VERSION ""

NS_ :

BS_:

BU_:BMS FCS VCU

BO_ 2550398993 BatP1_BMS_PowerSupplyInfo: 8 BMS
 SG_ P1_BMSPwrSuplVlt1 : 7|9@0+ (0.1,0) [0|50] "V" VCU
 SG_ P1_BMSPwrSuplVlt2 : 14|9@0+ (0.1,0) [0|50] "V" VCU
 SG_ P1_ChrgStationAuxPwrSuplVlt : 21|9@0+ (0.1,0) [0|50] "V" VCU
 SG_ P1_BMSKL15ON : 28|1@0+ (1,0) [0|1] "" VCU
 SG_ P1_DCStepState : 27|8@0+ (1,0) [0|255] "" VCU
 SG_ P1_ExtLvWakeup_28VOnly : 35|9@0+ (0.1,0) [0|50] "V" VCU

BO_ 2550464529 BatP1_BMS_PackUsageLimit: 8 BMS
 SG_ P1_PackVltUprLmt : 7|14@0+ (0.1,0) [0|1200] "V" VCU
 SG_ P1_PackVltLoLmt : 9|14@0+ (0.1,0) [0|1200] "V" VCU
 SG_ P1_PackMaxDschrgCrnt : 27|14@0+ (0.1,0) [0|1600] "A" VCU
 SG_ P1_PackMaxChrgCrnt : 45|14@0+ (0.1,0) [0|1600] "A" VCU

BO_ 2550530065 BatP1_BMS_PackPowerCapability: 8 BMS
 SG_ P1_PackDschrgPwrLmt : 7|10@0+ (1,0) [0|1000] "kW" VCU
 SG_ P1_PackDschrgPwrStat : 13|2@0+ (1,0) [0|3] "" VCU
 SG_ P1_PackChrgPwrLmt : 11|10@0+ (1,0) [0|1000] "kW" VCU
 SG_ P1_PackChrgPwrStat : 17|2@0+ (1,0) [0|3] "" VCU

BO_ 2550595601 BatP1_BMS_ChargingInfo: 8 BMS
 SG_ P1_ChrgrCplrStat : 7|1@0+ (1,0) [0|1] "" VCU
 SG_ P1_HVBattChrgSysStatus : 6|4@0+ (1,0) [0|15] "" VCU
 SG_ P1_DCChrgCrntCmd : 2|9@0+ (1,0) [0|500] "A" VCU
 SG_ P1_CC2Vlt : 9|8@0+ (0.1,0) [0|25] "V" VCU
 SG_ P1_DCRcptPosTemp : 17|9@0+ (0.5,-40) [-40|150] "C" VCU
 SG_ P1_DCRcptNegTemp : 24|9@0+ (0.5,-40) [-40|150] "C" VCU
 SG_ P1_Tm2FullChrg : 47|14@0+ (1,0) [0|65535] "min" VCU

BO_ 2550661137 BatP1_BMS_ThermalManagement: 8 BMS
 SG_ P1_Inlet1ClntTemp : 7|11@0+ (0.1,-40) [-40|150] "C" VCU
 SG_ P1_Inlet2ClntTemp : 12|11@0+ (0.1,-40) [-40|150] "C" VCU
 SG_ P1_Outlet1ClntTemp : 17|11@0+ (0.1,-40) [-40|150] "C" VCU
 SG_ P1_Outlet2ClntTemp : 38|11@0+ (0.1,-40) [-40|150] "C" VCU
 SG_ P1_TrgtClntTemp : 43|11@0+ (0.1,-40) [-40|150] "C" VCU
 SG_ P1_TrgtClntFlowRate : 48|9@0+ (0.2,0) [0|100] "C" VCU

BO_ 2550726673 BatP1_BMS_CellVoltMaxMin: 8 BMS
 SG_ P1_MaxCellVlt : 7|13@0+ (0.001,0) [0|5] "V" VCU
 SG_ P1_MaxCellVltNum : 10|9@0+ (1,0) [0|500] "" VCU
 SG_ P1_MinCellVlt : 17|13@0+ (0.001,0) [0|5] "V" VCU
 SG_ P1_MinCellVltNum : 36|9@0+ (1,0) [0|500] "" VCU
 SG_ P1_AvgCellVlt : 43|13@0+ (0.001,0) [0|5] "V" VCU

BO_ 2550792209 BatP1_BMS_CellTempMaxMin: 8 BMS
 SG_ P1_MaxCellTemp : 7|11@0+ (0.1,-40) [-40|150] "C" VCU
 SG_ P1_MaxCellTempNum : 12|9@0+ (1,0) [0|500] "" VCU
 SG_ P1_MinCellTemp : 19|11@0+ (0.1,-40) [-40|150] "C" VCU
 SG_ P1_MinCellTempNum : 24|9@0+ (1,0) [0|500] "" VCU
 SG_ P1_AvgCellTemp : 47|11@0+ (0.1,-40) [-40|150] "C" VCU

BO_ 2550857745 BatP1_BMS_PackFaultInfo1: 8 BMS
 SG_ P1_PackTotFltNum : 7|8@0+ (1,0) [0|200] "" VCU
 SG_ P1_CellOverVoltage : 15|2@0+ (1,0) [0|3] "" VCU
 SG_ P1_CellUnderVoltage : 13|2@0+ (1,0) [0|3] "" VCU
 SG_ P1_CellVoltageDiffHi : 11|1@0+ (1,0) [0|1] "" VCU
 SG_ P1_PackOverVoltage : 10|2@0+ (1,0) [0|3] "" VCU
 SG_ P1_PackUnderVoltage : 8|2@0+ (1,0) [0|3] "" VCU
 SG_ P1_CellOverTemp : 22|2@0+ (1,0) [0|3] "" VCU
 SG_ P1_CellTempLow : 20|1@0+ (1,0) [0|1] "" VCU
 SG_ P1_CellTempDiffHi : 19|1@0+ (1,0) [0|1] "" VCU
 SG_ P1_PackDschrgCrntHi : 18|2@0+ (1,0) [0|3] "" VCU
 SG_ P1_PackChrgCrntHi : 16|2@0+ (1,0) [0|3] "" VCU
 SG_ P1_PackCrnSnsr1OffsetHi : 30|1@0+ (1,0) [0|1] "" VCU
 SG_ P1_HVIsolFlt : 29|2@0+ (1,0) [0|3] "" VCU
 SG_ P1_HVILFlt : 27|1@0+ (1,0) [0|1] "" VCU
 SG_ P1_ThrmlRunaway : 26|1@0+ (1,0) [0|1] "" VCU
 SG_ P1_CellVoltInvalid : 25|1@0+ (1,0) [0|1] "" VCU
 SG_ P1_CellTempInvalid : 24|1@0+ (1,0) [0|1] "" VCU
 SG_ P1_DaisyChainComFlt : 39|1@0+ (1,0) [0|1] "" VCU
 SG_ P1_PackVoltRatFlt : 38|1@0+ (1,0) [0|1] "" VCU
 SG_ P1_CrntSnsr1Invalid : 37|1@0+ (1,0) [0|1] "" VCU
 SG_ P1_CrntSnsr1OOR : 36|1@0+ (1,0) [0|1] "" VCU
 SG_ P1_CrntSnsr2Invalid : 35|1@0+ (1,0) [0|1] "" VCU
 SG_ P1_CrntSnsr2OOR : 34|1@0+ (1,0) [0|1] "" VCU
 SG_ P1_PackCrnSnsr2OffsetHi : 33|1@0+ (1,0) [0|1] "" VCU
 SG_ P1_OutofEnergy : 32|1@0+ (1,0) [0|1] "" VCU
 SG_ P1_IsolDetCircErr : 47|1@0+ (1,0) [0|1] "" VCU
 SG_ P1_HVILCircShortToGND : 46|1@0+ (1,0) [0|1] "" VCU
 SG_ P1_HVILCircShortToPwr : 45|1@0+ (1,0) [0|1] "" VCU

BO_ 2550923281 BatP1_BMS_PackFaultInfo2: 8 BMS
 SG_ P1_MainPosCntctrStkClsd : 7|1@0+ (1,0) [0|1] "" VCU
 SG_ P1_MainPosCntctrStkOpn : 6|1@0+ (1,0) [0|1] "" VCU
 SG_ P1_MainNegCntctr1StkClsd : 5|1@0+ (1,0) [0|1] "" VCU
 SG_ P1_MainNegCntctr1StkOpn : 4|1@0+ (1,0) [0|1] "" VCU
 SG_ P1_MainNegCntctr2StkClsd : 3|1@0+ (1,0) [0|1] "" VCU
 SG_ P1_MainNegCntctr2StkOpn : 2|1@0+ (1,0) [0|1] "" VCU
 SG_ P1_PrechargTmOut : 1|1@0+ (1,0) [0|1] "" VCU
 SG_ P1_PrechrgCrntHi : 0|1@0+ (1,0) [0|1] "" VCU
 SG_ P1_ChrgCplrPosTempHi : 15|1@0+ (1,0) [0|1] "" VCU
 SG_ P1_ChrgCplrNegTempHi : 14|1@0+ (1,0) [0|1] "" VCU
 SG_ P1_BMSPwrSuplVlt1Hi : 13|1@0+ (1,0) [0|1] "" VCU
 SG_ P1_BMSPwrSuplVlt1Lo : 12|1@0+ (1,0) [0|1] "" VCU
 SG_ P1_BMSPwrSuplVlt2Hi : 11|1@0+ (1,0) [0|1] "" VCU
 SG_ P1_BMSPwrSuplVlt2Lo : 10|1@0+ (1,0) [0|1] "" VCU
 SG_ P1_CntctrCirPwrSuplVltLo : 9|1@0+ (1,0) [0|1] "" VCU
 SG_ P1_CntctrCirPwrSuplVltHi : 8|1@0+ (1,0) [0|1] "" VCU
 SG_ P1_CAN1BusOff : 23|1@0+ (1,0) [0|1] "" VCU
 SG_ P1_CAN1BusTmOut : 22|1@0+ (1,0) [0|1] "" VCU
 SG_ P1_CAN2BusOff : 21|1@0+ (1,0) [0|1] "" VCU
 SG_ P1_CAN2BusTmOut : 20|1@0+ (1,0) [0|1] "" VCU
 SG_ P1_CellBalCircTempHi : 19|1@0+ (1,0) [0|1] "" VCU
 SG_ P1_ClntInTempHi : 18|1@0+ (1,0) [0|1] "" VCU
 SG_ P1_ClntOutTempHi : 17|1@0+ (1,0) [0|1] "" VCU
 SG_ P1_CellExtrmUdrVolt : 16|1@0+ (1,0) [0|1] "" VCU
 SG_ P1_CellExtrmOvrVolt : 31|1@0+ (1,0) [0|1] "" VCU
 SG_ P1_Branch1DischrgCrntHi  : 30|1@0+ (1,0) [0|1] "" VCU
 SG_ P1_Branch2DischrgCrntHi  : 29|1@0+ (1,0) [0|1] "" VCU
 SG_ P1_Branch1ChrgCrntHi  : 28|1@0+ (1,0) [0|1] "" VCU
 SG_ P1_Branch2ChrgCrntHi  : 27|1@0+ (1,0) [0|1] "" VCU
 SG_ P1_InitFailed : 26|1@0+ (1,0) [0|1] "" VCU
 SG_ P1_PackErrCode : 25|10@0+ (1,0) [0|1023] "" VCU

BO_ 2550988817 BatP1_BMS_PackConfigInfo: 8 BMS
 SG_ P1_PackTotCellNum : 7|9@0+ (1,0) [0|500] "" VCU
 SG_ P1_PackTotCellTempSnsrNum : 14|9@0+ (1,0) [0|500] "" VCU

BO_ 2552299537 BatP1_BMS_BMSVersion: 8 BMS
 SG_ P1_BMSASWMajVerNum : 7|8@0+ (1,0) [0|9] "" VCU
 SG_ P1_BMSASWMinVerNum : 15|8@0+ (1,0) [0|99] "" VCU
 SG_ P1_BMSASWPatchVerNum : 23|8@0+ (1,0) [0|255] "" VCU
 SG_ P1_BMSBSWMajVerNum : 31|8@0+ (1,0) [0|9] "" VCU
 SG_ P1_BMSBSWMinVerNum : 39|8@0+ (1,0) [0|99] "" VCU
 SG_ P1_BMSBSWPatchVerNum : 47|8@0+ (1,0) [0|255] "" VCU

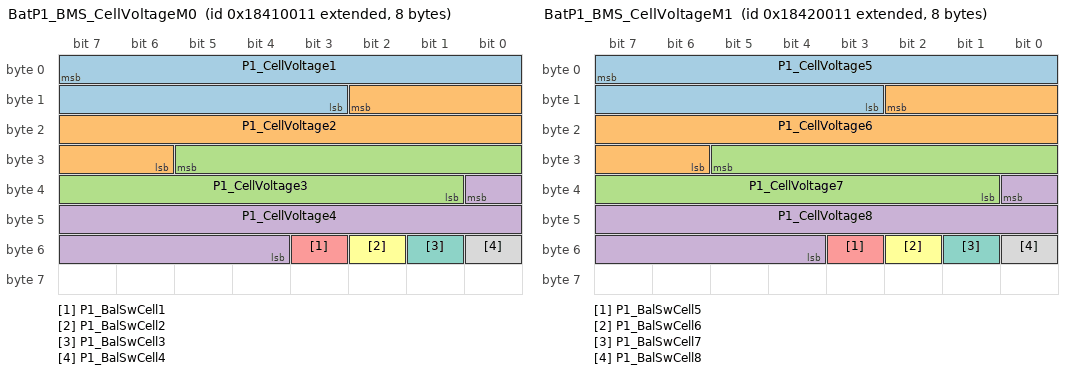
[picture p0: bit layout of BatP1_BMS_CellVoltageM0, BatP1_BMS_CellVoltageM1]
BO_ 2554396689 BatP1_BMS_CellVoltageM0: 8 BMS
 SG_ P1_CellVoltage1 : 7|13@0+ (0.001,0) [0|5] "V" VCU
 SG_ P1_CellVoltage2 : 10|13@0+ (0.001,0) [0|5] "V" VCU
 SG_ P1_CellVoltage3 : 29|13@0+ (0.001,0) [0|5] "V" VCU
 SG_ P1_CellVoltage4 : 32|13@0+ (0.001,0) [0|5] "V" VCU
 SG_ P1_BalSwCell1 : 51|1@0+ (1,0) [0|1] "" VCU
 SG_ P1_BalSwCell2 : 50|1@0+ (1,0) [0|1] "" VCU
 SG_ P1_BalSwCell3 : 49|1@0+ (1,0) [0|1] "" VCU
 SG_ P1_BalSwCell4 : 48|1@0+ (1,0) [0|1] "" VCU

BO_ 2554462225 BatP1_BMS_CellVoltageM1: 8 BMS
 SG_ P1_CellVoltage5 : 7|13@0+ (0.001,0) [0|5] "V" VCU
 SG_ P1_CellVoltage6 : 10|13@0+ (0.001,0) [0|5] "V" VCU
 SG_ P1_CellVoltage7 : 29|13@0+ (0.001,0) [0|5] "V" VCU
 SG_ P1_CellVoltage8 : 32|13@0+ (0.001,0) [0|5] "V" VCU
 SG_ P1_BalSwCell5 : 51|1@0+ (1,0) [0|1] "" VCU
 SG_ P1_BalSwCell6 : 50|1@0+ (1,0) [0|1] "" VCU
 SG_ P1_BalSwCell7 : 49|1@0+ (1,0) [0|1] "" VCU
 SG_ P1_BalSwCell8 : 48|1@0+ (1,0) [0|1] "" VCU

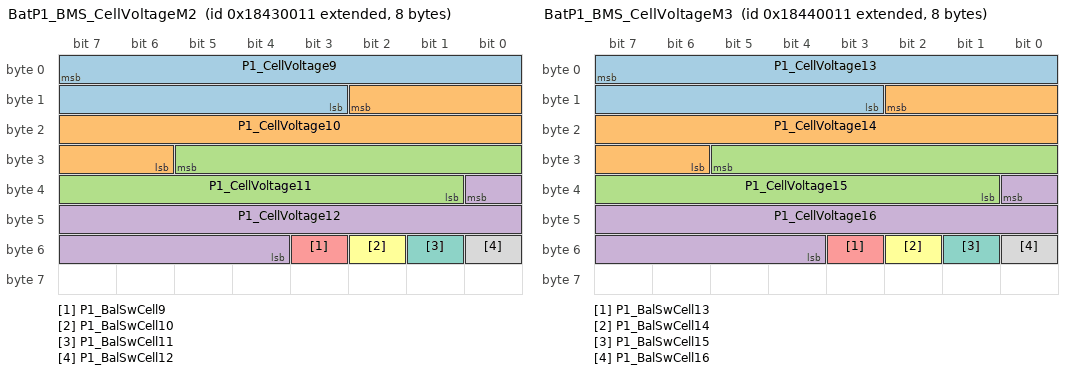
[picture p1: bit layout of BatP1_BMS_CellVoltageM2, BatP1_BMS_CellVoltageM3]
BO_ 2554527761 BatP1_BMS_CellVoltageM2: 8 BMS
 SG_ P1_CellVoltage9 : 7|13@0+ (0.001,0) [0|5] "V" VCU
 SG_ P1_CellVoltage10 : 10|13@0+ (0.001,0) [0|5] "V" VCU
 SG_ P1_CellVoltage11 : 29|13@0+ (0.001,0) [0|5] "V" VCU
 SG_ P1_CellVoltage12 : 32|13@0+ (0.001,0) [0|5] "V" VCU
 SG_ P1_BalSwCell9 : 51|1@0+ (1,0) [0|1] "" VCU
 SG_ P1_BalSwCell10 : 50|1@0+ (1,0) [0|1] "" VCU
 SG_ P1_BalSwCell11 : 49|1@0+ (1,0) [0|1] "" VCU
 SG_ P1_BalSwCell12 : 48|1@0+ (1,0) [0|1] "" VCU

BO_ 2554593297 BatP1_BMS_CellVoltageM3: 8 BMS
 SG_ P1_CellVoltage13 : 7|13@0+ (0.001,0) [0|5] "V" VCU
 SG_ P1_CellVoltage14 : 10|13@0+ (0.001,0) [0|5] "V" VCU
 SG_ P1_CellVoltage15 : 29|13@0+ (0.001,0) [0|5] "V" VCU
 SG_ P1_CellVoltage16 : 32|13@0+ (0.001,0) [0|5] "V" VCU
 SG_ P1_BalSwCell13 : 51|1@0+ (1,0) [0|1] "" VCU
 SG_ P1_BalSwCell14 : 50|1@0+ (1,0) [0|1] "" VCU
 SG_ P1_BalSwCell15 : 49|1@0+ (1,0) [0|1] "" VCU
 SG_ P1_BalSwCell16 : 48|1@0+ (1,0) [0|1] "" VCU

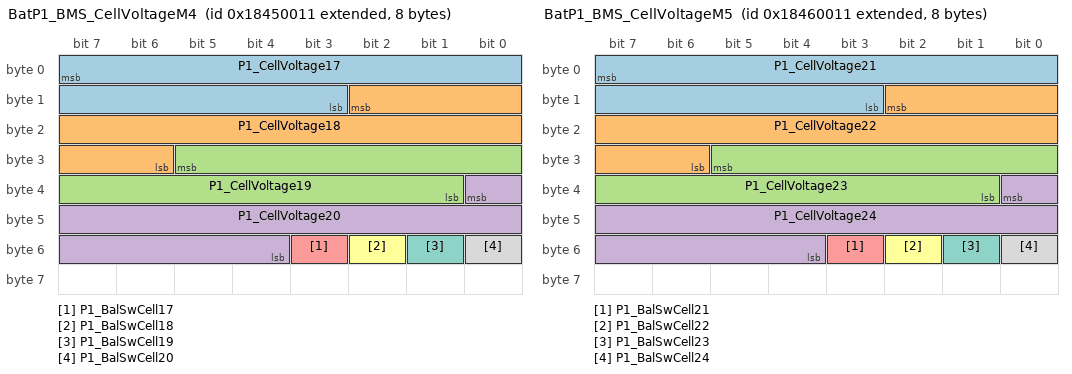
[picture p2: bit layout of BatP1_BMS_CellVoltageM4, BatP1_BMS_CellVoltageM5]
BO_ 2554658833 BatP1_BMS_CellVoltageM4: 8 BMS
 SG_ P1_CellVoltage17 : 7|13@0+ (0.001,0) [0|5] "V" VCU
 SG_ P1_CellVoltage18 : 10|13@0+ (0.001,0) [0|5] "V" VCU
 SG_ P1_CellVoltage19 : 29|13@0+ (0.001,0) [0|5] "V" VCU
 SG_ P1_CellVoltage20 : 32|13@0+ (0.001,0) [0|5] "V" VCU
 SG_ P1_BalSwCell17 : 51|1@0+ (1,0) [0|1] "" VCU
 SG_ P1_BalSwCell18 : 50|1@0+ (1,0) [0|1] "" VCU
 SG_ P1_BalSwCell19 : 49|1@0+ (1,0) [0|1] "" VCU
 SG_ P1_BalSwCell20 : 48|1@0+ (1,0) [0|1] "" VCU

BO_ 2554724369 BatP1_BMS_CellVoltageM5: 8 BMS
 SG_ P1_CellVoltage21 : 7|13@0+ (0.001,0) [0|5] "V" VCU
 SG_ P1_CellVoltage22 : 10|13@0+ (0.001,0) [0|5] "V" VCU
 SG_ P1_CellVoltage23 : 29|13@0+ (0.001,0) [0|5] "V" VCU
 SG_ P1_CellVoltage24 : 32|13@0+ (0.001,0) [0|5] "V" VCU
 SG_ P1_BalSwCell21 : 51|1@0+ (1,0) [0|1] "" VCU
 SG_ P1_BalSwCell22 : 50|1@0+ (1,0) [0|1] "" VCU
 SG_ P1_BalSwCell23 : 49|1@0+ (1,0) [0|1] "" VCU
 SG_ P1_BalSwCell24 : 48|1@0+ (1,0) [0|1] "" VCU

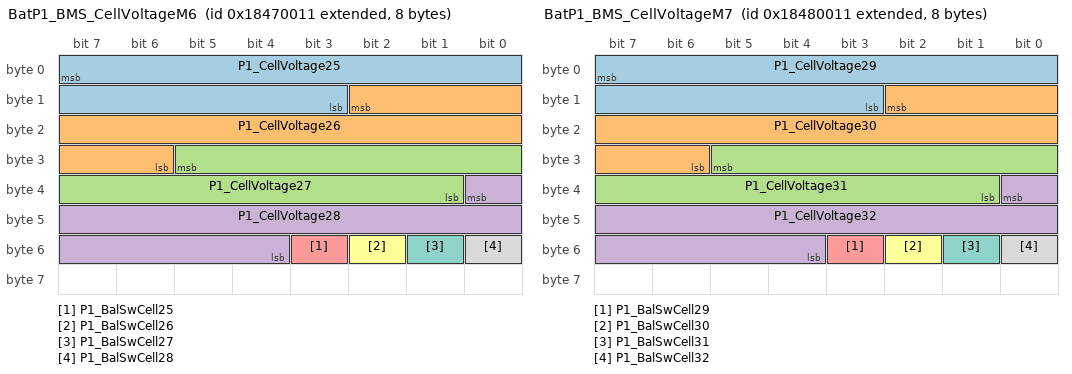
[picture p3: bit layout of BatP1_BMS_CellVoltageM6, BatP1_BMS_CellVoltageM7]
BO_ 2554789905 BatP1_BMS_CellVoltageM6: 8 BMS
 SG_ P1_CellVoltage25 : 7|13@0+ (0.001,0) [0|5] "V" VCU
 SG_ P1_CellVoltage26 : 10|13@0+ (0.001,0) [0|5] "V" VCU
 SG_ P1_CellVoltage27 : 29|13@0+ (0.001,0) [0|5] "V" VCU
 SG_ P1_CellVoltage28 : 32|13@0+ (0.001,0) [0|5] "V" VCU
 SG_ P1_BalSwCell25 : 51|1@0+ (1,0) [0|1] "" VCU
 SG_ P1_BalSwCell26 : 50|1@0+ (1,0) [0|1] "" VCU
 SG_ P1_BalSwCell27 : 49|1@0+ (1,0) [0|1] "" VCU
 SG_ P1_BalSwCell28 : 48|1@0+ (1,0) [0|1] "" VCU

BO_ 2554855441 BatP1_BMS_CellVoltageM7: 8 BMS
 SG_ P1_CellVoltage29 : 7|13@0+ (0.001,0) [0|5] "V" VCU
 SG_ P1_CellVoltage30 : 10|13@0+ (0.001,0) [0|5] "V" VCU
 SG_ P1_CellVoltage31 : 29|13@0+ (0.001,0) [0|5] "V" VCU
 SG_ P1_CellVoltage32 : 32|13@0+ (0.001,0) [0|5] "V" VCU
 SG_ P1_BalSwCell29 : 51|1@0+ (1,0) [0|1] "" VCU
 SG_ P1_BalSwCell30 : 50|1@0+ (1,0) [0|1] "" VCU
 SG_ P1_BalSwCell31 : 49|1@0+ (1,0) [0|1] "" VCU
 SG_ P1_BalSwCell32 : 48|1@0+ (1,0) [0|1] "" VCU

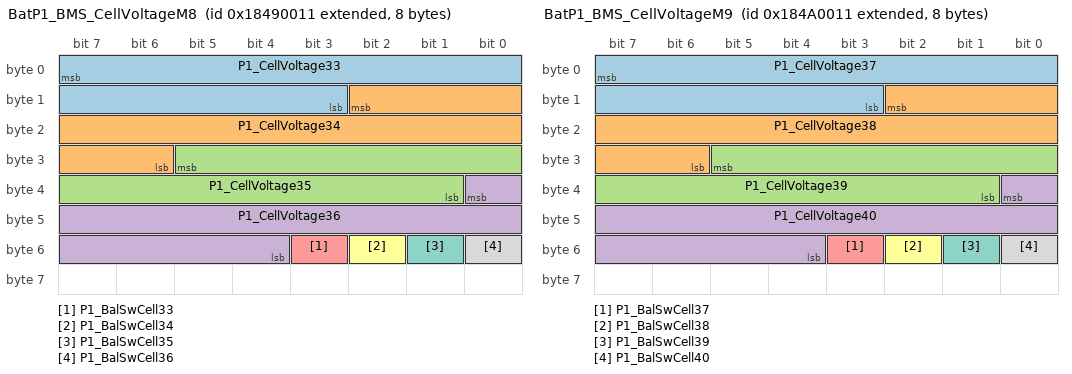
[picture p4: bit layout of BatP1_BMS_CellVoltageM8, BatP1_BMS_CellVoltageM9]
BO_ 2554920977 BatP1_BMS_CellVoltageM8: 8 BMS
 SG_ P1_CellVoltage33 : 7|13@0+ (0.001,0) [0|5] "V" VCU
 SG_ P1_CellVoltage34 : 10|13@0+ (0.001,0) [0|5] "V" VCU
 SG_ P1_CellVoltage35 : 29|13@0+ (0.001,0) [0|5] "V" VCU
 SG_ P1_CellVoltage36 : 32|13@0+ (0.001,0) [0|5] "V" VCU
 SG_ P1_BalSwCell33 : 51|1@0+ (1,0) [0|1] "" VCU
 SG_ P1_BalSwCell34 : 50|1@0+ (1,0) [0|1] "" VCU
 SG_ P1_BalSwCell35 : 49|1@0+ (1,0) [0|1] "" VCU
 SG_ P1_BalSwCell36 : 48|1@0+ (1,0) [0|1] "" VCU

BO_ 2554986513 BatP1_BMS_CellVoltageM9: 8 BMS
 SG_ P1_CellVoltage37 : 7|13@0+ (0.001,0) [0|5] "V" VCU
 SG_ P1_CellVoltage38 : 10|13@0+ (0.001,0) [0|5] "V" VCU
 SG_ P1_CellVoltage39 : 29|13@0+ (0.001,0) [0|5] "V" VCU
 SG_ P1_CellVoltage40 : 32|13@0+ (0.001,0) [0|5] "V" VCU
 SG_ P1_BalSwCell37 : 51|1@0+ (1,0) [0|1] "" VCU
 SG_ P1_BalSwCell38 : 50|1@0+ (1,0) [0|1] "" VCU
 SG_ P1_BalSwCell39 : 49|1@0+ (1,0) [0|1] "" VCU
 SG_ P1_BalSwCell40 : 48|1@0+ (1,0) [0|1] "" VCU

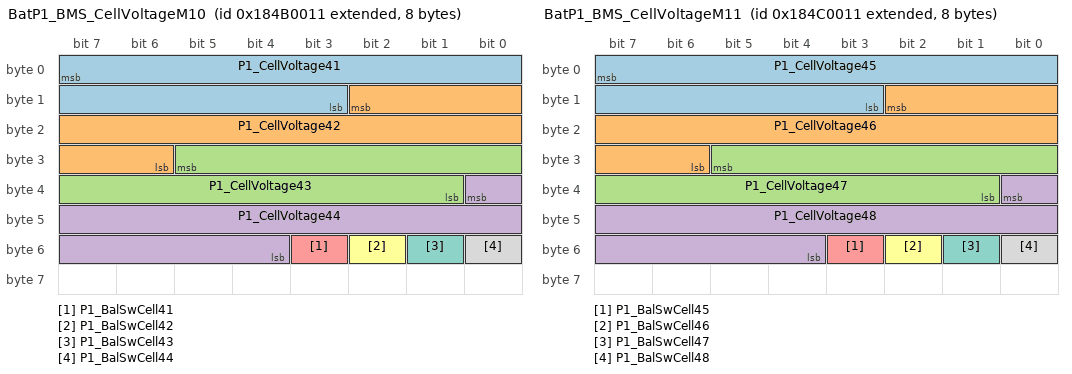
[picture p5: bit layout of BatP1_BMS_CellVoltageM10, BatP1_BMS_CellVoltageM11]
BO_ 2555052049 BatP1_BMS_CellVoltageM10: 8 BMS
 SG_ P1_CellVoltage41 : 7|13@0+ (0.001,0) [0|5] "V" VCU
 SG_ P1_CellVoltage42 : 10|13@0+ (0.001,0) [0|5] "V" VCU
 SG_ P1_CellVoltage43 : 29|13@0+ (0.001,0) [0|5] "V" VCU
 SG_ P1_CellVoltage44 : 32|13@0+ (0.001,0) [0|5] "V" VCU
 SG_ P1_BalSwCell41 : 51|1@0+ (1,0) [0|1] "" VCU
 SG_ P1_BalSwCell42 : 50|1@0+ (1,0) [0|1] "" VCU
 SG_ P1_BalSwCell43 : 49|1@0+ (1,0) [0|1] "" VCU
 SG_ P1_BalSwCell44 : 48|1@0+ (1,0) [0|1] "" VCU

BO_ 2555117585 BatP1_BMS_CellVoltageM11: 8 BMS
 SG_ P1_CellVoltage45 : 7|13@0+ (0.001,0) [0|5] "V" VCU
 SG_ P1_CellVoltage46 : 10|13@0+ (0.001,0) [0|5] "V" VCU
 SG_ P1_CellVoltage47 : 29|13@0+ (0.001,0) [0|5] "V" VCU
 SG_ P1_CellVoltage48 : 32|13@0+ (0.001,0) [0|5] "V" VCU
 SG_ P1_BalSwCell45 : 51|1@0+ (1,0) [0|1] "" VCU
 SG_ P1_BalSwCell46 : 50|1@0+ (1,0) [0|1] "" VCU
 SG_ P1_BalSwCell47 : 49|1@0+ (1,0) [0|1] "" VCU
 SG_ P1_BalSwCell48 : 48|1@0+ (1,0) [0|1] "" VCU

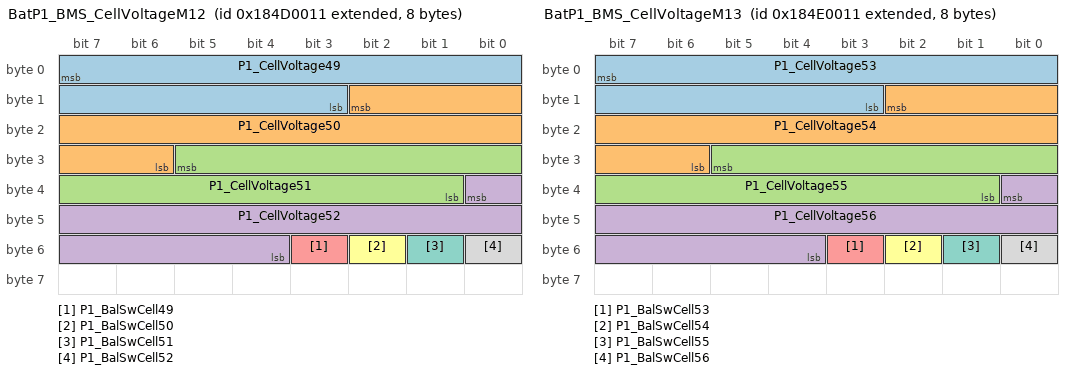
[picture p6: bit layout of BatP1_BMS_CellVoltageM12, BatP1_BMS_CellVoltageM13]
BO_ 2555183121 BatP1_BMS_CellVoltageM12: 8 BMS
 SG_ P1_CellVoltage49 : 7|13@0+ (0.001,0) [0|5] "V" VCU
 SG_ P1_CellVoltage50 : 10|13@0+ (0.001,0) [0|5] "V" VCU
 SG_ P1_CellVoltage51 : 29|13@0+ (0.001,0) [0|5] "V" VCU
 SG_ P1_CellVoltage52 : 32|13@0+ (0.001,0) [0|5] "V" VCU
 SG_ P1_BalSwCell49 : 51|1@0+ (1,0) [0|1] "" VCU
 SG_ P1_BalSwCell50 : 50|1@0+ (1,0) [0|1] "" VCU
 SG_ P1_BalSwCell51 : 49|1@0+ (1,0) [0|1] "" VCU
 SG_ P1_BalSwCell52 : 48|1@0+ (1,0) [0|1] "" VCU

BO_ 2555248657 BatP1_BMS_CellVoltageM13: 8 BMS
 SG_ P1_CellVoltage53 : 7|13@0+ (0.001,0) [0|5] "V" VCU
 SG_ P1_CellVoltage54 : 10|13@0+ (0.001,0) [0|5] "V" VCU
 SG_ P1_CellVoltage55 : 29|13@0+ (0.001,0) [0|5] "V" VCU
 SG_ P1_CellVoltage56 : 32|13@0+ (0.001,0) [0|5] "V" VCU
 SG_ P1_BalSwCell53 : 51|1@0+ (1,0) [0|1] "" VCU
 SG_ P1_BalSwCell54 : 50|1@0+ (1,0) [0|1] "" VCU
 SG_ P1_BalSwCell55 : 49|1@0+ (1,0) [0|1] "" VCU
 SG_ P1_BalSwCell56 : 48|1@0+ (1,0) [0|1] "" VCU

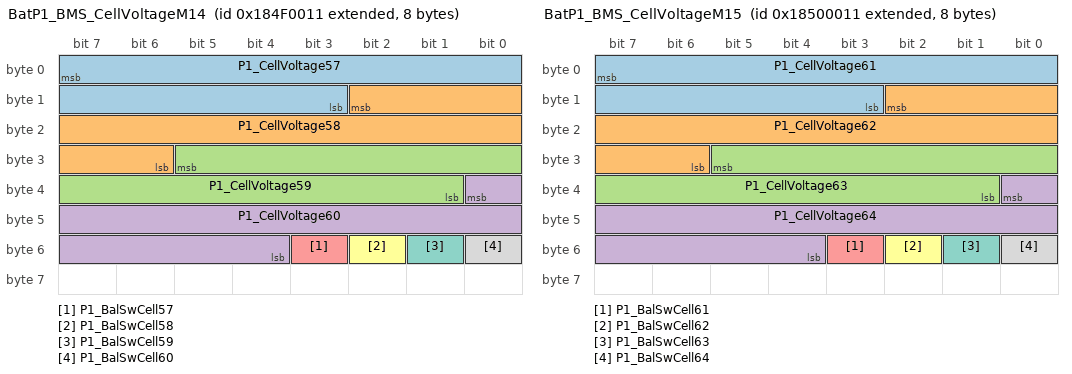
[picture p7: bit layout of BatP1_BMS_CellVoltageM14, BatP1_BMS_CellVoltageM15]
BO_ 2555314193 BatP1_BMS_CellVoltageM14: 8 BMS
 SG_ P1_CellVoltage57 : 7|13@0+ (0.001,0) [0|5] "V" VCU
 SG_ P1_CellVoltage58 : 10|13@0+ (0.001,0) [0|5] "V" VCU
 SG_ P1_CellVoltage59 : 29|13@0+ (0.001,0) [0|5] "V" VCU
 SG_ P1_CellVoltage60 : 32|13@0+ (0.001,0) [0|5] "V" VCU
 SG_ P1_BalSwCell57 : 51|1@0+ (1,0) [0|1] "" VCU
 SG_ P1_BalSwCell58 : 50|1@0+ (1,0) [0|1] "" VCU
 SG_ P1_BalSwCell59 : 49|1@0+ (1,0) [0|1] "" VCU
 SG_ P1_BalSwCell60 : 48|1@0+ (1,0) [0|1] "" VCU

BO_ 2555379729 BatP1_BMS_CellVoltageM15: 8 BMS
 SG_ P1_CellVoltage61 : 7|13@0+ (0.001,0) [0|5] "V" VCU
 SG_ P1_CellVoltage62 : 10|13@0+ (0.001,0) [0|5] "V" VCU
 SG_ P1_CellVoltage63 : 29|13@0+ (0.001,0) [0|5] "V" VCU
 SG_ P1_CellVoltage64 : 32|13@0+ (0.001,0) [0|5] "V" VCU
 SG_ P1_BalSwCell61 : 51|1@0+ (1,0) [0|1] "" VCU
 SG_ P1_BalSwCell62 : 50|1@0+ (1,0) [0|1] "" VCU
 SG_ P1_BalSwCell63 : 49|1@0+ (1,0) [0|1] "" VCU
 SG_ P1_BalSwCell64 : 48|1@0+ (1,0) [0|1] "" VCU

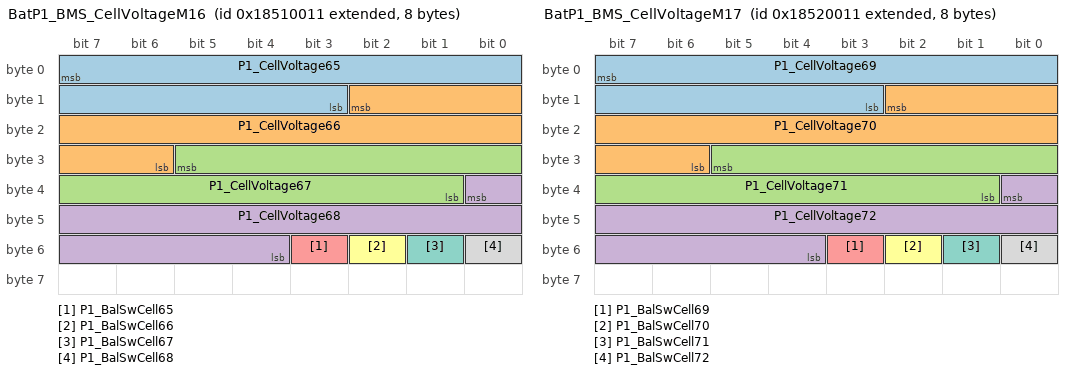
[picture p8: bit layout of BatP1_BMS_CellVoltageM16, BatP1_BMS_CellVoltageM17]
BO_ 2555445265 BatP1_BMS_CellVoltageM16: 8 BMS
 SG_ P1_CellVoltage65 : 7|13@0+ (0.001,0) [0|5] "V" VCU
 SG_ P1_CellVoltage66 : 10|13@0+ (0.001,0) [0|5] "V" VCU
 SG_ P1_CellVoltage67 : 29|13@0+ (0.001,0) [0|5] "V" VCU
 SG_ P1_CellVoltage68 : 32|13@0+ (0.001,0) [0|5] "V" VCU
 SG_ P1_BalSwCell65 : 51|1@0+ (1,0) [0|1] "" VCU
 SG_ P1_BalSwCell66 : 50|1@0+ (1,0) [0|1] "" VCU
 SG_ P1_BalSwCell67 : 49|1@0+ (1,0) [0|1] "" VCU
 SG_ P1_BalSwCell68 : 48|1@0+ (1,0) [0|1] "" VCU

BO_ 2555510801 BatP1_BMS_CellVoltageM17: 8 BMS
 SG_ P1_CellVoltage69 : 7|13@0+ (0.001,0) [0|5] "V" VCU
 SG_ P1_CellVoltage70 : 10|13@0+ (0.001,0) [0|5] "V" VCU
 SG_ P1_CellVoltage71 : 29|13@0+ (0.001,0) [0|5] "V" VCU
 SG_ P1_CellVoltage72 : 32|13@0+ (0.001,0) [0|5] "V" VCU
 SG_ P1_BalSwCell69 : 51|1@0+ (1,0) [0|1] "" VCU
 SG_ P1_BalSwCell70 : 50|1@0+ (1,0) [0|1] "" VCU
 SG_ P1_BalSwCell71 : 49|1@0+ (1,0) [0|1] "" VCU
 SG_ P1_BalSwCell72 : 48|1@0+ (1,0) [0|1] "" VCU

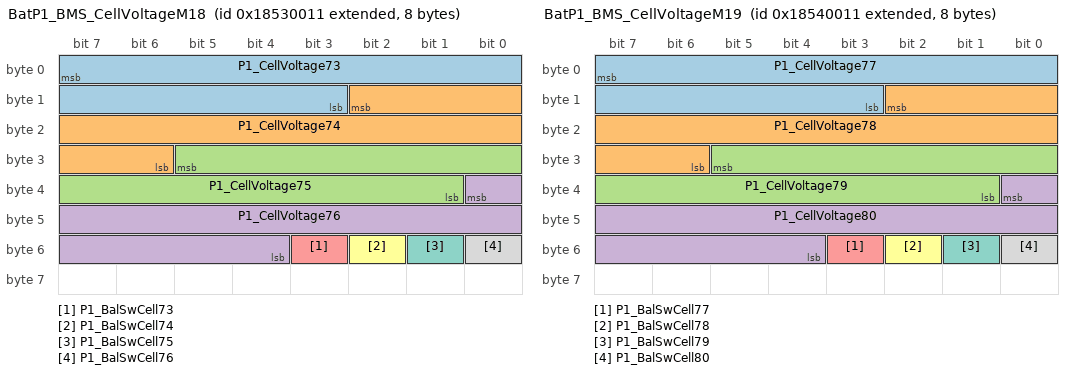
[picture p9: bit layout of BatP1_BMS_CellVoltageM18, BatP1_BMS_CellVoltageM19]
BO_ 2555576337 BatP1_BMS_CellVoltageM18: 8 BMS
 SG_ P1_CellVoltage73 : 7|13@0+ (0.001,0) [0|5] "V" VCU
 SG_ P1_CellVoltage74 : 10|13@0+ (0.001,0) [0|5] "V" VCU
 SG_ P1_CellVoltage75 : 29|13@0+ (0.001,0) [0|5] "V" VCU
 SG_ P1_CellVoltage76 : 32|13@0+ (0.001,0) [0|5] "V" VCU
 SG_ P1_BalSwCell73 : 51|1@0+ (1,0) [0|1] "" VCU
 SG_ P1_BalSwCell74 : 50|1@0+ (1,0) [0|1] "" VCU
 SG_ P1_BalSwCell75 : 49|1@0+ (1,0) [0|1] "" VCU
 SG_ P1_BalSwCell76 : 48|1@0+ (1,0) [0|1] "" VCU

BO_ 2555641873 BatP1_BMS_CellVoltageM19: 8 BMS
 SG_ P1_CellVoltage77 : 7|13@0+ (0.001,0) [0|5] "V" VCU
 SG_ P1_CellVoltage78 : 10|13@0+ (0.001,0) [0|5] "V" VCU
 SG_ P1_CellVoltage79 : 29|13@0+ (0.001,0) [0|5] "V" VCU
 SG_ P1_CellVoltage80 : 32|13@0+ (0.001,0) [0|5] "V" VCU
 SG_ P1_BalSwCell77 : 51|1@0+ (1,0) [0|1] "" VCU
 SG_ P1_BalSwCell78 : 50|1@0+ (1,0) [0|1] "" VCU
 SG_ P1_BalSwCell79 : 49|1@0+ (1,0) [0|1] "" VCU
 SG_ P1_BalSwCell80 : 48|1@0+ (1,0) [0|1] "" VCU

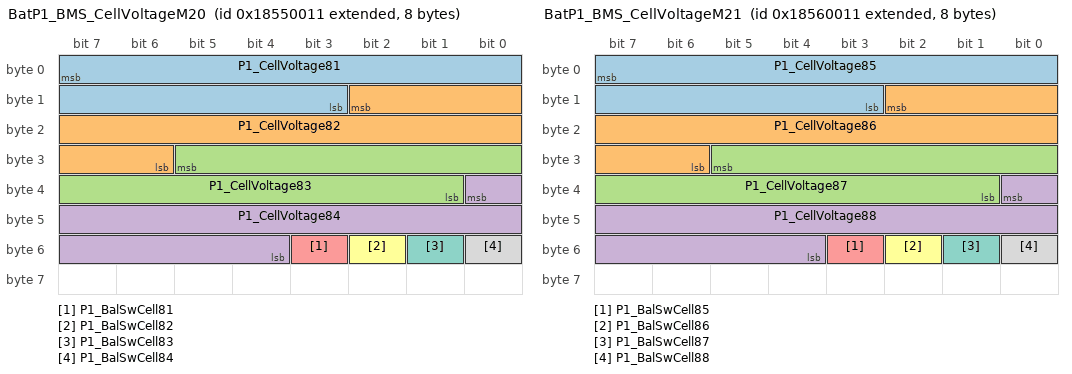
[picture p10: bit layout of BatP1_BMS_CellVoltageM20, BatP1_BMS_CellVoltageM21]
BO_ 2555707409 BatP1_BMS_CellVoltageM20: 8 BMS
 SG_ P1_CellVoltage81 : 7|13@0+ (0.001,0) [0|5] "V" VCU
 SG_ P1_CellVoltage82 : 10|13@0+ (0.001,0) [0|5] "V" VCU
 SG_ P1_CellVoltage83 : 29|13@0+ (0.001,0) [0|5] "V" VCU
 SG_ P1_CellVoltage84 : 32|13@0+ (0.001,0) [0|5] "V" VCU
 SG_ P1_BalSwCell81 : 51|1@0+ (1,0) [0|1] "" VCU
 SG_ P1_BalSwCell82 : 50|1@0+ (1,0) [0|1] "" VCU
 SG_ P1_BalSwCell83 : 49|1@0+ (1,0) [0|1] "" VCU
 SG_ P1_BalSwCell84 : 48|1@0+ (1,0) [0|1] "" VCU

BO_ 2555772945 BatP1_BMS_CellVoltageM21: 8 BMS
 SG_ P1_CellVoltage85 : 7|13@0+ (0.001,0) [0|5] "V" VCU
 SG_ P1_CellVoltage86 : 10|13@0+ (0.001,0) [0|5] "V" VCU
 SG_ P1_CellVoltage87 : 29|13@0+ (0.001,0) [0|5] "V" VCU
 SG_ P1_CellVoltage88 : 32|13@0+ (0.001,0) [0|5] "V" VCU
 SG_ P1_BalSwCell85 : 51|1@0+ (1,0) [0|1] "" VCU
 SG_ P1_BalSwCell86 : 50|1@0+ (1,0) [0|1] "" VCU
 SG_ P1_BalSwCell87 : 49|1@0+ (1,0) [0|1] "" VCU
 SG_ P1_BalSwCell88 : 48|1@0+ (1,0) [0|1] "" VCU

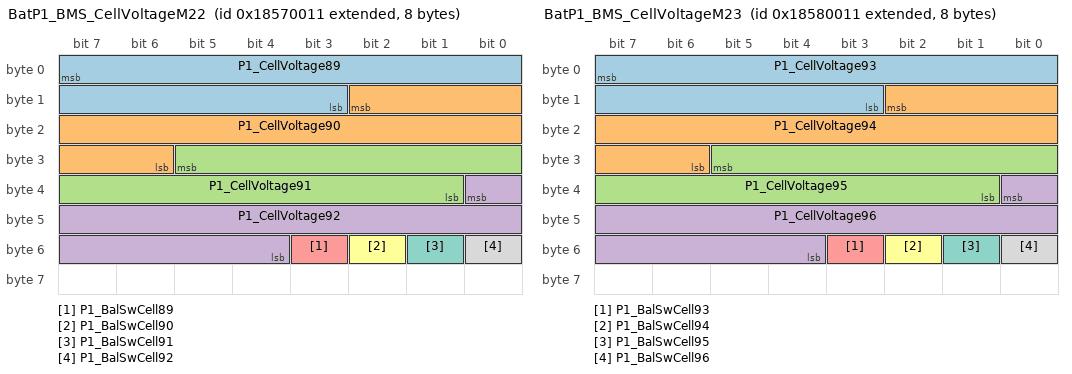
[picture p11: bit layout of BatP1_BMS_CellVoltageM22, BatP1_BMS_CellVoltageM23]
BO_ 2555838481 BatP1_BMS_CellVoltageM22: 8 BMS
 SG_ P1_CellVoltage89 : 7|13@0+ (0.001,0) [0|5] "V" VCU
 SG_ P1_CellVoltage90 : 10|13@0+ (0.001,0) [0|5] "V" VCU
 SG_ P1_CellVoltage91 : 29|13@0+ (0.001,0) [0|5] "V" VCU
 SG_ P1_CellVoltage92 : 32|13@0+ (0.001,0) [0|5] "V" VCU
 SG_ P1_BalSwCell89 : 51|1@0+ (1,0) [0|1] "" VCU
 SG_ P1_BalSwCell90 : 50|1@0+ (1,0) [0|1] "" VCU
 SG_ P1_BalSwCell91 : 49|1@0+ (1,0) [0|1] "" VCU
 SG_ P1_BalSwCell92 : 48|1@0+ (1,0) [0|1] "" VCU

BO_ 2555904017 BatP1_BMS_CellVoltageM23: 8 BMS
 SG_ P1_CellVoltage93 : 7|13@0+ (0.001,0) [0|5] "V" VCU
 SG_ P1_CellVoltage94 : 10|13@0+ (0.001,0) [0|5] "V" VCU
 SG_ P1_CellVoltage95 : 29|13@0+ (0.001,0) [0|5] "V" VCU
 SG_ P1_CellVoltage96 : 32|13@0+ (0.001,0) [0|5] "V" VCU
 SG_ P1_BalSwCell93 : 51|1@0+ (1,0) [0|1] "" VCU
 SG_ P1_BalSwCell94 : 50|1@0+ (1,0) [0|1] "" VCU
 SG_ P1_BalSwCell95 : 49|1@0+ (1,0) [0|1] "" VCU
 SG_ P1_BalSwCell96 : 48|1@0+ (1,0) [0|1] "" VCU

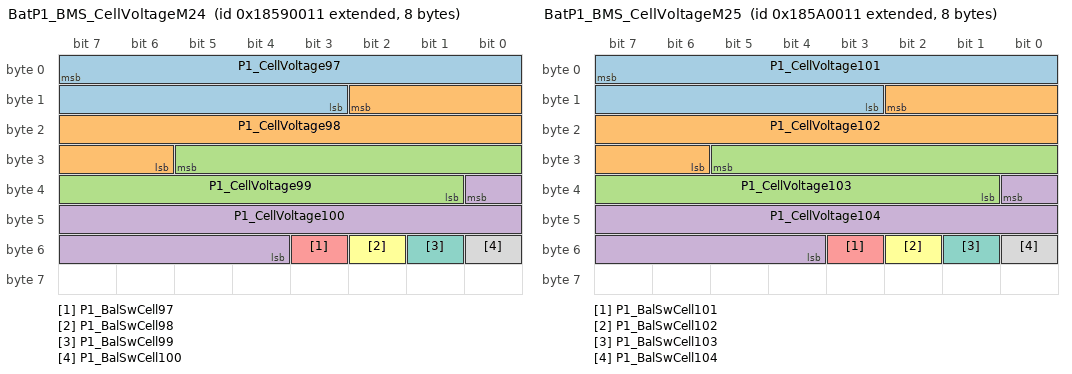
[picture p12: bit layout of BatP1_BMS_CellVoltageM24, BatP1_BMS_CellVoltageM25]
BO_ 2555969553 BatP1_BMS_CellVoltageM24: 8 BMS
 SG_ P1_CellVoltage97 : 7|13@0+ (0.001,0) [0|5] "V" VCU
 SG_ P1_CellVoltage98 : 10|13@0+ (0.001,0) [0|5] "V" VCU
 SG_ P1_CellVoltage99 : 29|13@0+ (0.001,0) [0|5] "V" VCU
 SG_ P1_CellVoltage100 : 32|13@0+ (0.001,0) [0|5] "V" VCU
 SG_ P1_BalSwCell97 : 51|1@0+ (1,0) [0|1] "" VCU
 SG_ P1_BalSwCell98 : 50|1@0+ (1,0) [0|1] "" VCU
 SG_ P1_BalSwCell99 : 49|1@0+ (1,0) [0|1] "" VCU
 SG_ P1_BalSwCell100 : 48|1@0+ (1,0) [0|1] "" VCU

BO_ 2556035089 BatP1_BMS_CellVoltageM25: 8 BMS
 SG_ P1_CellVoltage101 : 7|13@0+ (0.001,0) [0|5] "V" VCU
 SG_ P1_CellVoltage102 : 10|13@0+ (0.001,0) [0|5] "V" VCU
 SG_ P1_CellVoltage103 : 29|13@0+ (0.001,0) [0|5] "V" VCU
 SG_ P1_CellVoltage104 : 32|13@0+ (0.001,0) [0|5] "V" VCU
 SG_ P1_BalSwCell101 : 51|1@0+ (1,0) [0|1] "" VCU
 SG_ P1_BalSwCell102 : 50|1@0+ (1,0) [0|1] "" VCU
 SG_ P1_BalSwCell103 : 49|1@0+ (1,0) [0|1] "" VCU
 SG_ P1_BalSwCell104 : 48|1@0+ (1,0) [0|1] "" VCU

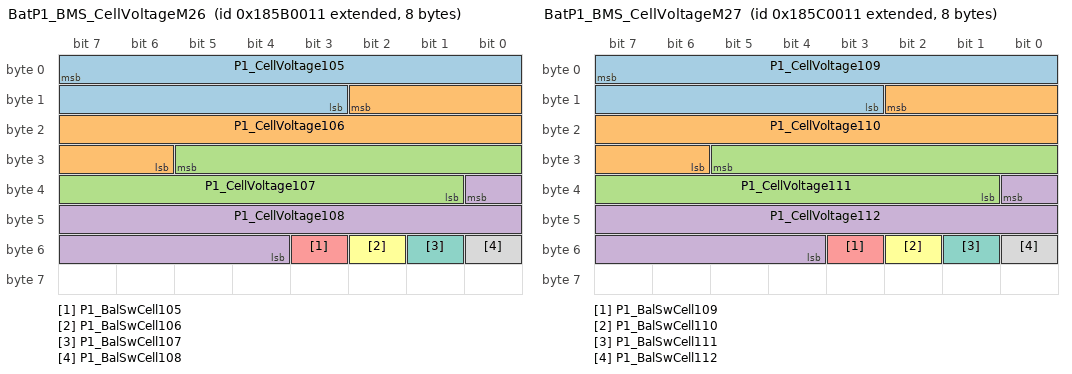
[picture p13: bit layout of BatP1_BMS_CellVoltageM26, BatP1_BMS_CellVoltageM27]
BO_ 2556100625 BatP1_BMS_CellVoltageM26: 8 BMS
 SG_ P1_CellVoltage105 : 7|13@0+ (0.001,0) [0|5] "V" VCU
 SG_ P1_CellVoltage106 : 10|13@0+ (0.001,0) [0|5] "V" VCU
 SG_ P1_CellVoltage107 : 29|13@0+ (0.001,0) [0|5] "V" VCU
 SG_ P1_CellVoltage108 : 32|13@0+ (0.001,0) [0|5] "V" VCU
 SG_ P1_BalSwCell105 : 51|1@0+ (1,0) [0|1] "" VCU
 SG_ P1_BalSwCell106 : 50|1@0+ (1,0) [0|1] "" VCU
 SG_ P1_BalSwCell107 : 49|1@0+ (1,0) [0|1] "" VCU
 SG_ P1_BalSwCell108 : 48|1@0+ (1,0) [0|1] "" VCU

BO_ 2556166161 BatP1_BMS_CellVoltageM27: 8 BMS
 SG_ P1_CellVoltage109 : 7|13@0+ (0.001,0) [0|5] "V" VCU
 SG_ P1_CellVoltage110 : 10|13@0+ (0.001,0) [0|5] "V" VCU
 SG_ P1_CellVoltage111 : 29|13@0+ (0.001,0) [0|5] "V" VCU
 SG_ P1_CellVoltage112 : 32|13@0+ (0.001,0) [0|5] "V" VCU
 SG_ P1_BalSwCell109 : 51|1@0+ (1,0) [0|1] "" VCU
 SG_ P1_BalSwCell110 : 50|1@0+ (1,0) [0|1] "" VCU
 SG_ P1_BalSwCell111 : 49|1@0+ (1,0) [0|1] "" VCU
 SG_ P1_BalSwCell112 : 48|1@0+ (1,0) [0|1] "" VCU

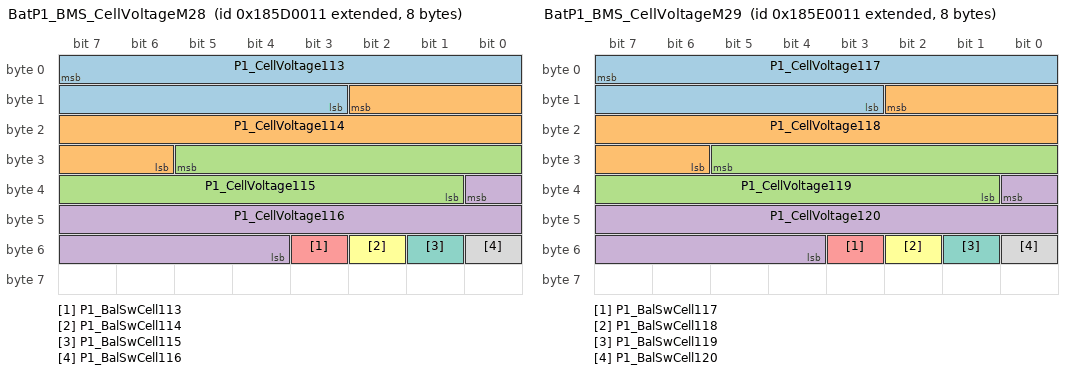
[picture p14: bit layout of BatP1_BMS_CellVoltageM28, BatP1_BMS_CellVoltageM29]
BO_ 2556231697 BatP1_BMS_CellVoltageM28: 8 BMS
 SG_ P1_CellVoltage113 : 7|13@0+ (0.001,0) [0|5] "V" VCU
 SG_ P1_CellVoltage114 : 10|13@0+ (0.001,0) [0|5] "V" VCU
 SG_ P1_CellVoltage115 : 29|13@0+ (0.001,0) [0|5] "V" VCU
 SG_ P1_CellVoltage116 : 32|13@0+ (0.001,0) [0|5] "V" VCU
 SG_ P1_BalSwCell113 : 51|1@0+ (1,0) [0|1] "" VCU
 SG_ P1_BalSwCell114 : 50|1@0+ (1,0) [0|1] "" VCU
 SG_ P1_BalSwCell115 : 49|1@0+ (1,0) [0|1] "" VCU
 SG_ P1_BalSwCell116 : 48|1@0+ (1,0) [0|1] "" VCU

BO_ 2556297233 BatP1_BMS_CellVoltageM29: 8 BMS
 SG_ P1_CellVoltage117 : 7|13@0+ (0.001,0) [0|5] "V" VCU
 SG_ P1_CellVoltage118 : 10|13@0+ (0.001,0) [0|5] "V" VCU
 SG_ P1_CellVoltage119 : 29|13@0+ (0.001,0) [0|5] "V" VCU
 SG_ P1_CellVoltage120 : 32|13@0+ (0.001,0) [0|5] "V" VCU
 SG_ P1_BalSwCell117 : 51|1@0+ (1,0) [0|1] "" VCU
 SG_ P1_BalSwCell118 : 50|1@0+ (1,0) [0|1] "" VCU
 SG_ P1_BalSwCell119 : 49|1@0+ (1,0) [0|1] "" VCU
 SG_ P1_BalSwCell120 : 48|1@0+ (1,0) [0|1] "" VCU

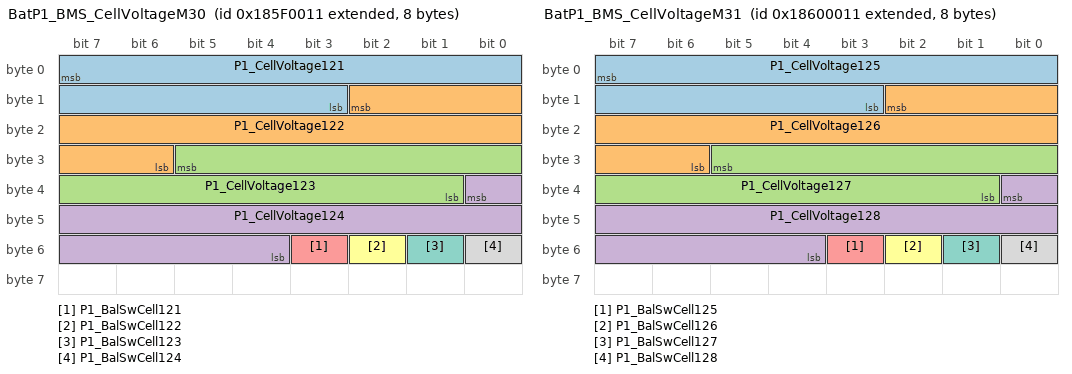
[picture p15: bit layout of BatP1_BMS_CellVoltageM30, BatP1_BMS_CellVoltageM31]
BO_ 2556362769 BatP1_BMS_CellVoltageM30: 8 BMS
 SG_ P1_CellVoltage121 : 7|13@0+ (0.001,0) [0|5] "V" VCU
 SG_ P1_CellVoltage122 : 10|13@0+ (0.001,0) [0|5] "V" VCU
 SG_ P1_CellVoltage123 : 29|13@0+ (0.001,0) [0|5] "V" VCU
 SG_ P1_CellVoltage124 : 32|13@0+ (0.001,0) [0|5] "V" VCU
 SG_ P1_BalSwCell121 : 51|1@0+ (1,0) [0|1] "" VCU
 SG_ P1_BalSwCell122 : 50|1@0+ (1,0) [0|1] "" VCU
 SG_ P1_BalSwCell123 : 49|1@0+ (1,0) [0|1] "" VCU
 SG_ P1_BalSwCell124 : 48|1@0+ (1,0) [0|1] "" VCU

BO_ 2556428305 BatP1_BMS_CellVoltageM31: 8 BMS
 SG_ P1_CellVoltage125 : 7|13@0+ (0.001,0) [0|5] "V" VCU
 SG_ P1_CellVoltage126 : 10|13@0+ (0.001,0) [0|5] "V" VCU
 SG_ P1_CellVoltage127 : 29|13@0+ (0.001,0) [0|5] "V" VCU
 SG_ P1_CellVoltage128 : 32|13@0+ (0.001,0) [0|5] "V" VCU
 SG_ P1_BalSwCell125 : 51|1@0+ (1,0) [0|1] "" VCU
 SG_ P1_BalSwCell126 : 50|1@0+ (1,0) [0|1] "" VCU
 SG_ P1_BalSwCell127 : 49|1@0+ (1,0) [0|1] "" VCU
 SG_ P1_BalSwCell128 : 48|1@0+ (1,0) [0|1] "" VCU

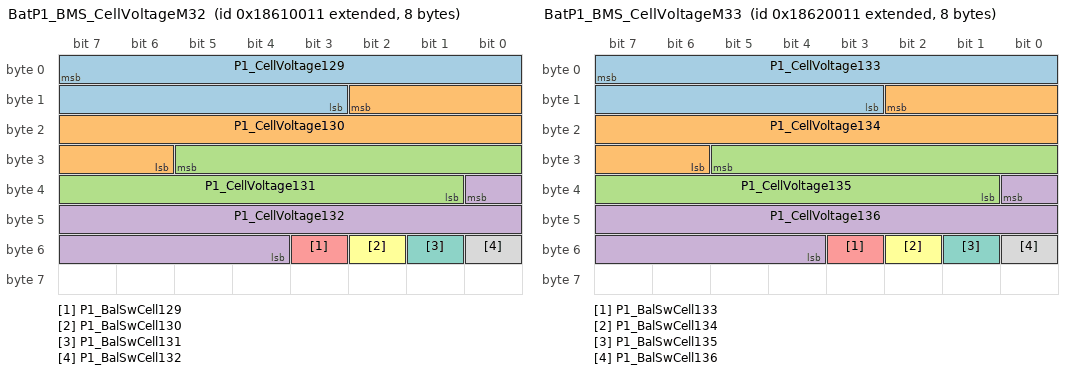
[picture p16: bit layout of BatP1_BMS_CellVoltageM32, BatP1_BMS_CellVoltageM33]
BO_ 2556493841 BatP1_BMS_CellVoltageM32: 8 BMS
 SG_ P1_CellVoltage129 : 7|13@0+ (0.001,0) [0|5] "V" VCU
 SG_ P1_CellVoltage130 : 10|13@0+ (0.001,0) [0|5] "V" VCU
 SG_ P1_CellVoltage131 : 29|13@0+ (0.001,0) [0|5] "V" VCU
 SG_ P1_CellVoltage132 : 32|13@0+ (0.001,0) [0|5] "V" VCU
 SG_ P1_BalSwCell129 : 51|1@0+ (1,0) [0|1] "" VCU
 SG_ P1_BalSwCell130 : 50|1@0+ (1,0) [0|1] "" VCU
 SG_ P1_BalSwCell131 : 49|1@0+ (1,0) [0|1] "" VCU
 SG_ P1_BalSwCell132 : 48|1@0+ (1,0) [0|1] "" VCU

BO_ 2556559377 BatP1_BMS_CellVoltageM33: 8 BMS
 SG_ P1_CellVoltage133 : 7|13@0+ (0.001,0) [0|5] "V" VCU
 SG_ P1_CellVoltage134 : 10|13@0+ (0.001,0) [0|5] "V" VCU
 SG_ P1_CellVoltage135 : 29|13@0+ (0.001,0) [0|5] "V" VCU
 SG_ P1_CellVoltage136 : 32|13@0+ (0.001,0) [0|5] "V" VCU
 SG_ P1_BalSwCell133 : 51|1@0+ (1,0) [0|1] "" VCU
 SG_ P1_BalSwCell134 : 50|1@0+ (1,0) [0|1] "" VCU
 SG_ P1_BalSwCell135 : 49|1@0+ (1,0) [0|1] "" VCU
 SG_ P1_BalSwCell136 : 48|1@0+ (1,0) [0|1] "" VCU

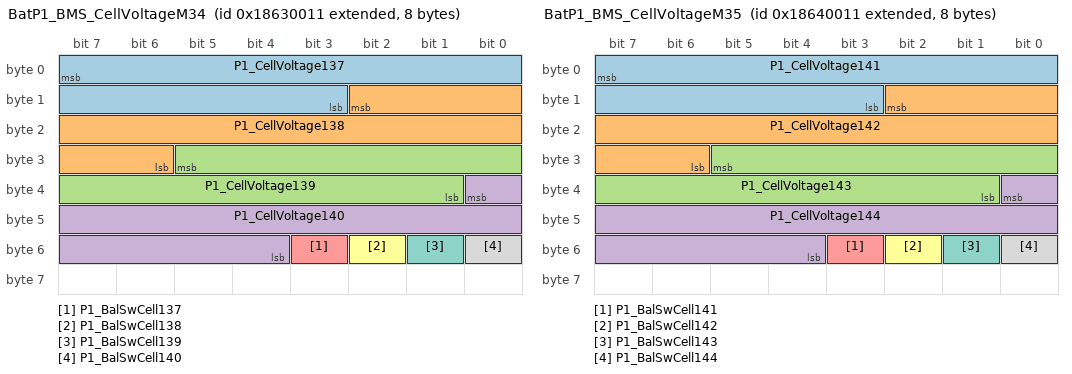
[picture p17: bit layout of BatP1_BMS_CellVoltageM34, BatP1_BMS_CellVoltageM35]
BO_ 2556624913 BatP1_BMS_CellVoltageM34: 8 BMS
 SG_ P1_CellVoltage137 : 7|13@0+ (0.001,0) [0|5] "V" VCU
 SG_ P1_CellVoltage138 : 10|13@0+ (0.001,0) [0|5] "V" VCU
 SG_ P1_CellVoltage139 : 29|13@0+ (0.001,0) [0|5] "V" VCU
 SG_ P1_CellVoltage140 : 32|13@0+ (0.001,0) [0|5] "V" VCU
 SG_ P1_BalSwCell137 : 51|1@0+ (1,0) [0|1] "" VCU
 SG_ P1_BalSwCell138 : 50|1@0+ (1,0) [0|1] "" VCU
 SG_ P1_BalSwCell139 : 49|1@0+ (1,0) [0|1] "" VCU
 SG_ P1_BalSwCell140 : 48|1@0+ (1,0) [0|1] "" VCU

BO_ 2556690449 BatP1_BMS_CellVoltageM35: 8 BMS
 SG_ P1_CellVoltage141 : 7|13@0+ (0.001,0) [0|5] "V" VCU
 SG_ P1_CellVoltage142 : 10|13@0+ (0.001,0) [0|5] "V" VCU
 SG_ P1_CellVoltage143 : 29|13@0+ (0.001,0) [0|5] "V" VCU
 SG_ P1_CellVoltage144 : 32|13@0+ (0.001,0) [0|5] "V" VCU
 SG_ P1_BalSwCell141 : 51|1@0+ (1,0) [0|1] "" VCU
 SG_ P1_BalSwCell142 : 50|1@0+ (1,0) [0|1] "" VCU
 SG_ P1_BalSwCell143 : 49|1@0+ (1,0) [0|1] "" VCU
 SG_ P1_BalSwCell144 : 48|1@0+ (1,0) [0|1] "" VCU

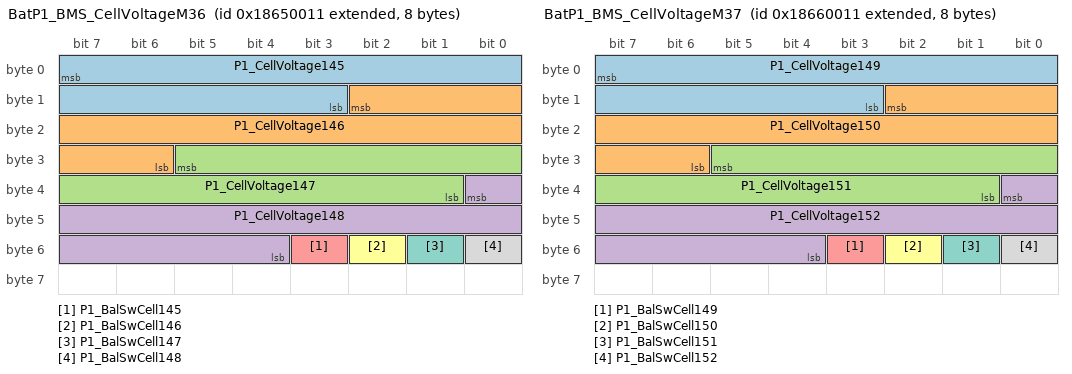
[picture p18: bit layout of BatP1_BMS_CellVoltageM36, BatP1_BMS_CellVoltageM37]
BO_ 2556755985 BatP1_BMS_CellVoltageM36: 8 BMS
 SG_ P1_CellVoltage145 : 7|13@0+ (0.001,0) [0|5] "V" VCU
 SG_ P1_CellVoltage146 : 10|13@0+ (0.001,0) [0|5] "V" VCU
 SG_ P1_CellVoltage147 : 29|13@0+ (0.001,0) [0|5] "V" VCU
 SG_ P1_CellVoltage148 : 32|13@0+ (0.001,0) [0|5] "V" VCU
 SG_ P1_BalSwCell145 : 51|1@0+ (1,0) [0|1] "" VCU
 SG_ P1_BalSwCell146 : 50|1@0+ (1,0) [0|1] "" VCU
 SG_ P1_BalSwCell147 : 49|1@0+ (1,0) [0|1] "" VCU
 SG_ P1_BalSwCell148 : 48|1@0+ (1,0) [0|1] "" VCU

BO_ 2556821521 BatP1_BMS_CellVoltageM37: 8 BMS
 SG_ P1_CellVoltage149 : 7|13@0+ (0.001,0) [0|5] "V" VCU
 SG_ P1_CellVoltage150 : 10|13@0+ (0.001,0) [0|5] "V" VCU
 SG_ P1_CellVoltage151 : 29|13@0+ (0.001,0) [0|5] "V" VCU
 SG_ P1_CellVoltage152 : 32|13@0+ (0.001,0) [0|5] "V" VCU
 SG_ P1_BalSwCell149 : 51|1@0+ (1,0) [0|1] "" VCU
 SG_ P1_BalSwCell150 : 50|1@0+ (1,0) [0|1] "" VCU
 SG_ P1_BalSwCell151 : 49|1@0+ (1,0) [0|1] "" VCU
 SG_ P1_BalSwCell152 : 48|1@0+ (1,0) [0|1] "" VCU

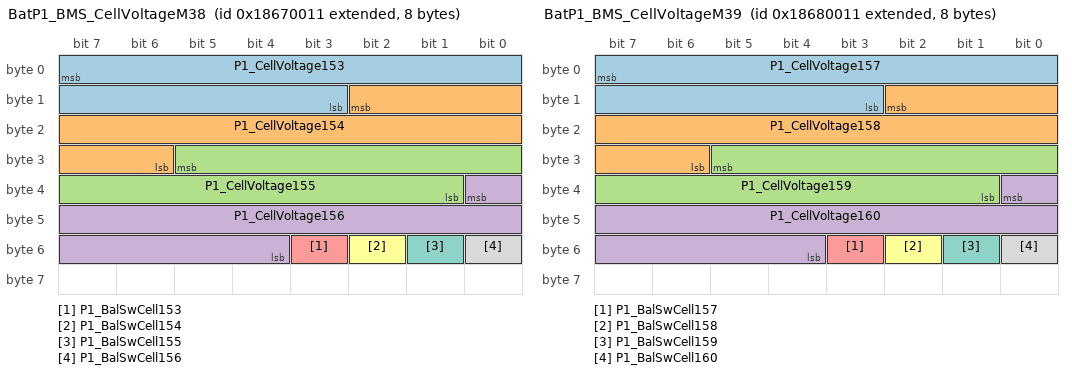
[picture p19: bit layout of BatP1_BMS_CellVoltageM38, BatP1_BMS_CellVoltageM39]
BO_ 2556887057 BatP1_BMS_CellVoltageM38: 8 BMS
 SG_ P1_CellVoltage153 : 7|13@0+ (0.001,0) [0|5] "V" VCU
 SG_ P1_CellVoltage154 : 10|13@0+ (0.001,0) [0|5] "V" VCU
 SG_ P1_CellVoltage155 : 29|13@0+ (0.001,0) [0|5] "V" VCU
 SG_ P1_CellVoltage156 : 32|13@0+ (0.001,0) [0|5] "V" VCU
 SG_ P1_BalSwCell153 : 51|1@0+ (1,0) [0|1] "" VCU
 SG_ P1_BalSwCell154 : 50|1@0+ (1,0) [0|1] "" VCU
 SG_ P1_BalSwCell155 : 49|1@0+ (1,0) [0|1] "" VCU
 SG_ P1_BalSwCell156 : 48|1@0+ (1,0) [0|1] "" VCU

BO_ 2556952593 BatP1_BMS_CellVoltageM39: 8 BMS
 SG_ P1_CellVoltage157 : 7|13@0+ (0.001,0) [0|5] "V" VCU
 SG_ P1_CellVoltage158 : 10|13@0+ (0.001,0) [0|5] "V" VCU
 SG_ P1_CellVoltage159 : 29|13@0+ (0.001,0) [0|5] "V" VCU
 SG_ P1_CellVoltage160 : 32|13@0+ (0.001,0) [0|5] "V" VCU
 SG_ P1_BalSwCell157 : 51|1@0+ (1,0) [0|1] "" VCU
 SG_ P1_BalSwCell158 : 50|1@0+ (1,0) [0|1] "" VCU
 SG_ P1_BalSwCell159 : 49|1@0+ (1,0) [0|1] "" VCU
 SG_ P1_BalSwCell160 : 48|1@0+ (1,0) [0|1] "" VCU

BO_ 2557018129 BatP1_BMS_CellVoltageM40: 8 BMS
 SG_ P1_CellVoltage161 : 7|13@0+ (0.001,0) [0|5] "V" VCU
 SG_ P1_CellVoltage162 : 10|13@0+ (0.001,0) [0|5] "V" VCU
 SG_ P1_CellVoltage163 : 29|13@0+ (0.001,0) [0|5] "V" VCU
 SG_ P1_CellVoltage164 : 32|13@0+ (0.001,0) [0|5] "V" VCU
 SG_ P1_BalSwCell161 : 51|1@0+ (1,0) [0|1] "" VCU
 SG_ P1_BalSwCell162 : 50|1@0+ (1,0) [0|1] "" VCU
 SG_ P1_BalSwCell163 : 49|1@0+ (1,0) [0|1] "" VCU
 SG_ P1_BalSwCell164 : 48|1@0+ (1,0) [0|1] "" VCU

BO_ 2557083665 BatP1_BMS_CellVoltageM41: 8 BMS
 SG_ P1_CellVoltage165 : 7|13@0+ (0.001,0) [0|5] "V" VCU
 SG_ P1_CellVoltage166 : 10|13@0+ (0.001,0) [0|5] "V" VCU
 SG_ P1_CellVoltage167 : 29|13@0+ (0.001,0) [0|5] "V" VCU
 SG_ P1_CellVoltage168 : 32|13@0+ (0.001,0) [0|5] "V" VCU
 SG_ P1_BalSwCell165 : 51|1@0+ (1,0) [0|1] "" VCU
 SG_ P1_BalSwCell166 : 50|1@0+ (1,0) [0|1] "" VCU
 SG_ P1_BalSwCell167 : 49|1@0+ (1,0) [0|1] "" VCU
 SG_ P1_BalSwCell168 : 48|1@0+ (1,0) [0|1] "" VCU

BO_ 2557149201 BatP1_BMS_CellVoltageM42: 8 BMS
 SG_ P1_CellVoltage169 : 7|13@0+ (0.001,0) [0|5] "V" VCU
 SG_ P1_CellVoltage170 : 10|13@0+ (0.001,0) [0|5] "V" VCU
 SG_ P1_CellVoltage171 : 29|13@0+ (0.001,0) [0|5] "V" VCU
 SG_ P1_CellVoltage172 : 32|13@0+ (0.001,0) [0|5] "V" VCU
 SG_ P1_BalSwCell169 : 51|1@0+ (1,0) [0|1] "" VCU
 SG_ P1_BalSwCell170 : 50|1@0+ (1,0) [0|1] "" VCU
 SG_ P1_BalSwCell171 : 49|1@0+ (1,0) [0|1] "" VCU
 SG_ P1_BalSwCell172 : 48|1@0+ (1,0) [0|1] "" VCU

BO_ 2557214737 BatP1_BMS_CellVoltageM43: 8 BMS
 SG_ P1_CellVoltage173 : 7|13@0+ (0.001,0) [0|5] "V" VCU
 SG_ P1_CellVoltage174 : 10|13@0+ (0.001,0) [0|5] "V" VCU
 SG_ P1_CellVoltage175 : 29|13@0+ (0.001,0) [0|5] "V" VCU
 SG_ P1_CellVoltage176 : 32|13@0+ (0.001,0) [0|5] "V" VCU
 SG_ P1_BalSwCell173 : 51|1@0+ (1,0) [0|1] "" VCU
 SG_ P1_BalSwCell174 : 50|1@0+ (1,0) [0|1] "" VCU
 SG_ P1_BalSwCell175 : 49|1@0+ (1,0) [0|1] "" VCU
 SG_ P1_BalSwCell176 : 48|1@0+ (1,0) [0|1] "" VCU

BO_ 2557280273 BatP1_BMS_CellVoltageM44: 8 BMS
 SG_ P1_CellVoltage177 : 7|13@0+ (0.001,0) [0|5] "V" VCU
 SG_ P1_CellVoltage178 : 10|13@0+ (0.001,0) [0|5] "V" VCU
 SG_ P1_CellVoltage179 : 29|13@0+ (0.001,0) [0|5] "V" VCU
 SG_ P1_CellVoltage180 : 32|13@0+ (0.001,0) [0|5] "V" VCU
 SG_ P1_BalSwCell177 : 51|1@0+ (1,0) [0|1] "" VCU
 SG_ P1_BalSwCell178 : 50|1@0+ (1,0) [0|1] "" VCU
 SG_ P1_BalSwCell179 : 49|1@0+ (1,0) [0|1] "" VCU
 SG_ P1_BalSwCell180 : 48|1@0+ (1,0) [0|1] "" VCU

BO_ 2557345809 BatP1_BMS_CellVoltageM45: 8 BMS
 SG_ P1_CellVoltage181 : 7|13@0+ (0.001,0) [0|5] "V" VCU
 SG_ P1_CellVoltage182 : 10|13@0+ (0.001,0) [0|5] "V" VCU
 SG_ P1_CellVoltage183 : 29|13@0+ (0.001,0) [0|5] "V" VCU
 SG_ P1_CellVoltage184 : 32|13@0+ (0.001,0) [0|5] "V" VCU
 SG_ P1_BalSwCell181 : 51|1@0+ (1,0) [0|1] "" VCU
 SG_ P1_BalSwCell182 : 50|1@0+ (1,0) [0|1] "" VCU
 SG_ P1_BalSwCell183 : 49|1@0+ (1,0) [0|1] "" VCU
 SG_ P1_BalSwCell184 : 48|1@0+ (1,0) [0|1] "" VCU

BO_ 2557411345 BatP1_BMS_CellVoltageM46: 8 BMS
 SG_ P1_CellVoltage185 : 7|13@0+ (0.001,0) [0|5] "V" VCU
 SG_ P1_CellVoltage186 : 10|13@0+ (0.001,0) [0|5] "V" VCU
 SG_ P1_CellVoltage187 : 29|13@0+ (0.001,0) [0|5] "V" VCU
 SG_ P1_CellVoltage188 : 32|13@0+ (0.001,0) [0|5] "V" VCU
 SG_ P1_BalSwCell185 : 51|1@0+ (1,0) [0|1] "" VCU
 SG_ P1_BalSwCell186 : 50|1@0+ (1,0) [0|1] "" VCU
 SG_ P1_BalSwCell187 : 49|1@0+ (1,0) [0|1] "" VCU
 SG_ P1_BalSwCell188 : 48|1@0+ (1,0) [0|1] "" VCU

BO_ 2557476881 BatP1_BMS_CellVoltageM47: 8 BMS
 SG_ P1_CellVoltage189 : 7|13@0+ (0.001,0) [0|5] "V" VCU
 SG_ P1_CellVoltage190 : 10|13@0+ (0.001,0) [0|5] "V" VCU
 SG_ P1_CellVoltage191 : 29|13@0+ (0.001,0) [0|5] "V" VCU
 SG_ P1_CellVoltage192 : 32|13@0+ (0.001,0) [0|5] "V" VCU
 SG_ P1_BalSwCell189 : 51|1@0+ (1,0) [0|1] "" VCU
 SG_ P1_BalSwCell190 : 50|1@0+ (1,0) [0|1] "" VCU
 SG_ P1_BalSwCell191 : 49|1@0+ (1,0) [0|1] "" VCU
 SG_ P1_BalSwCell192 : 48|1@0+ (1,0) [0|1] "" VCU

BO_ 2558525457 BatP1_BMS_CellTempM0: 8 BMS
 SG_ P1_CellTemp1 : 7|11@0+ (0.1,-40) [-40|150] "C" VCU
 SG_ P1_CellTemp2 : 12|11@0+ (0.1,-40) [-40|150] "C" VCU
 SG_ P1_CellTemp3 : 17|11@0+ (0.1,-40) [-40|150] "C" VCU
 SG_ P1_CellTemp4 : 38|11@0+ (0.1,-40) [-40|150] "C" VCU
 SG_ P1_CellTemp5 : 43|11@0+ (0.1,-40) [-40|150] "C" VCU

BO_ 2558590993 BatP1_BMS_CellTempM1: 8 BMS
 SG_ P1_CellTemp6 : 7|11@0+ (0.1,-40) [-40|150] "C" VCU
 SG_ P1_CellTemp7 : 12|11@0+ (0.1,-40) [-40|150] "C" VCU
 SG_ P1_CellTemp8 : 17|11@0+ (0.1,-40) [-40|150] "C" VCU
 SG_ P1_CellTemp9 : 38|11@0+ (0.1,-40) [-40|150] "C" VCU
 SG_ P1_CellTemp10 : 43|11@0+ (0.1,-40) [-40|150] "C" VCU

BO_ 2558656529 BatP1_BMS_CellTempM2: 8 BMS
 SG_ P1_CellTemp11 : 7|11@0+ (0.1,-40) [-40|150] "C" VCU
 SG_ P1_CellTemp12 : 12|11@0+ (0.1,-40) [-40|150] "C" VCU
 SG_ P1_CellTemp13 : 17|11@0+ (0.1,-40) [-40|150] "C" VCU
 SG_ P1_CellTemp14 : 38|11@0+ (0.1,-40) [-40|150] "C" VCU
 SG_ P1_CellTemp15 : 43|11@0+ (0.1,-40) [-40|150] "C" VCU

BO_ 2558722065 BatP1_BMS_CellTempM3: 8 BMS
 SG_ P1_CellTemp16 : 7|11@0+ (0.1,-40) [-40|150] "C" VCU
 SG_ P1_CellTemp17 : 12|11@0+ (0.1,-40) [-40|150] "C" VCU
 SG_ P1_CellTemp18 : 17|11@0+ (0.1,-40) [-40|150] "C" VCU
 SG_ P1_CellTemp19 : 38|11@0+ (0.1,-40) [-40|150] "C" VCU
 SG_ P1_CellTemp20 : 43|11@0+ (0.1,-40) [-40|150] "C" VCU

BO_ 2558787601 BatP1_BMS_CellTempM4: 8 BMS
 SG_ P1_CellTemp21 : 7|11@0+ (0.1,-40) [-40|150] "C" VCU
 SG_ P1_CellTemp22 : 12|11@0+ (0.1,-40) [-40|150] "C" VCU
 SG_ P1_CellTemp23 : 17|11@0+ (0.1,-40) [-40|150] "C" VCU
 SG_ P1_CellTemp24 : 38|11@0+ (0.1,-40) [-40|150] "C" VCU
 SG_ P1_CellTemp25 : 43|11@0+ (0.1,-40) [-40|150] "C" VCU

BO_ 2558853137 BatP1_BMS_CellTempM5: 8 BMS
 SG_ P1_CellTemp26 : 7|11@0+ (0.1,-40) [-40|150] "C" VCU
 SG_ P1_CellTemp27 : 12|11@0+ (0.1,-40) [-40|150] "C" VCU
 SG_ P1_CellTemp28 : 17|11@0+ (0.1,-40) [-40|150] "C" VCU
 SG_ P1_CellTemp29 : 38|11@0+ (0.1,-40) [-40|150] "C" VCU
 SG_ P1_CellTemp30 : 43|11@0+ (0.1,-40) [-40|150] "C" VCU

BO_ 2558918673 BatP1_BMS_CellTempM6: 8 BMS
 SG_ P1_CellTemp31 : 7|11@0+ (0.1,-40) [-40|150] "C" VCU
 SG_ P1_CellTemp32 : 12|11@0+ (0.1,-40) [-40|150] "C" VCU
 SG_ P1_CellTemp33 : 17|11@0+ (0.1,-40) [-40|150] "C" VCU
 SG_ P1_CellTemp34 : 38|11@0+ (0.1,-40) [-40|150] "C" VCU
 SG_ P1_CellTemp35 : 43|11@0+ (0.1,-40) [-40|150] "C" VCU

BO_ 2558984209 BatP1_BMS_CellTempM7: 8 BMS
 SG_ P1_CellTemp36 : 7|11@0+ (0.1,-40) [-40|150] "C" VCU
 SG_ P1_CellTemp37 : 12|11@0+ (0.1,-40) [-40|150] "C" VCU
 SG_ P1_CellTemp38 : 17|11@0+ (0.1,-40) [-40|150] "C" VCU
 SG_ P1_CellTemp39 : 38|11@0+ (0.1,-40) [-40|150] "C" VCU
 SG_ P1_CellTemp40 : 43|11@0+ (0.1,-40) [-40|150] "C" VCU

BO_ 2559049745 BatP1_BMS_CellTempM8: 8 BMS
 SG_ P1_CellTemp41 : 7|11@0+ (0.1,-40) [-40|150] "C" VCU
 SG_ P1_CellTemp42 : 12|11@0+ (0.1,-40) [-40|150] "C" VCU
 SG_ P1_CellTemp43 : 17|11@0+ (0.1,-40) [-40|150] "C" VCU
 SG_ P1_CellTemp44 : 38|11@0+ (0.1,-40) [-40|150] "C" VCU
 SG_ P1_CellTemp45 : 43|11@0+ (0.1,-40) [-40|150] "C" VCU

BO_ 2559115281 BatP1_BMS_CellTempM9: 8 BMS
 SG_ P1_CellTemp46 : 7|11@0+ (0.1,-40) [-40|150] "C" VCU
 SG_ P1_CellTemp47 : 12|11@0+ (0.1,-40) [-40|150] "C" VCU
 SG_ P1_CellTemp48 : 17|11@0+ (0.1,-40) [-40|150] "C" VCU
 SG_ P1_CellTemp49 : 38|11@0+ (0.1,-40) [-40|150] "C" VCU
 SG_ P1_CellTemp50 : 43|11@0+ (0.1,-40) [-40|150] "C" VCU

BO_ 2559180817 BatP1_BMS_CellTempM10: 8 BMS
 SG_ P1_CellTemp51 : 7|11@0+ (0.1,-40) [-40|150] "C" VCU
 SG_ P1_CellTemp52 : 12|11@0+ (0.1,-40) [-40|150] "C" VCU
 SG_ P1_CellTemp53 : 17|11@0+ (0.1,-40) [-40|150] "C" VCU
 SG_ P1_CellTemp54 : 38|11@0+ (0.1,-40) [-40|150] "C" VCU
 SG_ P1_CellTemp55 : 43|11@0+ (0.1,-40) [-40|150] "C" VCU

BO_ 2559246353 BatP1_BMS_CellTempM11: 8 BMS
 SG_ P1_CellTemp56 : 7|11@0+ (0.1,-40) [-40|150] "C" VCU
 SG_ P1_CellTemp57 : 12|11@0+ (0.1,-40) [-40|150] "C" VCU
 SG_ P1_CellTemp58 : 17|11@0+ (0.1,-40) [-40|150] "C" VCU
 SG_ P1_CellTemp59 : 38|11@0+ (0.1,-40) [-40|150] "C" VCU
 SG_ P1_CellTemp60 : 43|11@0+ (0.1,-40) [-40|150] "C" VCU

BO_ 2559311889 BatP1_BMS_CellTempM12: 8 BMS
 SG_ P1_CellTemp61 : 7|11@0+ (0.1,-40) [-40|150] "C" VCU
 SG_ P1_CellTemp62 : 12|11@0+ (0.1,-40) [-40|150] "C" VCU
 SG_ P1_CellTemp63 : 17|11@0+ (0.1,-40) [-40|150] "C" VCU
 SG_ P1_CellTemp64 : 38|11@0+ (0.1,-40) [-40|150] "C" VCU
 SG_ P1_CellTemp65 : 43|11@0+ (0.1,-40) [-40|150] "C" VCU

BO_ 2559377425 BatP1_BMS_CellTempM13: 8 BMS
 SG_ P1_CellTemp66 : 7|11@0+ (0.1,-40) [-40|150] "C" VCU
 SG_ P1_CellTemp67 : 12|11@0+ (0.1,-40) [-40|150] "C" VCU
 SG_ P1_CellTemp68 : 17|11@0+ (0.1,-40) [-40|150] "C" VCU
 SG_ P1_CellTemp69 : 38|11@0+ (0.1,-40) [-40|150] "C" VCU
 SG_ P1_CellTemp70 : 43|11@0+ (0.1,-40) [-40|150] "C" VCU

BO_ 2559442961 BatP1_BMS_CellTempM14: 8 BMS
 SG_ P1_CellTemp71 : 7|11@0+ (0.1,-40) [-40|150] "C" VCU
 SG_ P1_CellTemp72 : 12|11@0+ (0.1,-40) [-40|150] "C" VCU
 SG_ P1_CellTemp73 : 17|11@0+ (0.1,-40) [-40|150] "C" VCU
 SG_ P1_CellTemp74 : 38|11@0+ (0.1,-40) [-40|150] "C" VCU
 SG_ P1_CellTemp75 : 43|11@0+ (0.1,-40) [-40|150] "C" VCU

BO_ 2559508497 BatP1_BMS_CellTempM15: 8 BMS
 SG_ P1_CellTemp76 : 7|11@0+ (0.1,-40) [-40|150] "C" VCU
 SG_ P1_CellTemp77 : 12|11@0+ (0.1,-40) [-40|150] "C" VCU
 SG_ P1_CellTemp78 : 17|11@0+ (0.1,-40) [-40|150] "C" VCU
 SG_ P1_CellTemp79 : 38|11@0+ (0.1,-40) [-40|150] "C" VCU
 SG_ P1_CellTemp80 : 43|11@0+ (0.1,-40) [-40|150] "C" VCU

BO_ 2559574033 BatP1_BMS_CellTempM16: 8 BMS
 SG_ P1_CellTemp81 : 7|11@0+ (0.1,-40) [-40|150] "C" VCU
 SG_ P1_CellTemp82 : 12|11@0+ (0.1,-40) [-40|150] "C" VCU
 SG_ P1_CellTemp83 : 17|11@0+ (0.1,-40) [-40|150] "C" VCU
 SG_ P1_CellTemp84 : 38|11@0+ (0.1,-40) [-40|150] "C" VCU
 SG_ P1_CellTemp85 : 43|11@0+ (0.1,-40) [-40|150] "C" VCU

BO_ 2559639569 BatP1_BMS_CellTempM17: 8 BMS
 SG_ P1_CellTemp86 : 7|11@0+ (0.1,-40) [-40|150] "C" VCU
 SG_ P1_CellTemp87 : 12|11@0+ (0.1,-40) [-40|150] "C" VCU
 SG_ P1_CellTemp88 : 17|11@0+ (0.1,-40) [-40|150] "C" VCU
 SG_ P1_CellTemp89 : 38|11@0+ (0.1,-40) [-40|150] "C" VCU
 SG_ P1_CellTemp90 : 43|11@0+ (0.1,-40) [-40|150] "C" VCU

BO_ 2559705105 BatP1_BMS_CellTempM18: 8 BMS
 SG_ P1_CellTemp91 : 7|11@0+ (0.1,-40) [-40|150] "C" VCU
 SG_ P1_CellTemp92 : 12|11@0+ (0.1,-40) [-40|150] "C" VCU
 SG_ P1_CellTemp93 : 17|11@0+ (0.1,-40) [-40|150] "C" VCU
 SG_ P1_CellTemp94 : 38|11@0+ (0.1,-40) [-40|150] "C" VCU
 SG_ P1_CellTemp95 : 43|11@0+ (0.1,-40) [-40|150] "C" VCU

BO_ 2559770641 BatP1_BMS_CellTempM19: 8 BMS
 SG_ P1_CellTemp96 : 7|11@0+ (0.1,-40) [-40|150] "C" VCU
 SG_ P1_CellTemp97 : 12|11@0+ (0.1,-40) [-40|150] "C" VCU
 SG_ P1_CellTemp98 : 17|11@0+ (0.1,-40) [-40|150] "C" VCU
 SG_ P1_CellTemp99 : 38|11@0+ (0.1,-40) [-40|150] "C" VCU
 SG_ P1_CellTemp100 : 43|11@0+ (0.1,-40) [-40|150] "C" VCU

BO_ 2559836177 BatP1_BMS_CellTempM20: 8 BMS
 SG_ P1_CellTemp101 : 7|11@0+ (0.1,-40) [-40|150] "C" VCU
 SG_ P1_CellTemp102 : 12|11@0+ (0.1,-40) [-40|150] "C" VCU
 SG_ P1_CellTemp103 : 17|11@0+ (0.1,-40) [-40|150] "C" VCU
 SG_ P1_CellTemp104 : 38|11@0+ (0.1,-40) [-40|150] "C" VCU
 SG_ P1_CellTemp105 : 43|11@0+ (0.1,-40) [-40|150] "C" VCU

BO_ 2559901713 BatP1_BMS_CellTempM21: 8 BMS
 SG_ P1_CellTemp106 : 7|11@0+ (0.1,-40) [-40|150] "C" VCU
 SG_ P1_CellTemp107 : 12|11@0+ (0.1,-40) [-40|150] "C" VCU
 SG_ P1_CellTemp108 : 17|11@0+ (0.1,-40) [-40|150] "C" VCU
 SG_ P1_CellTemp109 : 38|11@0+ (0.1,-40) [-40|150] "C" VCU
 SG_ P1_CellTemp110 : 43|11@0+ (0.1,-40) [-40|150] "C" VCU

BO_ 2559967249 BatP1_BMS_CellTempM22: 8 BMS
 SG_ P1_CellTemp111 : 7|11@0+ (0.1,-40) [-40|150] "C" VCU
 SG_ P1_CellTemp112 : 12|11@0+ (0.1,-40) [-40|150] "C" VCU
 SG_ P1_CellTemp113 : 17|11@0+ (0.1,-40) [-40|150] "C" VCU
 SG_ P1_CellTemp114 : 38|11@0+ (0.1,-40) [-40|150] "C" VCU
 SG_ P1_CellTemp115 : 43|11@0+ (0.1,-40) [-40|150] "C" VCU

BO_ 2560032785 BatP1_BMS_CellTempM23: 8 BMS
 SG_ P1_CellTemp116 : 7|11@0+ (0.1,-40) [-40|150] "C" VCU
 SG_ P1_CellTemp117 : 12|11@0+ (0.1,-40) [-40|150] "C" VCU
 SG_ P1_CellTemp118 : 17|11@0+ (0.1,-40) [-40|150] "C" VCU
 SG_ P1_CellTemp119 : 38|11@0+ (0.1,-40) [-40|150] "C" VCU
 SG_ P1_CellTemp120 : 43|11@0+ (0.1,-40) [-40|150] "C" VCU

BO_ 2560098321 BatP1_BMS_CellTempM24: 8 BMS
 SG_ P1_CellTemp121 : 7|11@0+ (0.1,-40) [-40|150] "C" VCU
 SG_ P1_CellTemp122 : 12|11@0+ (0.1,-40) [-40|150] "C" VCU
 SG_ P1_CellTemp123 : 17|11@0+ (0.1,-40) [-40|150] "C" VCU
 SG_ P1_CellTemp124 : 38|11@0+ (0.1,-40) [-40|150] "C" VCU
 SG_ P1_CellTemp125 : 43|11@0+ (0.1,-40) [-40|150] "C" VCU

BO_ 2560163857 BatP1_BMS_CellTempM25: 8 BMS
 SG_ P1_CellTemp126 : 7|11@0+ (0.1,-40) [-40|150] "C" VCU
 SG_ P1_CellTemp127 : 12|11@0+ (0.1,-40) [-40|150] "C" VCU
 SG_ P1_CellTemp128 : 17|11@0+ (0.1,-40) [-40|150] "C" VCU
 SG_ P1_CellTemp129 : 38|11@0+ (0.1,-40) [-40|150] "C" VCU
 SG_ P1_CellTemp130 : 43|11@0+ (0.1,-40) [-40|150] "C" VCU

BO_ 2560229393 BatP1_BMS_CellTempM26: 8 BMS
 SG_ P1_CellTemp131 : 7|11@0+ (0.1,-40) [-40|150] "C" VCU
 SG_ P1_CellTemp132 : 12|11@0+ (0.1,-40) [-40|150] "C" VCU
 SG_ P1_CellTemp133 : 17|11@0+ (0.1,-40) [-40|150] "C" VCU
 SG_ P1_CellTemp134 : 38|11@0+ (0.1,-40) [-40|150] "C" VCU
 SG_ P1_CellTemp135 : 43|11@0+ (0.1,-40) [-40|150] "C" VCU

BO_ 2560294929 BatP1_BMS_CellTempM27: 8 BMS
 SG_ P1_CellTemp136 : 7|11@0+ (0.1,-40) [-40|150] "C" VCU
 SG_ P1_CellTemp137 : 12|11@0+ (0.1,-40) [-40|150] "C" VCU
 SG_ P1_CellTemp138 : 17|11@0+ (0.1,-40) [-40|150] "C" VCU
 SG_ P1_CellTemp139 : 38|11@0+ (0.1,-40) [-40|150] "C" VCU
 SG_ P1_CellTemp140 : 43|11@0+ (0.1,-40) [-40|150] "C" VCU

BO_ 2560360465 BatP1_BMS_CellTempM28: 8 BMS
 SG_ P1_CellTemp141 : 7|11@0+ (0.1,-40) [-40|150] "C" VCU
 SG_ P1_CellTemp142 : 12|11@0+ (0.1,-40) [-40|150] "C" VCU
 SG_ P1_CellTemp143 : 17|11@0+ (0.1,-40) [-40|150] "C" VCU
 SG_ P1_CellTemp144 : 38|11@0+ (0.1,-40) [-40|150] "C" VCU
 SG_ P1_CellTemp145 : 43|11@0+ (0.1,-40) [-40|150] "C" VCU

BO_ 2560426001 BatP1_BMS_CellTempM29: 8 BMS
 SG_ P1_CellTemp146 : 7|11@0+ (0.1,-40) [-40|150] "C" VCU
 SG_ P1_CellTemp147 : 12|11@0+ (0.1,-40) [-40|150] "C" VCU
 SG_ P1_CellTemp148 : 17|11@0+ (0.1,-40) [-40|150] "C" VCU
 SG_ P1_CellTemp149 : 38|11@0+ (0.1,-40) [-40|150] "C" VCU
 SG_ P1_CellTemp150 : 43|11@0+ (0.1,-40) [-40|150] "C" VCU

BO_ 2560491537 BatP1_BMS_CellTempM30: 8 BMS
 SG_ P1_CellTemp151 : 7|11@0+ (0.1,-40) [-40|150] "C" VCU
 SG_ P1_CellTemp152 : 12|11@0+ (0.1,-40) [-40|150] "C" VCU
 SG_ P1_CellTemp153 : 17|11@0+ (0.1,-40) [-40|150] "C" VCU
 SG_ P1_CellTemp154 : 38|11@0+ (0.1,-40) [-40|150] "C" VCU
 SG_ P1_CellTemp155 : 43|11@0+ (0.1,-40) [-40|150] "C" VCU

BO_ 2560557073 BatP1_BMS_CellTempM31: 8 BMS
 SG_ P1_CellTemp156 : 7|11@0+ (0.1,-40) [-40|150] "C" VCU
 SG_ P1_CellTemp157 : 12|11@0+ (0.1,-40) [-40|150] "C" VCU
 SG_ P1_CellTemp158 : 17|11@0+ (0.1,-40) [-40|150] "C" VCU
 SG_ P1_CellTemp159 : 38|11@0+ (0.1,-40) [-40|150] "C" VCU
 SG_ P1_CellTemp160 : 43|11@0+ (0.1,-40) [-40|150] "C" VCU

BO_ 2560622609 BatP1_BMS_CellTempM32: 8 BMS
 SG_ P1_CellTemp161 : 7|11@0+ (0.1,-40) [-40|150] "C" VCU
 SG_ P1_CellTemp162 : 12|11@0+ (0.1,-40) [-40|150] "C" VCU
 SG_ P1_CellTemp163 : 17|11@0+ (0.1,-40) [-40|150] "C" VCU
 SG_ P1_CellTemp164 : 38|11@0+ (0.1,-40) [-40|150] "C" VCU
 SG_ P1_CellTemp165 : 43|11@0+ (0.1,-40) [-40|150] "C" VCU

BO_ 2560688145 BatP1_BMS_CellTempM33: 8 BMS
 SG_ P1_CellTemp166 : 7|11@0+ (0.1,-40) [-40|150] "C" VCU
 SG_ P1_CellTemp167 : 12|11@0+ (0.1,-40) [-40|150] "C" VCU
 SG_ P1_CellTemp168 : 17|11@0+ (0.1,-40) [-40|150] "C" VCU
 SG_ P1_CellTemp169 : 38|11@0+ (0.1,-40) [-40|150] "C" VCU
 SG_ P1_CellTemp170 : 43|11@0+ (0.1,-40) [-40|150] "C" VCU

BO_ 2560753681 BatP1_BMS_CellTempM34: 8 BMS
 SG_ P1_CellTemp171 : 7|11@0+ (0.1,-40) [-40|150] "C" VCU
 SG_ P1_CellTemp172 : 12|11@0+ (0.1,-40) [-40|150] "C" VCU
 SG_ P1_CellTemp173 : 17|11@0+ (0.1,-40) [-40|150] "C" VCU
 SG_ P1_CellTemp174 : 38|11@0+ (0.1,-40) [-40|150] "C" VCU
 SG_ P1_CellTemp175 : 43|11@0+ (0.1,-40) [-40|150] "C" VCU

BO_ 2560819217 BatP1_BMS_CellTempM35: 8 BMS
 SG_ P1_CellTemp176 : 7|11@0+ (0.1,-40) [-40|150] "C" VCU
 SG_ P1_CellTemp177 : 12|11@0+ (0.1,-40) [-40|150] "C" VCU
 SG_ P1_CellTemp178 : 17|11@0+ (0.1,-40) [-40|150] "C" VCU
 SG_ P1_CellTemp179 : 38|11@0+ (0.1,-40) [-40|150] "C" VCU
 SG_ P1_CellTemp180 : 43|11@0+ (0.1,-40) [-40|150] "C" VCU

BO_ 2560884753 BatP1_BMS_CellTempM36: 8 BMS
 SG_ P1_CellTemp181 : 7|11@0+ (0.1,-40) [-40|150] "C" VCU
 SG_ P1_CellTemp182 : 12|11@0+ (0.1,-40) [-40|150] "C" VCU
 SG_ P1_CellTemp183 : 17|11@0+ (0.1,-40) [-40|150] "C" VCU
 SG_ P1_CellTemp184 : 38|11@0+ (0.1,-40) [-40|150] "C" VCU
 SG_ P1_CellTemp185 : 43|11@0+ (0.1,-40) [-40|150] "C" VCU

BO_ 2560950289 BatP1_BMS_CellTempM37: 8 BMS
 SG_ P1_CellTemp186 : 7|11@0+ (0.1,-40) [-40|150] "C" VCU
 SG_ P1_CellTemp187 : 12|11@0+ (0.1,-40) [-40|150] "C" VCU
 SG_ P1_CellTemp188 : 17|11@0+ (0.1,-40) [-40|150] "C" VCU
 SG_ P1_CellTemp189 : 38|11@0+ (0.1,-40) [-40|150] "C" VCU
 SG_ P1_CellTemp190 : 43|11@0+ (0.1,-40) [-40|150] "C" VCU

BO_ 2561015825 BatP1_BMS_CellTempM38: 8 BMS
 SG_ P1_CellTemp191 : 7|11@0+ (0.1,-40) [-40|150] "C" VCU
 SG_ P1_CellTemp192 : 12|11@0+ (0.1,-40) [-40|150] "C" VCU
 SG_ P1_DatLen16DbgInfo1 : 7|16@0+ (1,0) [0|65535] "" VCU
 SG_ P1_DatLen16DbgInfo2 : 23|16@0+ (1,0) [0|65535] "" VCU
 SG_ P1_DatLen16DbgInfo3 : 39|16@0+ (1,0) [0|65535] "" VCU
 SG_ P1_DatLen16DbgInfo4 : 55|16@0+ (1,0) [0|65535] "" VCU

BO_ 2550399010 BatP2_BMS_PowerSupplyInfo: 8 BMS
 SG_ P2_BMSPwrSuplVlt1 : 7|9@0+ (0.1,0) [0|50] "V" VCU
 SG_ P2_BMSPwrSuplVlt2 : 14|9@0+ (0.1,0) [0|50] "V" VCU
 SG_ P2_ChrgStationAuxPwrSuplVlt : 21|9@0+ (0.1,0) [0|50] "V" VCU
 SG_ P2_BMSKL15ON : 28|1@0+ (1,0) [0|1] "" VCU
 SG_ P2_DCStepState : 27|8@0+ (1,0) [0|255] "" VCU
 SG_ P2_ExtLvWakeup_28VOnly : 35|9@0+ (0.1,0) [0|50] "V" VCU

BO_ 2550464546 BatP2_BMS_PackUsageLimit: 8 BMS
 SG_ P2_PackVltUprLmt : 7|14@0+ (0.1,0) [0|1200] "V" VCU
 SG_ P2_PackVltLoLmt : 9|14@0+ (0.1,0) [0|1200] "V" VCU
 SG_ P2_PackMaxDschrgCrnt : 27|14@0+ (0.1,0) [0|1600] "A" VCU
 SG_ P2_PackMaxChrgCrnt : 45|14@0+ (0.1,0) [0|1600] "A" VCU

BO_ 2550530082 BatP2_BMS_PackPowerCapability: 8 BMS
 SG_ P2_PackDschrgPwrLmt : 7|10@0+ (1,0) [0|1000] "kW" VCU
 SG_ P2_PackDschrgPwrStat : 13|2@0+ (1,0) [0|3] "" VCU
 SG_ P2_PackChrgPwrLmt : 11|10@0+ (1,0) [0|1000] "kW" VCU
 SG_ P2_PackChrgPwrStat : 17|2@0+ (1,0) [0|3] "" VCU

BO_ 2550595618 BatP2_BMS_ChargingInfo: 8 BMS
 SG_ P2_ChrgrCplrStat : 7|1@0+ (1,0) [0|1] "" VCU
 SG_ P2_HVBattChrgSysStatus : 6|4@0+ (1,0) [0|15] "" VCU
 SG_ P2_DCChrgCrntCmd : 2|9@0+ (1,0) [0|500] "A" VCU
 SG_ P2_CC2Vlt : 9|8@0+ (0.1,0) [0|25] "V" VCU
 SG_ P2_DCRcptPosTemp : 17|9@0+ (0.5,-40) [-40|150] "C" VCU
 SG_ P2_DCRcptNegTemp : 24|9@0+ (0.5,-40) [-40|150] "C" VCU
 SG_ P2_Tm2FullChrg : 47|14@0+ (1,0) [0|65535] "min" VCU

BO_ 2550661154 BatP2_BMS_ThermalManagement: 8 BMS
 SG_ P2_Inlet1ClntTemp : 7|11@0+ (0.1,-40) [-40|150] "C" VCU
 SG_ P2_Inlet2ClntTemp : 12|11@0+ (0.1,-40) [-40|150] "C" VCU
 SG_ P2_Outlet1ClntTemp : 17|11@0+ (0.1,-40) [-40|150] "C" VCU
 SG_ P2_Outlet2ClntTemp : 38|11@0+ (0.1,-40) [-40|150] "C" VCU
 SG_ P2_TrgtClntTemp : 43|11@0+ (0.1,-40) [-40|150] "C" VCU
 SG_ P2_TrgtClntFlowRate : 48|9@0+ (0.2,0) [0|100] "C" VCU

BO_ 2550726690 BatP2_BMS_CellVoltMaxMin: 8 BMS
 SG_ P2_MaxCellVlt : 7|13@0+ (0.001,0) [0|5] "V" VCU
 SG_ P2_MaxCellVltNum : 10|9@0+ (1,0) [0|500] "" VCU
 SG_ P2_MinCellVlt : 17|13@0+ (0.001,0) [0|5] "V" VCU
 SG_ P2_MinCellVltNum : 36|9@0+ (1,0) [0|500] "" VCU
 SG_ P2_AvgCellVlt : 43|13@0+ (0.001,0) [0|5] "V" VCU

BO_ 2550792226 BatP2_BMS_CellTempMaxMin: 8 BMS
 SG_ P2_MaxCellTemp : 7|11@0+ (0.1,-40) [-40|150] "C" VCU
 SG_ P2_MaxCellTempNum : 12|9@0+ (1,0) [0|500] "" VCU
 SG_ P2_MinCellTemp : 19|11@0+ (0.1,-40) [-40|150] "C" VCU
 SG_ P2_MinCellTempNum : 24|9@0+ (1,0) [0|500] "" VCU
 SG_ P2_AvgCellTemp : 47|11@0+ (0.1,-40) [-40|150] "C" VCU

BO_ 2550857762 BatP2_BMS_PackFaultInfo1: 8 BMS
 SG_ P2_PackTotFltNum : 7|8@0+ (1,0) [0|200] "" VCU
 SG_ P2_CellOverVoltage : 15|2@0+ (1,0) [0|3] "" VCU
 SG_ P2_CellUnderVoltage : 13|2@0+ (1,0) [0|3] "" VCU
 SG_ P2_CellVoltageDiffHi : 11|1@0+ (1,0) [0|1] "" VCU
 SG_ P2_PackOverVoltage : 10|2@0+ (1,0) [0|3] "" VCU
 SG_ P2_PackUnderVoltage : 8|2@0+ (1,0) [0|3] "" VCU
 SG_ P2_CellOverTemp : 22|2@0+ (1,0) [0|3] "" VCU
 SG_ P2_CellTempLow : 20|1@0+ (1,0) [0|1] "" VCU
 SG_ P2_CellTempDiffHi : 19|1@0+ (1,0) [0|1] "" VCU
 SG_ P2_PackDschrgCrntHi : 18|2@0+ (1,0) [0|3] "" VCU
 SG_ P2_PackChrgCrntHi : 16|2@0+ (1,0) [0|3] "" VCU
 SG_ P2_PackCrnSnsr1OffsetHi : 30|1@0+ (1,0) [0|1] "" VCU
 SG_ P2_HVIsolFlt : 29|2@0+ (1,0) [0|3] "" VCU
 SG_ P2_HVILFlt : 27|1@0+ (1,0) [0|1] "" VCU
 SG_ P2_ThrmlRunaway : 26|1@0+ (1,0) [0|1] "" VCU
 SG_ P2_CellVoltInvalid : 25|1@0+ (1,0) [0|1] "" VCU
 SG_ P2_CellTempInvalid : 24|1@0+ (1,0) [0|1] "" VCU
 SG_ P2_DaisyChainComFlt : 39|1@0+ (1,0) [0|1] "" VCU
 SG_ P2_PackVoltRatFlt : 38|1@0+ (1,0) [0|1] "" VCU
 SG_ P2_CrntSnsr1Invalid : 37|1@0+ (1,0) [0|1] "" VCU
 SG_ P2_CrntSnsr1OOR : 36|1@0+ (1,0) [0|1] "" VCU
 SG_ P2_CrntSnsr2Invalid : 35|1@0+ (1,0) [0|1] "" VCU
 SG_ P2_CrntSnsr2OOR : 34|1@0+ (1,0) [0|1] "" VCU
 SG_ P2_PackCrnSnsr2OffsetHi : 33|1@0+ (1,0) [0|1] "" VCU
 SG_ P2_OutofEnergy : 32|1@0+ (1,0) [0|1] "" VCU
 SG_ P2_IsolDetCircErr : 47|1@0+ (1,0) [0|1] "" VCU
 SG_ P2_HVILCircShortToGND : 46|1@0+ (1,0) [0|1] "" VCU
 SG_ P2_HVILCircShortToPwr : 45|1@0+ (1,0) [0|1] "" VCU

BO_ 2550923298 BatP2_BMS_PackFaultInfo2: 8 BMS
 SG_ P2_MainPosCntctrStkClsd : 7|1@0+ (1,0) [0|1] "" VCU
 SG_ P2_MainPosCntctrStkOpn : 6|1@0+ (1,0) [0|1] "" VCU
 SG_ P2_MainNegCntctr1StkClsd : 5|1@0+ (1,0) [0|1] "" VCU
 SG_ P2_MainNegCntctr1StkOpn : 4|1@0+ (1,0) [0|1] "" VCU
 SG_ P2_MainNegCntctr2StkClsd : 3|1@0+ (1,0) [0|1] "" VCU
 SG_ P2_MainNegCntctr2StkOpn : 2|1@0+ (1,0) [0|1] "" VCU
 SG_ P2_PrechargTmOut : 1|1@0+ (1,0) [0|1] "" VCU
 SG_ P2_PrechrgCrntHi : 0|1@0+ (1,0) [0|1] "" VCU
 SG_ P2_ChrgCplrPosTempHi : 15|1@0+ (1,0) [0|1] "" VCU
 SG_ P2_ChrgCplrNegTempHi : 14|1@0+ (1,0) [0|1] "" VCU
 SG_ P2_BMSPwrSuplVlt1Hi : 13|1@0+ (1,0) [0|1] "" VCU
 SG_ P2_BMSPwrSuplVlt1Lo : 12|1@0+ (1,0) [0|1] "" VCU
 SG_ P2_BMSPwrSuplVlt2Hi : 11|1@0+ (1,0) [0|1] "" VCU
 SG_ P2_BMSPwrSuplVlt2Lo : 10|1@0+ (1,0) [0|1] "" VCU
 SG_ P2_CntctrCirPwrSuplVltLo : 9|1@0+ (1,0) [0|1] "" VCU
 SG_ P2_CntctrCirPwrSuplVltHi : 8|1@0+ (1,0) [0|1] "" VCU
 SG_ P2_CAN1BusOff : 23|1@0+ (1,0) [0|1] "" VCU
 SG_ P2_CAN1BusTmOut : 22|1@0+ (1,0) [0|1] "" VCU
 SG_ P2_CAN2BusOff : 21|1@0+ (1,0) [0|1] "" VCU
 SG_ P2_CAN2BusTmOut : 20|1@0+ (1,0) [0|1] "" VCU
 SG_ P2_CellBalCircTempHi : 19|1@0+ (1,0) [0|1] "" VCU
 SG_ P2_ClntInTempHi : 18|1@0+ (1,0) [0|1] "" VCU
 SG_ P2_ClntOutTempHi : 17|1@0+ (1,0) [0|1] "" VCU
 SG_ P2_CellExtrmUdrVolt : 16|1@0+ (1,0) [0|1] "" VCU
 SG_ P2_CellExtrmOvrVolt : 31|1@0+ (1,0) [0|1] "" VCU
 SG_ P2_Branch1DischrgCrntHi  : 30|1@0+ (1,0) [0|1] "" VCU
 SG_ P2_Branch2DischrgCrntHi  : 29|1@0+ (1,0) [0|1] "" VCU
 SG_ P2_Branch1ChrgCrntHi  : 28|1@0+ (1,0) [0|1] "" VCU
 SG_ P2_Branch2ChrgCrntHi  : 27|1@0+ (1,0) [0|1] "" VCU
 SG_ P2_InitFailed : 26|1@0+ (1,0) [0|1] "" VCU
 SG_ P2_PackErrCode : 25|10@0+ (1,0) [0|1023] "" VCU

BO_ 2550988834 BatP2_BMS_PackConfigInfo: 8 BMS
 SG_ P2_PackTotCellNum : 7|9@0+ (1,0) [0|500] "" VCU
 SG_ P2_PackTotCellTempSnsrNum : 14|9@0+ (1,0) [0|500] "" VCU

BO_ 2552299554 BatP2_BMS_BMSVersion: 8 BMS
 SG_ P2_BMSASWMajVerNum : 7|8@0+ (1,0) [0|9] "" VCU
 SG_ P2_BMSASWMinVerNum : 15|8@0+ (1,0) [0|99] "" VCU
 SG_ P2_BMSASWPatchVerNum : 23|8@0+ (1,0) [0|255] "" VCU
 SG_ P2_BMSBSWMajVerNum : 31|8@0+ (1,0) [0|9] "" VCU
 SG_ P2_BMSBSWMinVerNum : 39|8@0+ (1,0) [0|99] "" VCU
 SG_ P2_BMSBSWPatchVerNum : 47|8@0+ (1,0) [0|255] "" VCU

BO_ 2554396706 BatP2_BMS_CellVoltageM0: 8 BMS
 SG_ P2_CellVoltage1 : 7|13@0+ (0.001,0) [0|5] "V" VCU
 SG_ P2_CellVoltage2 : 10|13@0+ (0.001,0) [0|5] "V" VCU
 SG_ P2_CellVoltage3 : 29|13@0+ (0.001,0) [0|5] "V" VCU
 SG_ P2_CellVoltage4 : 32|13@0+ (0.001,0) [0|5] "V" VCU
 SG_ P2_BalSwCell1 : 51|1@0+ (1,0) [0|1] "" VCU
 SG_ P2_BalSwCell2 : 50|1@0+ (1,0) [0|1] "" VCU
 SG_ P2_BalSwCell3 : 49|1@0+ (1,0) [0|1] "" VCU
 SG_ P2_BalSwCell4 : 48|1@0+ (1,0) [0|1] "" VCU

BO_ 2554462242 BatP2_BMS_CellVoltageM1: 8 BMS
 SG_ P2_CellVoltage5 : 7|13@0+ (0.001,0) [0|5] "V" VCU
 SG_ P2_CellVoltage6 : 10|13@0+ (0.001,0) [0|5] "V" VCU
 SG_ P2_CellVoltage7 : 29|13@0+ (0.001,0) [0|5] "V" VCU
 SG_ P2_CellVoltage8 : 32|13@0+ (0.001,0) [0|5] "V" VCU
 SG_ P2_BalSwCell5 : 51|1@0+ (1,0) [0|1] "" VCU
 SG_ P2_BalSwCell6 : 50|1@0+ (1,0) [0|1] "" VCU
 SG_ P2_BalSwCell7 : 49|1@0+ (1,0) [0|1] "" VCU
 SG_ P2_BalSwCell8 : 48|1@0+ (1,0) [0|1] "" VCU

BO_ 2554527778 BatP2_BMS_CellVoltageM2: 8 BMS
 SG_ P2_CellVoltage9 : 7|13@0+ (0.001,0) [0|5] "V" VCU
 SG_ P2_CellVoltage10 : 10|13@0+ (0.001,0) [0|5] "V" VCU
 SG_ P2_CellVoltage11 : 29|13@0+ (0.001,0) [0|5] "V" VCU
 SG_ P2_CellVoltage12 : 32|13@0+ (0.001,0) [0|5] "V" VCU
 SG_ P2_BalSwCell9 : 51|1@0+ (1,0) [0|1] "" VCU
 SG_ P2_BalSwCell10 : 50|1@0+ (1,0) [0|1] "" VCU
 SG_ P2_BalSwCell11 : 49|1@0+ (1,0) [0|1] "" VCU
 SG_ P2_BalSwCell12 : 48|1@0+ (1,0) [0|1] "" VCU

BO_ 2554593314 BatP2_BMS_CellVoltageM3: 8 BMS
 SG_ P2_CellVoltage13 : 7|13@0+ (0.001,0) [0|5] "V" VCU
 SG_ P2_CellVoltage14 : 10|13@0+ (0.001,0) [0|5] "V" VCU
 SG_ P2_CellVoltage15 : 29|13@0+ (0.001,0) [0|5] "V" VCU
 SG_ P2_CellVoltage16 : 32|13@0+ (0.001,0) [0|5] "V" VCU
 SG_ P2_BalSwCell13 : 51|1@0+ (1,0) [0|1] "" VCU
 SG_ P2_BalSwCell14 : 50|1@0+ (1,0) [0|1] "" VCU
 SG_ P2_BalSwCell15 : 49|1@0+ (1,0) [0|1] "" VCU
 SG_ P2_BalSwCell16 : 48|1@0+ (1,0) [0|1] "" VCU

BO_ 2554658850 BatP2_BMS_CellVoltageM4: 8 BMS
 SG_ P2_CellVoltage17 : 7|13@0+ (0.001,0) [0|5] "V" VCU
 SG_ P2_CellVoltage18 : 10|13@0+ (0.001,0) [0|5] "V" VCU
 SG_ P2_CellVoltage19 : 29|13@0+ (0.001,0) [0|5] "V" VCU
 SG_ P2_CellVoltage20 : 32|13@0+ (0.001,0) [0|5] "V" VCU
 SG_ P2_BalSwCell17 : 51|1@0+ (1,0) [0|1] "" VCU
 SG_ P2_BalSwCell18 : 50|1@0+ (1,0) [0|1] "" VCU
 SG_ P2_BalSwCell19 : 49|1@0+ (1,0) [0|1] "" VCU
 SG_ P2_BalSwCell20 : 48|1@0+ (1,0) [0|1] "" VCU

BO_ 2554724386 BatP2_BMS_CellVoltageM5: 8 BMS
 SG_ P2_CellVoltage21 : 7|13@0+ (0.001,0) [0|5] "V" VCU
 SG_ P2_CellVoltage22 : 10|13@0+ (0.001,0) [0|5] "V" VCU
 SG_ P2_CellVoltage23 : 29|13@0+ (0.001,0) [0|5] "V" VCU
 SG_ P2_CellVoltage24 : 32|13@0+ (0.001,0) [0|5] "V" VCU
 SG_ P2_BalSwCell21 : 51|1@0+ (1,0) [0|1] "" VCU
 SG_ P2_BalSwCell22 : 50|1@0+ (1,0) [0|1] "" VCU
 SG_ P2_BalSwCell23 : 49|1@0+ (1,0) [0|1] "" VCU
 SG_ P2_BalSwCell24 : 48|1@0+ (1,0) [0|1] "" VCU

BO_ 2554789922 BatP2_BMS_CellVoltageM6: 8 BMS
 SG_ P2_CellVoltage25 : 7|13@0+ (0.001,0) [0|5] "V" VCU
 SG_ P2_CellVoltage26 : 10|13@0+ (0.001,0) [0|5] "V" VCU
 SG_ P2_CellVoltage27 : 29|13@0+ (0.001,0) [0|5] "V" VCU
 SG_ P2_CellVoltage28 : 32|13@0+ (0.001,0) [0|5] "V" VCU
 SG_ P2_BalSwCell25 : 51|1@0+ (1,0) [0|1] "" VCU
 SG_ P2_BalSwCell26 : 50|1@0+ (1,0) [0|1] "" VCU
 SG_ P2_BalSwCell27 : 49|1@0+ (1,0) [0|1] "" VCU
 SG_ P2_BalSwCell28 : 48|1@0+ (1,0) [0|1] "" VCU

BO_ 2554855458 BatP2_BMS_CellVoltageM7: 8 BMS
 SG_ P2_CellVoltage29 : 7|13@0+ (0.001,0) [0|5] "V" VCU
 SG_ P2_CellVoltage30 : 10|13@0+ (0.001,0) [0|5] "V" VCU
 SG_ P2_CellVoltage31 : 29|13@0+ (0.001,0) [0|5] "V" VCU
 SG_ P2_CellVoltage32 : 32|13@0+ (0.001,0) [0|5] "V" VCU
 SG_ P2_BalSwCell29 : 51|1@0+ (1,0) [0|1] "" VCU
 SG_ P2_BalSwCell30 : 50|1@0+ (1,0) [0|1] "" VCU
 SG_ P2_BalSwCell31 : 49|1@0+ (1,0) [0|1] "" VCU
 SG_ P2_BalSwCell32 : 48|1@0+ (1,0) [0|1] "" VCU

BO_ 2554920994 BatP2_BMS_CellVoltageM8: 8 BMS
 SG_ P2_CellVoltage33 : 7|13@0+ (0.001,0) [0|5] "V" VCU
 SG_ P2_CellVoltage34 : 10|13@0+ (0.001,0) [0|5] "V" VCU
 SG_ P2_CellVoltage35 : 29|13@0+ (0.001,0) [0|5] "V" VCU
 SG_ P2_CellVoltage36 : 32|13@0+ (0.001,0) [0|5] "V" VCU
 SG_ P2_BalSwCell33 : 51|1@0+ (1,0) [0|1] "" VCU
 SG_ P2_BalSwCell34 : 50|1@0+ (1,0) [0|1] "" VCU
 SG_ P2_BalSwCell35 : 49|1@0+ (1,0) [0|1] "" VCU
 SG_ P2_BalSwCell36 : 48|1@0+ (1,0) [0|1] "" VCU

BO_ 2554986530 BatP2_BMS_CellVoltageM9: 8 BMS
 SG_ P2_CellVoltage37 : 7|13@0+ (0.001,0) [0|5] "V" VCU
 SG_ P2_CellVoltage38 : 10|13@0+ (0.001,0) [0|5] "V" VCU
 SG_ P2_CellVoltage39 : 29|13@0+ (0.001,0) [0|5] "V" VCU
 SG_ P2_CellVoltage40 : 32|13@0+ (0.001,0) [0|5] "V" VCU
 SG_ P2_BalSwCell37 : 51|1@0+ (1,0) [0|1] "" VCU
 SG_ P2_BalSwCell38 : 50|1@0+ (1,0) [0|1] "" VCU
 SG_ P2_BalSwCell39 : 49|1@0+ (1,0) [0|1] "" VCU
 SG_ P2_BalSwCell40 : 48|1@0+ (1,0) [0|1] "" VCU

BO_ 2555052066 BatP2_BMS_CellVoltageM10: 8 BMS
 SG_ P2_CellVoltage41 : 7|13@0+ (0.001,0) [0|5] "V" VCU
 SG_ P2_CellVoltage42 : 10|13@0+ (0.001,0) [0|5] "V" VCU
 SG_ P2_CellVoltage43 : 29|13@0+ (0.001,0) [0|5] "V" VCU
 SG_ P2_CellVoltage44 : 32|13@0+ (0.001,0) [0|5] "V" VCU
 SG_ P2_BalSwCell41 : 51|1@0+ (1,0) [0|1] "" VCU
 SG_ P2_BalSwCell42 : 50|1@0+ (1,0) [0|1] "" VCU
 SG_ P2_BalSwCell43 : 49|1@0+ (1,0) [0|1] "" VCU
 SG_ P2_BalSwCell44 : 48|1@0+ (1,0) [0|1] "" VCU

BO_ 2555117602 BatP2_BMS_CellVoltageM11: 8 BMS
 SG_ P2_CellVoltage45 : 7|13@0+ (0.001,0) [0|5] "V" VCU
 SG_ P2_CellVoltage46 : 10|13@0+ (0.001,0) [0|5] "V" VCU
 SG_ P2_CellVoltage47 : 29|13@0+ (0.001,0) [0|5] "V" VCU
 SG_ P2_CellVoltage48 : 32|13@0+ (0.001,0) [0|5] "V" VCU
 SG_ P2_BalSwCell45 : 51|1@0+ (1,0) [0|1] "" VCU
 SG_ P2_BalSwCell46 : 50|1@0+ (1,0) [0|1] "" VCU
 SG_ P2_BalSwCell47 : 49|1@0+ (1,0) [0|1] "" VCU
 SG_ P2_BalSwCell48 : 48|1@0+ (1,0) [0|1] "" VCU

BO_ 2555183138 BatP2_BMS_CellVoltageM12: 8 BMS
 SG_ P2_CellVoltage49 : 7|13@0+ (0.001,0) [0|5] "V" VCU
 SG_ P2_CellVoltage50 : 10|13@0+ (0.001,0) [0|5] "V" VCU
 SG_ P2_CellVoltage51 : 29|13@0+ (0.001,0) [0|5] "V" VCU
 SG_ P2_CellVoltage52 : 32|13@0+ (0.001,0) [0|5] "V" VCU
 SG_ P2_BalSwCell49 : 51|1@0+ (1,0) [0|1] "" VCU
 SG_ P2_BalSwCell50 : 50|1@0+ (1,0) [0|1] "" VCU
 SG_ P2_BalSwCell51 : 49|1@0+ (1,0) [0|1] "" VCU
 SG_ P2_BalSwCell52 : 48|1@0+ (1,0) [0|1] "" VCU

BO_ 2555248674 BatP2_BMS_CellVoltageM13: 8 BMS
 SG_ P2_CellVoltage53 : 7|13@0+ (0.001,0) [0|5] "V" VCU
 SG_ P2_CellVoltage54 : 10|13@0+ (0.001,0) [0|5] "V" VCU
 SG_ P2_CellVoltage55 : 29|13@0+ (0.001,0) [0|5] "V" VCU
 SG_ P2_CellVoltage56 : 32|13@0+ (0.001,0) [0|5] "V" VCU
 SG_ P2_BalSwCell53 : 51|1@0+ (1,0) [0|1] "" VCU
 SG_ P2_BalSwCell54 : 50|1@0+ (1,0) [0|1] "" VCU
 SG_ P2_BalSwCell55 : 49|1@0+ (1,0) [0|1] "" VCU
 SG_ P2_BalSwCell56 : 48|1@0+ (1,0) [0|1] "" VCU

BO_ 2555314210 BatP2_BMS_CellVoltageM14: 8 BMS
 SG_ P2_CellVoltage57 : 7|13@0+ (0.001,0) [0|5] "V" VCU
 SG_ P2_CellVoltage58 : 10|13@0+ (0.001,0) [0|5] "V" VCU
 SG_ P2_CellVoltage59 : 29|13@0+ (0.001,0) [0|5] "V" VCU
 SG_ P2_CellVoltage60 : 32|13@0+ (0.001,0) [0|5] "V" VCU
 SG_ P2_BalSwCell57 : 51|1@0+ (1,0) [0|1] "" VCU
 SG_ P2_BalSwCell58 : 50|1@0+ (1,0) [0|1] "" VCU
 SG_ P2_BalSwCell59 : 49|1@0+ (1,0) [0|1] "" VCU
 SG_ P2_BalSwCell60 : 48|1@0+ (1,0) [0|1] "" VCU

BO_ 2555379746 BatP2_BMS_CellVoltageM15: 8 BMS
 SG_ P2_CellVoltage61 : 7|13@0+ (0.001,0) [0|5] "V" VCU
 SG_ P2_CellVoltage62 : 10|13@0+ (0.001,0) [0|5] "V" VCU
 SG_ P2_CellVoltage63 : 29|13@0+ (0.001,0) [0|5] "V" VCU
 SG_ P2_CellVoltage64 : 32|13@0+ (0.001,0) [0|5] "V" VCU
 SG_ P2_BalSwCell61 : 51|1@0+ (1,0) [0|1] "" VCU
 SG_ P2_BalSwCell62 : 50|1@0+ (1,0) [0|1] "" VCU
 SG_ P2_BalSwCell63 : 49|1@0+ (1,0) [0|1] "" VCU
 SG_ P2_BalSwCell64 : 48|1@0+ (1,0) [0|1] "" VCU

BO_ 2555445282 BatP2_BMS_CellVoltageM16: 8 BMS
 SG_ P2_CellVoltage65 : 7|13@0+ (0.001,0) [0|5] "V" VCU
 SG_ P2_CellVoltage66 : 10|13@0+ (0.001,0) [0|5] "V" VCU
 SG_ P2_CellVoltage67 : 29|13@0+ (0.001,0) [0|5] "V" VCU
 SG_ P2_CellVoltage68 : 32|13@0+ (0.001,0) [0|5] "V" VCU
 SG_ P2_BalSwCell65 : 51|1@0+ (1,0) [0|1] "" VCU
 SG_ P2_BalSwCell66 : 50|1@0+ (1,0) [0|1] "" VCU
 SG_ P2_BalSwCell67 : 49|1@0+ (1,0) [0|1] "" VCU
 SG_ P2_BalSwCell68 : 48|1@0+ (1,0) [0|1] "" VCU

BO_ 2555510818 BatP2_BMS_CellVoltageM17: 8 BMS
 SG_ P2_CellVoltage69 : 7|13@0+ (0.001,0) [0|5] "V" VCU
 SG_ P2_CellVoltage70 : 10|13@0+ (0.001,0) [0|5] "V" VCU
 SG_ P2_CellVoltage71 : 29|13@0+ (0.001,0) [0|5] "V" VCU
 SG_ P2_CellVoltage72 : 32|13@0+ (0.001,0) [0|5] "V" VCU
 SG_ P2_BalSwCell69 : 51|1@0+ (1,0) [0|1] "" VCU
 SG_ P2_BalSwCell70 : 50|1@0+ (1,0) [0|1] "" VCU
 SG_ P2_BalSwCell71 : 49|1@0+ (1,0) [0|1] "" VCU
 SG_ P2_BalSwCell72 : 48|1@0+ (1,0) [0|1] "" VCU

BO_ 2555576354 BatP2_BMS_CellVoltageM18: 8 BMS
 SG_ P2_CellVoltage73 : 7|13@0+ (0.001,0) [0|5] "V" VCU
 SG_ P2_CellVoltage74 : 10|13@0+ (0.001,0) [0|5] "V" VCU
 SG_ P2_CellVoltage75 : 29|13@0+ (0.001,0) [0|5] "V" VCU
 SG_ P2_CellVoltage76 : 32|13@0+ (0.001,0) [0|5] "V" VCU
 SG_ P2_BalSwCell73 : 51|1@0+ (1,0) [0|1] "" VCU
 SG_ P2_BalSwCell74 : 50|1@0+ (1,0) [0|1] "" VCU
 SG_ P2_BalSwCell75 : 49|1@0+ (1,0) [0|1] "" VCU
 SG_ P2_BalSwCell76 : 48|1@0+ (1,0) [0|1] "" VCU

BO_ 2555641890 BatP2_BMS_CellVoltageM19: 8 BMS
 SG_ P2_CellVoltage77 : 7|13@0+ (0.001,0) [0|5] "V" VCU
 SG_ P2_CellVoltage78 : 10|13@0+ (0.001,0) [0|5] "V" VCU
 SG_ P2_CellVoltage79 : 29|13@0+ (0.001,0) [0|5] "V" VCU
 SG_ P2_CellVoltage80 : 32|13@0+ (0.001,0) [0|5] "V" VCU
 SG_ P2_BalSwCell77 : 51|1@0+ (1,0) [0|1] "" VCU
 SG_ P2_BalSwCell78 : 50|1@0+ (1,0) [0|1] "" VCU
 SG_ P2_BalSwCell79 : 49|1@0+ (1,0) [0|1] "" VCU
 SG_ P2_BalSwCell80 : 48|1@0+ (1,0) [0|1] "" VCU

BO_ 2555707426 BatP2_BMS_CellVoltageM20: 8 BMS
 SG_ P2_CellVoltage81 : 7|13@0+ (0.001,0) [0|5] "V" VCU
 SG_ P2_CellVoltage82 : 10|13@0+ (0.001,0) [0|5] "V" VCU
 SG_ P2_CellVoltage83 : 29|13@0+ (0.001,0) [0|5] "V" VCU
 SG_ P2_CellVoltage84 : 32|13@0+ (0.001,0) [0|5] "V" VCU
 SG_ P2_BalSwCell81 : 51|1@0+ (1,0) [0|1] "" VCU
 SG_ P2_BalSwCell82 : 50|1@0+ (1,0) [0|1] "" VCU
 SG_ P2_BalSwCell83 : 49|1@0+ (1,0) [0|1] "" VCU
 SG_ P2_BalSwCell84 : 48|1@0+ (1,0) [0|1] "" VCU

BO_ 2555772962 BatP2_BMS_CellVoltageM21: 8 BMS
 SG_ P2_CellVoltage85 : 7|13@0+ (0.001,0) [0|5] "V" VCU
 SG_ P2_CellVoltage86 : 10|13@0+ (0.001,0) [0|5] "V" VCU
 SG_ P2_CellVoltage87 : 29|13@0+ (0.001,0) [0|5] "V" VCU
 SG_ P2_CellVoltage88 : 32|13@0+ (0.001,0) [0|5] "V" VCU
 SG_ P2_BalSwCell85 : 51|1@0+ (1,0) [0|1] "" VCU
 SG_ P2_BalSwCell86 : 50|1@0+ (1,0) [0|1] "" VCU
 SG_ P2_BalSwCell87 : 49|1@0+ (1,0) [0|1] "" VCU
 SG_ P2_BalSwCell88 : 48|1@0+ (1,0) [0|1] "" VCU

BO_ 2555838498 BatP2_BMS_CellVoltageM22: 8 BMS
 SG_ P2_CellVoltage89 : 7|13@0+ (0.001,0) [0|5] "V" VCU
 SG_ P2_CellVoltage90 : 10|13@0+ (0.001,0) [0|5] "V" VCU
 SG_ P2_CellVoltage91 : 29|13@0+ (0.001,0) [0|5] "V" VCU
 SG_ P2_CellVoltage92 : 32|13@0+ (0.001,0) [0|5] "V" VCU
 SG_ P2_BalSwCell89 : 51|1@0+ (1,0) [0|1] "" VCU
 SG_ P2_BalSwCell90 : 50|1@0+ (1,0) [0|1] "" VCU
 SG_ P2_BalSwCell91 : 49|1@0+ (1,0) [0|1] "" VCU
 SG_ P2_BalSwCell92 : 48|1@0+ (1,0) [0|1] "" VCU

BO_ 2555904034 BatP2_BMS_CellVoltageM23: 8 BMS
 SG_ P2_CellVoltage93 : 7|13@0+ (0.001,0) [0|5] "V" VCU
 SG_ P2_CellVoltage94 : 10|13@0+ (0.001,0) [0|5] "V" VCU
 SG_ P2_CellVoltage95 : 29|13@0+ (0.001,0) [0|5] "V" VCU
 SG_ P2_CellVoltage96 : 32|13@0+ (0.001,0) [0|5] "V" VCU
 SG_ P2_BalSwCell93 : 51|1@0+ (1,0) [0|1] "" VCU
 SG_ P2_BalSwCell94 : 50|1@0+ (1,0) [0|1] "" VCU
 SG_ P2_BalSwCell95 : 49|1@0+ (1,0) [0|1] "" VCU
 SG_ P2_BalSwCell96 : 48|1@0+ (1,0) [0|1] "" VCU

BO_ 2555969570 BatP2_BMS_CellVoltageM24: 8 BMS
 SG_ P2_CellVoltage97 : 7|13@0+ (0.001,0) [0|5] "V" VCU
 SG_ P2_CellVoltage98 : 10|13@0+ (0.001,0) [0|5] "V" VCU
 SG_ P2_CellVoltage99 : 29|13@0+ (0.001,0) [0|5] "V" VCU
 SG_ P2_CellVoltage100 : 32|13@0+ (0.001,0) [0|5] "V" VCU
 SG_ P2_BalSwCell97 : 51|1@0+ (1,0) [0|1] "" VCU
 SG_ P2_BalSwCell98 : 50|1@0+ (1,0) [0|1] "" VCU
 SG_ P2_BalSwCell99 : 49|1@0+ (1,0) [0|1] "" VCU
 SG_ P2_BalSwCell100 : 48|1@0+ (1,0) [0|1] "" VCU

BO_ 2556035106 BatP2_BMS_CellVoltageM25: 8 BMS
 SG_ P2_CellVoltage101 : 7|13@0+ (0.001,0) [0|5] "V" VCU
 SG_ P2_CellVoltage102 : 10|13@0+ (0.001,0) [0|5] "V" VCU
 SG_ P2_CellVoltage103 : 29|13@0+ (0.001,0) [0|5] "V" VCU
 SG_ P2_CellVoltage104 : 32|13@0+ (0.001,0) [0|5] "V" VCU
 SG_ P2_BalSwCell101 : 51|1@0+ (1,0) [0|1] "" VCU
 SG_ P2_BalSwCell102 : 50|1@0+ (1,0) [0|1] "" VCU
 SG_ P2_BalSwCell103 : 49|1@0+ (1,0) [0|1] "" VCU
 SG_ P2_BalSwCell104 : 48|1@0+ (1,0) [0|1] "" VCU

BO_ 2556100642 BatP2_BMS_CellVoltageM26: 8 BMS
 SG_ P2_CellVoltage105 : 7|13@0+ (0.001,0) [0|5] "V" VCU
 SG_ P2_CellVoltage106 : 10|13@0+ (0.001,0) [0|5] "V" VCU
 SG_ P2_CellVoltage107 : 29|13@0+ (0.001,0) [0|5] "V" VCU
 SG_ P2_CellVoltage108 : 32|13@0+ (0.001,0) [0|5] "V" VCU
 SG_ P2_BalSwCell105 : 51|1@0+ (1,0) [0|1] "" VCU
 SG_ P2_BalSwCell106 : 50|1@0+ (1,0) [0|1] "" VCU
 SG_ P2_BalSwCell107 : 49|1@0+ (1,0) [0|1] "" VCU
 SG_ P2_BalSwCell108 : 48|1@0+ (1,0) [0|1] "" VCU

BO_ 2556166178 BatP2_BMS_CellVoltageM27: 8 BMS
 SG_ P2_CellVoltage109 : 7|13@0+ (0.001,0) [0|5] "V" VCU
 SG_ P2_CellVoltage110 : 10|13@0+ (0.001,0) [0|5] "V" VCU
 SG_ P2_CellVoltage111 : 29|13@0+ (0.001,0) [0|5] "V" VCU
 SG_ P2_CellVoltage112 : 32|13@0+ (0.001,0) [0|5] "V" VCU
 SG_ P2_BalSwCell109 : 51|1@0+ (1,0) [0|1] "" VCU
 SG_ P2_BalSwCell110 : 50|1@0+ (1,0) [0|1] "" VCU
 SG_ P2_BalSwCell111 : 49|1@0+ (1,0) [0|1] "" VCU
 SG_ P2_BalSwCell112 : 48|1@0+ (1,0) [0|1] "" VCU

BO_ 2556231714 BatP2_BMS_CellVoltageM28: 8 BMS
 SG_ P2_CellVoltage113 : 7|13@0+ (0.001,0) [0|5] "V" VCU
 SG_ P2_CellVoltage114 : 10|13@0+ (0.001,0) [0|5] "V" VCU
 SG_ P2_CellVoltage115 : 29|13@0+ (0.001,0) [0|5] "V" VCU
 SG_ P2_CellVoltage116 : 32|13@0+ (0.001,0) [0|5] "V" VCU
 SG_ P2_BalSwCell113 : 51|1@0+ (1,0) [0|1] "" VCU
 SG_ P2_BalSwCell114 : 50|1@0+ (1,0) [0|1] "" VCU
 SG_ P2_BalSwCell115 : 49|1@0+ (1,0) [0|1] "" VCU
 SG_ P2_BalSwCell116 : 48|1@0+ (1,0) [0|1] "" VCU

BO_ 2556297250 BatP2_BMS_CellVoltageM29: 8 BMS
 SG_ P2_CellVoltage117 : 7|13@0+ (0.001,0) [0|5] "V" VCU
 SG_ P2_CellVoltage118 : 10|13@0+ (0.001,0) [0|5] "V" VCU
 SG_ P2_CellVoltage119 : 29|13@0+ (0.001,0) [0|5] "V" VCU
 SG_ P2_CellVoltage120 : 32|13@0+ (0.001,0) [0|5] "V" VCU
 SG_ P2_BalSwCell117 : 51|1@0+ (1,0) [0|1] "" VCU
 SG_ P2_BalSwCell118 : 50|1@0+ (1,0) [0|1] "" VCU
 SG_ P2_BalSwCell119 : 49|1@0+ (1,0) [0|1] "" VCU
 SG_ P2_BalSwCell120 : 48|1@0+ (1,0) [0|1] "" VCU

BO_ 2556362786 BatP2_BMS_CellVoltageM30: 8 BMS
 SG_ P2_CellVoltage121 : 7|13@0+ (0.001,0) [0|5] "V" VCU
 SG_ P2_CellVoltage122 : 10|13@0+ (0.001,0) [0|5] "V" VCU
 SG_ P2_CellVoltage123 : 29|13@0+ (0.001,0) [0|5] "V" VCU
 SG_ P2_CellVoltage124 : 32|13@0+ (0.001,0) [0|5] "V" VCU
 SG_ P2_BalSwCell121 : 51|1@0+ (1,0) [0|1] "" VCU
 SG_ P2_BalSwCell122 : 50|1@0+ (1,0) [0|1] "" VCU
 SG_ P2_BalSwCell123 : 49|1@0+ (1,0) [0|1] "" VCU
 SG_ P2_BalSwCell124 : 48|1@0+ (1,0) [0|1] "" VCU

BO_ 2556428322 BatP2_BMS_CellVoltageM31: 8 BMS
 SG_ P2_CellVoltage125 : 7|13@0+ (0.001,0) [0|5] "V" VCU
 SG_ P2_CellVoltage126 : 10|13@0+ (0.001,0) [0|5] "V" VCU
 SG_ P2_CellVoltage127 : 29|13@0+ (0.001,0) [0|5] "V" VCU
 SG_ P2_CellVoltage128 : 32|13@0+ (0.001,0) [0|5] "V" VCU
 SG_ P2_BalSwCell125 : 51|1@0+ (1,0) [0|1] "" VCU
 SG_ P2_BalSwCell126 : 50|1@0+ (1,0) [0|1] "" VCU
 SG_ P2_BalSwCell127 : 49|1@0+ (1,0) [0|1] "" VCU
 SG_ P2_BalSwCell128 : 48|1@0+ (1,0) [0|1] "" VCU

BO_ 2556493858 BatP2_BMS_CellVoltageM32: 8 BMS
 SG_ P2_CellVoltage129 : 7|13@0+ (0.001,0) [0|5] "V" VCU
 SG_ P2_CellVoltage130 : 10|13@0+ (0.001,0) [0|5] "V" VCU
 SG_ P2_CellVoltage131 : 29|13@0+ (0.001,0) [0|5] "V" VCU
 SG_ P2_CellVoltage132 : 32|13@0+ (0.001,0) [0|5] "V" VCU
 SG_ P2_BalSwCell129 : 51|1@0+ (1,0) [0|1] "" VCU
 SG_ P2_BalSwCell130 : 50|1@0+ (1,0) [0|1] "" VCU
 SG_ P2_BalSwCell131 : 49|1@0+ (1,0) [0|1] "" VCU
 SG_ P2_BalSwCell132 : 48|1@0+ (1,0) [0|1] "" VCU

BO_ 2556559394 BatP2_BMS_CellVoltageM33: 8 BMS
 SG_ P2_CellVoltage133 : 7|13@0+ (0.001,0) [0|5] "V" VCU
 SG_ P2_CellVoltage134 : 10|13@0+ (0.001,0) [0|5] "V" VCU
 SG_ P2_CellVoltage135 : 29|13@0+ (0.001,0) [0|5] "V" VCU
 SG_ P2_CellVoltage136 : 32|13@0+ (0.001,0) [0|5] "V" VCU
 SG_ P2_BalSwCell133 : 51|1@0+ (1,0) [0|1] "" VCU
 SG_ P2_BalSwCell134 : 50|1@0+ (1,0) [0|1] "" VCU
 SG_ P2_BalSwCell135 : 49|1@0+ (1,0) [0|1] "" VCU
 SG_ P2_BalSwCell136 : 48|1@0+ (1,0) [0|1] "" VCU

BO_ 2556624930 BatP2_BMS_CellVoltageM34: 8 BMS
 SG_ P2_CellVoltage137 : 7|13@0+ (0.001,0) [0|5] "V" VCU
 SG_ P2_CellVoltage138 : 10|13@0+ (0.001,0) [0|5] "V" VCU
 SG_ P2_CellVoltage139 : 29|13@0+ (0.001,0) [0|5] "V" VCU
 SG_ P2_CellVoltage140 : 32|13@0+ (0.001,0) [0|5] "V" VCU
 SG_ P2_BalSwCell137 : 51|1@0+ (1,0) [0|1] "" VCU
 SG_ P2_BalSwCell138 : 50|1@0+ (1,0) [0|1] "" VCU
 SG_ P2_BalSwCell139 : 49|1@0+ (1,0) [0|1] "" VCU
 SG_ P2_BalSwCell140 : 48|1@0+ (1,0) [0|1] "" VCU

BO_ 2556690466 BatP2_BMS_CellVoltageM35: 8 BMS
 SG_ P2_CellVoltage141 : 7|13@0+ (0.001,0) [0|5] "V" VCU
 SG_ P2_CellVoltage142 : 10|13@0+ (0.001,0) [0|5] "V" VCU
 SG_ P2_CellVoltage143 : 29|13@0+ (0.001,0) [0|5] "V" VCU
 SG_ P2_CellVoltage144 : 32|13@0+ (0.001,0) [0|5] "V" VCU
 SG_ P2_BalSwCell141 : 51|1@0+ (1,0) [0|1] "" VCU
 SG_ P2_BalSwCell142 : 50|1@0+ (1,0) [0|1] "" VCU
 SG_ P2_BalSwCell143 : 49|1@0+ (1,0) [0|1] "" VCU
 SG_ P2_BalSwCell144 : 48|1@0+ (1,0) [0|1] "" VCU

BO_ 2556756002 BatP2_BMS_CellVoltageM36: 8 BMS
 SG_ P2_CellVoltage145 : 7|13@0+ (0.001,0) [0|5] "V" VCU
 SG_ P2_CellVoltage146 : 10|13@0+ (0.001,0) [0|5] "V" VCU
 SG_ P2_CellVoltage147 : 29|13@0+ (0.001,0) [0|5] "V" VCU
 SG_ P2_CellVoltage148 : 32|13@0+ (0.001,0) [0|5] "V" VCU
 SG_ P2_BalSwCell145 : 51|1@0+ (1,0) [0|1] "" VCU
 SG_ P2_BalSwCell146 : 50|1@0+ (1,0) [0|1] "" VCU
 SG_ P2_BalSwCell147 : 49|1@0+ (1,0) [0|1] "" VCU
 SG_ P2_BalSwCell148 : 48|1@0+ (1,0) [0|1] "" VCU

BO_ 2556821538 BatP2_BMS_CellVoltageM37: 8 BMS
 SG_ P2_CellVoltage149 : 7|13@0+ (0.001,0) [0|5] "V" VCU
 SG_ P2_CellVoltage150 : 10|13@0+ (0.001,0) [0|5] "V" VCU
 SG_ P2_CellVoltage151 : 29|13@0+ (0.001,0) [0|5] "V" VCU
 SG_ P2_CellVoltage152 : 32|13@0+ (0.001,0) [0|5] "V" VCU
 SG_ P2_BalSwCell149 : 51|1@0+ (1,0) [0|1] "" VCU
 SG_ P2_BalSwCell150 : 50|1@0+ (1,0) [0|1] "" VCU
 SG_ P2_BalSwCell151 : 49|1@0+ (1,0) [0|1] "" VCU
 SG_ P2_BalSwCell152 : 48|1@0+ (1,0) [0|1] "" VCU

BO_ 2556887074 BatP2_BMS_CellVoltageM38: 8 BMS
 SG_ P2_CellVoltage153 : 7|13@0+ (0.001,0) [0|5] "V" VCU
 SG_ P2_CellVoltage154 : 10|13@0+ (0.001,0) [0|5] "V" VCU
 SG_ P2_CellVoltage155 : 29|13@0+ (0.001,0) [0|5] "V" VCU
 SG_ P2_CellVoltage156 : 32|13@0+ (0.001,0) [0|5] "V" VCU
 SG_ P2_BalSwCell153 : 51|1@0+ (1,0) [0|1] "" VCU
 SG_ P2_BalSwCell154 : 50|1@0+ (1,0) [0|1] "" VCU
 SG_ P2_BalSwCell155 : 49|1@0+ (1,0) [0|1] "" VCU
 SG_ P2_BalSwCell156 : 48|1@0+ (1,0) [0|1] "" VCU

BO_ 2556952610 BatP2_BMS_CellVoltageM39: 8 BMS
 SG_ P2_CellVoltage157 : 7|13@0+ (0.001,0) [0|5] "V" VCU
 SG_ P2_CellVoltage158 : 10|13@0+ (0.001,0) [0|5] "V" VCU
 SG_ P2_CellVoltage159 : 29|13@0+ (0.001,0) [0|5] "V" VCU
 SG_ P2_CellVoltage160 : 32|13@0+ (0.001,0) [0|5] "V" VCU
 SG_ P2_BalSwCell157 : 51|1@0+ (1,0) [0|1] "" VCU
 SG_ P2_BalSwCell158 : 50|1@0+ (1,0) [0|1] "" VCU
 SG_ P2_BalSwCell159 : 49|1@0+ (1,0) [0|1] "" VCU
 SG_ P2_BalSwCell160 : 48|1@0+ (1,0) [0|1] "" VCU

BO_ 2557018146 BatP2_BMS_CellVoltageM40: 8 BMS
 SG_ P2_CellVoltage161 : 7|13@0+ (0.001,0) [0|5] "V" VCU
 SG_ P2_CellVoltage162 : 10|13@0+ (0.001,0) [0|5] "V" VCU
 SG_ P2_CellVoltage163 : 29|13@0+ (0.001,0) [0|5] "V" VCU
 SG_ P2_CellVoltage164 : 32|13@0+ (0.001,0) [0|5] "V" VCU
 SG_ P2_BalSwCell161 : 51|1@0+ (1,0) [0|1] "" VCU
 SG_ P2_BalSwCell162 : 50|1@0+ (1,0) [0|1] "" VCU
 SG_ P2_BalSwCell163 : 49|1@0+ (1,0) [0|1] "" VCU
 SG_ P2_BalSwCell164 : 48|1@0+ (1,0) [0|1] "" VCU

BO_ 2557083682 BatP2_BMS_CellVoltageM41: 8 BMS
 SG_ P2_CellVoltage165 : 7|13@0+ (0.001,0) [0|5] "V" VCU
 SG_ P2_CellVoltage166 : 10|13@0+ (0.001,0) [0|5] "V" VCU
 SG_ P2_CellVoltage167 : 29|13@0+ (0.001,0) [0|5] "V" VCU
 SG_ P2_CellVoltage168 : 32|13@0+ (0.001,0) [0|5] "V" VCU
 SG_ P2_BalSwCell165 : 51|1@0+ (1,0) [0|1] "" VCU
 SG_ P2_BalSwCell166 : 50|1@0+ (1,0) [0|1] "" VCU
 SG_ P2_BalSwCell167 : 49|1@0+ (1,0) [0|1] "" VCU
 SG_ P2_BalSwCell168 : 48|1@0+ (1,0) [0|1] "" VCU

BO_ 2557149218 BatP2_BMS_CellVoltageM42: 8 BMS
 SG_ P2_CellVoltage169 : 7|13@0+ (0.001,0) [0|5] "V" VCU
 SG_ P2_CellVoltage170 : 10|13@0+ (0.001,0) [0|5] "V" VCU
 SG_ P2_CellVoltage171 : 29|13@0+ (0.001,0) [0|5] "V" VCU
 SG_ P2_CellVoltage172 : 32|13@0+ (0.001,0) [0|5] "V" VCU
 SG_ P2_BalSwCell169 : 51|1@0+ (1,0) [0|1] "" VCU
 SG_ P2_BalSwCell170 : 50|1@0+ (1,0) [0|1] "" VCU
 SG_ P2_BalSwCell171 : 49|1@0+ (1,0) [0|1] "" VCU
 SG_ P2_BalSwCell172 : 48|1@0+ (1,0) [0|1] "" VCU

BO_ 2557214754 BatP2_BMS_CellVoltageM43: 8 BMS
 SG_ P2_CellVoltage173 : 7|13@0+ (0.001,0) [0|5] "V" VCU
 SG_ P2_CellVoltage174 : 10|13@0+ (0.001,0) [0|5] "V" VCU
 SG_ P2_CellVoltage175 : 29|13@0+ (0.001,0) [0|5] "V" VCU
 SG_ P2_CellVoltage176 : 32|13@0+ (0.001,0) [0|5] "V" VCU
 SG_ P2_BalSwCell173 : 51|1@0+ (1,0) [0|1] "" VCU
 SG_ P2_BalSwCell174 : 50|1@0+ (1,0) [0|1] "" VCU
 SG_ P2_BalSwCell175 : 49|1@0+ (1,0) [0|1] "" VCU
 SG_ P2_BalSwCell176 : 48|1@0+ (1,0) [0|1] "" VCU

BO_ 2557280290 BatP2_BMS_CellVoltageM44: 8 BMS
 SG_ P2_CellVoltage177 : 7|13@0+ (0.001,0) [0|5] "V" VCU
 SG_ P2_CellVoltage178 : 10|13@0+ (0.001,0) [0|5] "V" VCU
 SG_ P2_CellVoltage179 : 29|13@0+ (0.001,0) [0|5] "V" VCU
 SG_ P2_CellVoltage180 : 32|13@0+ (0.001,0) [0|5] "V" VCU
 SG_ P2_BalSwCell177 : 51|1@0+ (1,0) [0|1] "" VCU
 SG_ P2_BalSwCell178 : 50|1@0+ (1,0) [0|1] "" VCU
 SG_ P2_BalSwCell179 : 49|1@0+ (1,0) [0|1] "" VCU
 SG_ P2_BalSwCell180 : 48|1@0+ (1,0) [0|1] "" VCU

BO_ 2557345826 BatP2_BMS_CellVoltageM45: 8 BMS
 SG_ P2_CellVoltage181 : 7|13@0+ (0.001,0) [0|5] "V" VCU
 SG_ P2_CellVoltage182 : 10|13@0+ (0.001,0) [0|5] "V" VCU
 SG_ P2_CellVoltage183 : 29|13@0+ (0.001,0) [0|5] "V" VCU
 SG_ P2_CellVoltage184 : 32|13@0+ (0.001,0) [0|5] "V" VCU
 SG_ P2_BalSwCell181 : 51|1@0+ (1,0) [0|1] "" VCU
 SG_ P2_BalSwCell182 : 50|1@0+ (1,0) [0|1] "" VCU
 SG_ P2_BalSwCell183 : 49|1@0+ (1,0) [0|1] "" VCU
 SG_ P2_BalSwCell184 : 48|1@0+ (1,0) [0|1] "" VCU

BO_ 2557411362 BatP2_BMS_CellVoltageM46: 8 BMS
 SG_ P2_CellVoltage185 : 7|13@0+ (0.001,0) [0|5] "V" VCU
 SG_ P2_CellVoltage186 : 10|13@0+ (0.001,0) [0|5] "V" VCU
 SG_ P2_CellVoltage187 : 29|13@0+ (0.001,0) [0|5] "V" VCU
 SG_ P2_CellVoltage188 : 32|13@0+ (0.001,0) [0|5] "V" VCU
 SG_ P2_BalSwCell185 : 51|1@0+ (1,0) [0|1] "" VCU
 SG_ P2_BalSwCell186 : 50|1@0+ (1,0) [0|1] "" VCU
 SG_ P2_BalSwCell187 : 49|1@0+ (1,0) [0|1] "" VCU
 SG_ P2_BalSwCell188 : 48|1@0+ (1,0) [0|1] "" VCU

BO_ 2557476898 BatP2_BMS_CellVoltageM47: 8 BMS
 SG_ P2_CellVoltage189 : 7|13@0+ (0.001,0) [0|5] "V" VCU
 SG_ P2_CellVoltage190 : 10|13@0+ (0.001,0) [0|5] "V" VCU
 SG_ P2_CellVoltage191 : 29|13@0+ (0.001,0) [0|5] "V" VCU
 SG_ P2_CellVoltage192 : 32|13@0+ (0.001,0) [0|5] "V" VCU
 SG_ P2_BalSwCell189 : 51|1@0+ (1,0) [0|1] "" VCU
 SG_ P2_BalSwCell190 : 50|1@0+ (1,0) [0|1] "" VCU
 SG_ P2_BalSwCell191 : 49|1@0+ (1,0) [0|1] "" VCU
 SG_ P2_BalSwCell192 : 48|1@0+ (1,0) [0|1] "" VCU

BO_ 2558525474 BatP2_BMS_CellTempM0: 8 BMS
 SG_ P2_CellTemp1 : 7|11@0+ (0.1,-40) [-40|150] "C" VCU
 SG_ P2_CellTemp2 : 12|11@0+ (0.1,-40) [-40|150] "C" VCU
 SG_ P2_CellTemp3 : 17|11@0+ (0.1,-40) [-40|150] "C" VCU
 SG_ P2_CellTemp4 : 38|11@0+ (0.1,-40) [-40|150] "C" VCU
 SG_ P2_CellTemp5 : 43|11@0+ (0.1,-40) [-40|150] "C" VCU

BO_ 2558591010 BatP2_BMS_CellTempM1: 8 BMS
 SG_ P2_CellTemp6 : 7|11@0+ (0.1,-40) [-40|150] "C" VCU
 SG_ P2_CellTemp7 : 12|11@0+ (0.1,-40) [-40|150] "C" VCU
 SG_ P2_CellTemp8 : 17|11@0+ (0.1,-40) [-40|150] "C" VCU
 SG_ P2_CellTemp9 : 38|11@0+ (0.1,-40) [-40|150] "C" VCU
 SG_ P2_CellTemp10 : 43|11@0+ (0.1,-40) [-40|150] "C" VCU

BO_ 2558656546 BatP2_BMS_CellTempM2: 8 BMS
 SG_ P2_CellTemp11 : 7|11@0+ (0.1,-40) [-40|150] "C" VCU
 SG_ P2_CellTemp12 : 12|11@0+ (0.1,-40) [-40|150] "C" VCU
 SG_ P2_CellTemp13 : 17|11@0+ (0.1,-40) [-40|150] "C" VCU
 SG_ P2_CellTemp14 : 38|11@0+ (0.1,-40) [-40|150] "C" VCU
 SG_ P2_CellTemp15 : 43|11@0+ (0.1,-40) [-40|150] "C" VCU

BO_ 2558722082 BatP2_BMS_CellTempM3: 8 BMS
 SG_ P2_CellTemp16 : 7|11@0+ (0.1,-40) [-40|150] "C" VCU
 SG_ P2_CellTemp17 : 12|11@0+ (0.1,-40) [-40|150] "C" VCU
 SG_ P2_CellTemp18 : 17|11@0+ (0.1,-40) [-40|150] "C" VCU
 SG_ P2_CellTemp19 : 38|11@0+ (0.1,-40) [-40|150] "C" VCU
 SG_ P2_CellTemp20 : 43|11@0+ (0.1,-40) [-40|150] "C" VCU

BO_ 2558787618 BatP2_BMS_CellTempM4: 8 BMS
 SG_ P2_CellTemp21 : 7|11@0+ (0.1,-40) [-40|150] "C" VCU
 SG_ P2_CellTemp22 : 12|11@0+ (0.1,-40) [-40|150] "C" VCU
 SG_ P2_CellTemp23 : 17|11@0+ (0.1,-40) [-40|150] "C" VCU
 SG_ P2_CellTemp24 : 38|11@0+ (0.1,-40) [-40|150] "C" VCU
 SG_ P2_CellTemp25 : 43|11@0+ (0.1,-40) [-40|150] "C" VCU

BO_ 2558853154 BatP2_BMS_CellTempM5: 8 BMS
 SG_ P2_CellTemp26 : 7|11@0+ (0.1,-40) [-40|150] "C" VCU
 SG_ P2_CellTemp27 : 12|11@0+ (0.1,-40) [-40|150] "C" VCU
 SG_ P2_CellTemp28 : 17|11@0+ (0.1,-40) [-40|150] "C" VCU
 SG_ P2_CellTemp29 : 38|11@0+ (0.1,-40) [-40|150] "C" VCU
 SG_ P2_CellTemp30 : 43|11@0+ (0.1,-40) [-40|150] "C" VCU

BO_ 2558918690 BatP2_BMS_CellTempM6: 8 BMS
 SG_ P2_CellTemp31 : 7|11@0+ (0.1,-40) [-40|150] "C" VCU
 SG_ P2_CellTemp32 : 12|11@0+ (0.1,-40) [-40|150] "C" VCU
 SG_ P2_CellTemp33 : 17|11@0+ (0.1,-40) [-40|150] "C" VCU
 SG_ P2_CellTemp34 : 38|11@0+ (0.1,-40) [-40|150] "C" VCU
 SG_ P2_CellTemp35 : 43|11@0+ (0.1,-40) [-40|150] "C" VCU

BO_ 2558984226 BatP2_BMS_CellTempM7: 8 BMS
 SG_ P2_CellTemp36 : 7|11@0+ (0.1,-40) [-40|150] "C" VCU
 SG_ P2_CellTemp37 : 12|11@0+ (0.1,-40) [-40|150] "C" VCU
 SG_ P2_CellTemp38 : 17|11@0+ (0.1,-40) [-40|150] "C" VCU
 SG_ P2_CellTemp39 : 38|11@0+ (0.1,-40) [-40|150] "C" VCU
 SG_ P2_CellTemp40 : 43|11@0+ (0.1,-40) [-40|150] "C" VCU

BO_ 2559049762 BatP2_BMS_CellTempM8: 8 BMS
 SG_ P2_CellTemp41 : 7|11@0+ (0.1,-40) [-40|150] "C" VCU
 SG_ P2_CellTemp42 : 12|11@0+ (0.1,-40) [-40|150] "C" VCU
 SG_ P2_CellTemp43 : 17|11@0+ (0.1,-40) [-40|150] "C" VCU
 SG_ P2_CellTemp44 : 38|11@0+ (0.1,-40) [-40|150] "C" VCU
 SG_ P2_CellTemp45 : 43|11@0+ (0.1,-40) [-40|150] "C" VCU

BO_ 2559115298 BatP2_BMS_CellTempM9: 8 BMS
 SG_ P2_CellTemp46 : 7|11@0+ (0.1,-40) [-40|150] "C" VCU
 SG_ P2_CellTemp47 : 12|11@0+ (0.1,-40) [-40|150] "C" VCU
 SG_ P2_CellTemp48 : 17|11@0+ (0.1,-40) [-40|150] "C" VCU
 SG_ P2_CellTemp49 : 38|11@0+ (0.1,-40) [-40|150] "C" VCU
 SG_ P2_CellTemp50 : 43|11@0+ (0.1,-40) [-40|150] "C" VCU

BO_ 2559180834 BatP2_BMS_CellTempM10: 8 BMS
 SG_ P2_CellTemp51 : 7|11@0+ (0.1,-40) [-40|150] "C" VCU
 SG_ P2_CellTemp52 : 12|11@0+ (0.1,-40) [-40|150] "C" VCU
 SG_ P2_CellTemp53 : 17|11@0+ (0.1,-40) [-40|150] "C" VCU
 SG_ P2_CellTemp54 : 38|11@0+ (0.1,-40) [-40|150] "C" VCU
 SG_ P2_CellTemp55 : 43|11@0+ (0.1,-40) [-40|150] "C" VCU

BO_ 2559246370 BatP2_BMS_CellTempM11: 8 BMS
 SG_ P2_CellTemp56 : 7|11@0+ (0.1,-40) [-40|150] "C" VCU
 SG_ P2_CellTemp57 : 12|11@0+ (0.1,-40) [-40|150] "C" VCU
 SG_ P2_CellTemp58 : 17|11@0+ (0.1,-40) [-40|150] "C" VCU
 SG_ P2_CellTemp59 : 38|11@0+ (0.1,-40) [-40|150] "C" VCU
 SG_ P2_CellTemp60 : 43|11@0+ (0.1,-40) [-40|150] "C" VCU

BO_ 2559311906 BatP2_BMS_CellTempM12: 8 BMS
 SG_ P2_CellTemp61 : 7|11@0+ (0.1,-40) [-40|150] "C" VCU
 SG_ P2_CellTemp62 : 12|11@0+ (0.1,-40) [-40|150] "C" VCU
 SG_ P2_CellTemp63 : 17|11@0+ (0.1,-40) [-40|150] "C" VCU
 SG_ P2_CellTemp64 : 38|11@0+ (0.1,-40) [-40|150] "C" VCU
 SG_ P2_CellTemp65 : 43|11@0+ (0.1,-40) [-40|150] "C" VCU

BO_ 2559377442 BatP2_BMS_CellTempM13: 8 BMS
 SG_ P2_CellTemp66 : 7|11@0+ (0.1,-40) [-40|150] "C" VCU
 SG_ P2_CellTemp67 : 12|11@0+ (0.1,-40) [-40|150] "C" VCU
 SG_ P2_CellTemp68 : 17|11@0+ (0.1,-40) [-40|150] "C" VCU
 SG_ P2_CellTemp69 : 38|11@0+ (0.1,-40) [-40|150] "C" VCU
 SG_ P2_CellTemp70 : 43|11@0+ (0.1,-40) [-40|150] "C" VCU

BO_ 2559442978 BatP2_BMS_CellTempM14: 8 BMS
 SG_ P2_CellTemp71 : 7|11@0+ (0.1,-40) [-40|150] "C" VCU
 SG_ P2_CellTemp72 : 12|11@0+ (0.1,-40) [-40|150] "C" VCU
 SG_ P2_CellTemp73 : 17|11@0+ (0.1,-40) [-40|150] "C" VCU
 SG_ P2_CellTemp74 : 38|11@0+ (0.1,-40) [-40|150] "C" VCU
 SG_ P2_CellTemp75 : 43|11@0+ (0.1,-40) [-40|150] "C" VCU

BO_ 2559508514 BatP2_BMS_CellTempM15: 8 BMS
 SG_ P2_CellTemp76 : 7|11@0+ (0.1,-40) [-40|150] "C" VCU
 SG_ P2_CellTemp77 : 12|11@0+ (0.1,-40) [-40|150] "C" VCU
 SG_ P2_CellTemp78 : 17|11@0+ (0.1,-40) [-40|150] "C" VCU
 SG_ P2_CellTemp79 : 38|11@0+ (0.1,-40) [-40|150] "C" VCU
 SG_ P2_CellTemp80 : 43|11@0+ (0.1,-40) [-40|150] "C" VCU

BO_ 2559574050 BatP2_BMS_CellTempM16: 8 BMS
 SG_ P2_CellTemp81 : 7|11@0+ (0.1,-40) [-40|150] "C" VCU
 SG_ P2_CellTemp82 : 12|11@0+ (0.1,-40) [-40|150] "C" VCU
 SG_ P2_CellTemp83 : 17|11@0+ (0.1,-40) [-40|150] "C" VCU
 SG_ P2_CellTemp84 : 38|11@0+ (0.1,-40) [-40|150] "C" VCU
 SG_ P2_CellTemp85 : 43|11@0+ (0.1,-40) [-40|150] "C" VCU

BO_ 2559639586 BatP2_BMS_CellTempM17: 8 BMS
 SG_ P2_CellTemp86 : 7|11@0+ (0.1,-40) [-40|150] "C" VCU
 SG_ P2_CellTemp87 : 12|11@0+ (0.1,-40) [-40|150] "C" VCU
 SG_ P2_CellTemp88 : 17|11@0+ (0.1,-40) [-40|150] "C" VCU
 SG_ P2_CellTemp89 : 38|11@0+ (0.1,-40) [-40|150] "C" VCU
 SG_ P2_CellTemp90 : 43|11@0+ (0.1,-40) [-40|150] "C" VCU

BO_ 2559705122 BatP2_BMS_CellTempM18: 8 BMS
 SG_ P2_CellTemp91 : 7|11@0+ (0.1,-40) [-40|150] "C" VCU
 SG_ P2_CellTemp92 : 12|11@0+ (0.1,-40) [-40|150] "C" VCU
 SG_ P2_CellTemp93 : 17|11@0+ (0.1,-40) [-40|150] "C" VCU
 SG_ P2_CellTemp94 : 38|11@0+ (0.1,-40) [-40|150] "C" VCU
 SG_ P2_CellTemp95 : 43|11@0+ (0.1,-40) [-40|150] "C" VCU

BO_ 2559770658 BatP2_BMS_CellTempM19: 8 BMS
 SG_ P2_CellTemp96 : 7|11@0+ (0.1,-40) [-40|150] "C" VCU
 SG_ P2_CellTemp97 : 12|11@0+ (0.1,-40) [-40|150] "C" VCU
 SG_ P2_CellTemp98 : 17|11@0+ (0.1,-40) [-40|150] "C" VCU
 SG_ P2_CellTemp99 : 38|11@0+ (0.1,-40) [-40|150] "C" VCU
 SG_ P2_CellTemp100 : 43|11@0+ (0.1,-40) [-40|150] "C" VCU

BO_ 2559836194 BatP2_BMS_CellTempM20: 8 BMS
 SG_ P2_CellTemp101 : 7|11@0+ (0.1,-40) [-40|150] "C" VCU
 SG_ P2_CellTemp102 : 12|11@0+ (0.1,-40) [-40|150] "C" VCU
 SG_ P2_CellTemp103 : 17|11@0+ (0.1,-40) [-40|150] "C" VCU
 SG_ P2_CellTemp104 : 38|11@0+ (0.1,-40) [-40|150] "C" VCU
 SG_ P2_CellTemp105 : 43|11@0+ (0.1,-40) [-40|150] "C" VCU

BO_ 2559901730 BatP2_BMS_CellTempM21: 8 BMS
 SG_ P2_CellTemp106 : 7|11@0+ (0.1,-40) [-40|150] "C" VCU
 SG_ P2_CellTemp107 : 12|11@0+ (0.1,-40) [-40|150] "C" VCU
 SG_ P2_CellTemp108 : 17|11@0+ (0.1,-40) [-40|150] "C" VCU
 SG_ P2_CellTemp109 : 38|11@0+ (0.1,-40) [-40|150] "C" VCU
 SG_ P2_CellTemp110 : 43|11@0+ (0.1,-40) [-40|150] "C" VCU

BO_ 2559967266 BatP2_BMS_CellTempM22: 8 BMS
 SG_ P2_CellTemp111 : 7|11@0+ (0.1,-40) [-40|150] "C" VCU
 SG_ P2_CellTemp112 : 12|11@0+ (0.1,-40) [-40|150] "C" VCU
 SG_ P2_CellTemp113 : 17|11@0+ (0.1,-40) [-40|150] "C" VCU
 SG_ P2_CellTemp114 : 38|11@0+ (0.1,-40) [-40|150] "C" VCU
 SG_ P2_CellTemp115 : 43|11@0+ (0.1,-40) [-40|150] "C" VCU

BO_ 2560032802 BatP2_BMS_CellTempM23: 8 BMS
 SG_ P2_CellTemp116 : 7|11@0+ (0.1,-40) [-40|150] "C" VCU
 SG_ P2_CellTemp117 : 12|11@0+ (0.1,-40) [-40|150] "C" VCU
 SG_ P2_CellTemp118 : 17|11@0+ (0.1,-40) [-40|150] "C" VCU
 SG_ P2_CellTemp119 : 38|11@0+ (0.1,-40) [-40|150] "C" VCU
 SG_ P2_CellTemp120 : 43|11@0+ (0.1,-40) [-40|150] "C" VCU

BO_ 2560098338 BatP2_BMS_CellTempM24: 8 BMS
 SG_ P2_CellTemp121 : 7|11@0+ (0.1,-40) [-40|150] "C" VCU
 SG_ P2_CellTemp122 : 12|11@0+ (0.1,-40) [-40|150] "C" VCU
 SG_ P2_CellTemp123 : 17|11@0+ (0.1,-40) [-40|150] "C" VCU
 SG_ P2_CellTemp124 : 38|11@0+ (0.1,-40) [-40|150] "C" VCU
 SG_ P2_CellTemp125 : 43|11@0+ (0.1,-40) [-40|150] "C" VCU

BO_ 2560163874 BatP2_BMS_CellTempM25: 8 BMS
 SG_ P2_CellTemp126 : 7|11@0+ (0.1,-40) [-40|150] "C" VCU
 SG_ P2_CellTemp127 : 12|11@0+ (0.1,-40) [-40|150] "C" VCU
 SG_ P2_CellTemp128 : 17|11@0+ (0.1,-40) [-40|150] "C" VCU
 SG_ P2_CellTemp129 : 38|11@0+ (0.1,-40) [-40|150] "C" VCU
 SG_ P2_CellTemp130 : 43|11@0+ (0.1,-40) [-40|150] "C" VCU

BO_ 2560229410 BatP2_BMS_CellTempM26: 8 BMS
 SG_ P2_CellTemp131 : 7|11@0+ (0.1,-40) [-40|150] "C" VCU
 SG_ P2_CellTemp132 : 12|11@0+ (0.1,-40) [-40|150] "C" VCU
 SG_ P2_CellTemp133 : 17|11@0+ (0.1,-40) [-40|150] "C" VCU
 SG_ P2_CellTemp134 : 38|11@0+ (0.1,-40) [-40|150] "C" VCU
 SG_ P2_CellTemp135 : 43|11@0+ (0.1,-40) [-40|150] "C" VCU

BO_ 2560294946 BatP2_BMS_CellTempM27: 8 BMS
 SG_ P2_CellTemp136 : 7|11@0+ (0.1,-40) [-40|150] "C" VCU
 SG_ P2_CellTemp137 : 12|11@0+ (0.1,-40) [-40|150] "C" VCU
 SG_ P2_CellTemp138 : 17|11@0+ (0.1,-40) [-40|150] "C" VCU
 SG_ P2_CellTemp139 : 38|11@0+ (0.1,-40) [-40|150] "C" VCU
 SG_ P2_CellTemp140 : 43|11@0+ (0.1,-40) [-40|150] "C" VCU

BO_ 2560360482 BatP2_BMS_CellTempM28: 8 BMS
 SG_ P2_CellTemp141 : 7|11@0+ (0.1,-40) [-40|150] "C" VCU
 SG_ P2_CellTemp142 : 12|11@0+ (0.1,-40) [-40|150] "C" VCU
 SG_ P2_CellTemp143 : 17|11@0+ (0.1,-40) [-40|150] "C" VCU
 SG_ P2_CellTemp144 : 38|11@0+ (0.1,-40) [-40|150] "C" VCU
 SG_ P2_CellTemp145 : 43|11@0+ (0.1,-40) [-40|150] "C" VCU

BO_ 2560426018 BatP2_BMS_CellTempM29: 8 BMS
 SG_ P2_CellTemp146 : 7|11@0+ (0.1,-40) [-40|150] "C" VCU
 SG_ P2_CellTemp147 : 12|11@0+ (0.1,-40) [-40|150] "C" VCU
 SG_ P2_CellTemp148 : 17|11@0+ (0.1,-40) [-40|150] "C" VCU
 SG_ P2_CellTemp149 : 38|11@0+ (0.1,-40) [-40|150] "C" VCU
 SG_ P2_CellTemp150 : 43|11@0+ (0.1,-40) [-40|150] "C" VCU

BO_ 2560491554 BatP2_BMS_CellTempM30: 8 BMS
 SG_ P2_CellTemp151 : 7|11@0+ (0.1,-40) [-40|150] "C" VCU
 SG_ P2_CellTemp152 : 12|11@0+ (0.1,-40) [-40|150] "C" VCU
 SG_ P2_CellTemp153 : 17|11@0+ (0.1,-40) [-40|150] "C" VCU
 SG_ P2_CellTemp154 : 38|11@0+ (0.1,-40) [-40|150] "C" VCU
 SG_ P2_CellTemp155 : 43|11@0+ (0.1,-40) [-40|150] "C" VCU

BO_ 2560557090 BatP2_BMS_CellTempM31: 8 BMS
 SG_ P2_CellTemp156 : 7|11@0+ (0.1,-40) [-40|150] "C" VCU
 SG_ P2_CellTemp157 : 12|11@0+ (0.1,-40) [-40|150] "C" VCU
 SG_ P2_CellTemp158 : 17|11@0+ (0.1,-40) [-40|150] "C" VCU
 SG_ P2_CellTemp159 : 38|11@0+ (0.1,-40) [-40|150] "C" VCU
 SG_ P2_CellTemp160 : 43|11@0+ (0.1,-40) [-40|150] "C" VCU

BO_ 2560622626 BatP2_BMS_CellTempM32: 8 BMS
 SG_ P2_CellTemp161 : 7|11@0+ (0.1,-40) [-40|150] "C" VCU
 SG_ P2_CellTemp162 : 12|11@0+ (0.1,-40) [-40|150] "C" VCU
 SG_ P2_CellTemp163 : 17|11@0+ (0.1,-40) [-40|150] "C" VCU
 SG_ P2_CellTemp164 : 38|11@0+ (0.1,-40) [-40|150] "C" VCU
 SG_ P2_CellTemp165 : 43|11@0+ (0.1,-40) [-40|150] "C" VCU

BO_ 2560688162 BatP2_BMS_CellTempM33: 8 BMS
 SG_ P2_CellTemp166 : 7|11@0+ (0.1,-40) [-40|150] "C" VCU
 SG_ P2_CellTemp167 : 12|11@0+ (0.1,-40) [-40|150] "C" VCU
 SG_ P2_CellTemp168 : 17|11@0+ (0.1,-40) [-40|150] "C" VCU
 SG_ P2_CellTemp169 : 38|11@0+ (0.1,-40) [-40|150] "C" VCU
 SG_ P2_CellTemp170 : 43|11@0+ (0.1,-40) [-40|150] "C" VCU

BO_ 2560753698 BatP2_BMS_CellTempM34: 8 BMS
 SG_ P2_CellTemp171 : 7|11@0+ (0.1,-40) [-40|150] "C" VCU
 SG_ P2_CellTemp172 : 12|11@0+ (0.1,-40) [-40|150] "C" VCU
 SG_ P2_CellTemp173 : 17|11@0+ (0.1,-40) [-40|150] "C" VCU
 SG_ P2_CellTemp174 : 38|11@0+ (0.1,-40) [-40|150] "C" VCU
 SG_ P2_CellTemp175 : 43|11@0+ (0.1,-40) [-40|150] "C" VCU

BO_ 2560819234 BatP2_BMS_CellTempM35: 8 BMS
 SG_ P2_CellTemp176 : 7|11@0+ (0.1,-40) [-40|150] "C" VCU
 SG_ P2_CellTemp177 : 12|11@0+ (0.1,-40) [-40|150] "C" VCU
 SG_ P2_CellTemp178 : 17|11@0+ (0.1,-40) [-40|150] "C" VCU
 SG_ P2_CellTemp179 : 38|11@0+ (0.1,-40) [-40|150] "C" VCU
 SG_ P2_CellTemp180 : 43|11@0+ (0.1,-40) [-40|150] "C" VCU

BO_ 2560884770 BatP2_BMS_CellTempM36: 8 BMS
 SG_ P2_CellTemp181 : 7|11@0+ (0.1,-40) [-40|150] "C" VCU
 SG_ P2_CellTemp182 : 12|11@0+ (0.1,-40) [-40|150] "C" VCU
 SG_ P2_CellTemp183 : 17|11@0+ (0.1,-40) [-40|150] "C" VCU
 SG_ P2_CellTemp184 : 38|11@0+ (0.1,-40) [-40|150] "C" VCU
 SG_ P2_CellTemp185 : 43|11@0+ (0.1,-40) [-40|150] "C" VCU

BO_ 2560950306 BatP2_BMS_CellTempM37: 8 BMS
 SG_ P2_CellTemp186 : 7|11@0+ (0.1,-40) [-40|150] "C" VCU
 SG_ P2_CellTemp187 : 12|11@0+ (0.1,-40) [-40|150] "C" VCU
 SG_ P2_CellTemp188 : 17|11@0+ (0.1,-40) [-40|150] "C" VCU
 SG_ P2_CellTemp189 : 38|11@0+ (0.1,-40) [-40|150] "C" VCU
 SG_ P2_CellTemp190 : 43|11@0+ (0.1,-40) [-40|150] "C" VCU

BO_ 2561015842 BatP2_BMS_CellTempM38: 8 BMS
 SG_ P2_CellTemp191 : 7|11@0+ (0.1,-40) [-40|150] "C" VCU
 SG_ P2_CellTemp192 : 12|11@0+ (0.1,-40) [-40|150] "C" VCU
 SG_ P2_DatLen16DbgInfo1 : 7|16@0+ (1,0) [0|65535] "" VCU
 SG_ P2_DatLen16DbgInfo2 : 23|16@0+ (1,0) [0|65535] "" VCU
 SG_ P2_DatLen16DbgInfo3 : 39|16@0+ (1,0) [0|65535] "" VCU
 SG_ P2_DatLen16DbgInfo4 : 55|16@0+ (1,0) [0|65535] "" VCU

BO_ 2550399027 BatP3_BMS_PowerSupplyInfo: 8 BMS
 SG_ P3_BMSPwrSuplVlt1 : 7|9@0+ (0.1,0) [0|50] "V" VCU
 SG_ P3_BMSPwrSuplVlt2 : 14|9@0+ (0.1,0) [0|50] "V" VCU
 SG_ P3_ChrgStationAuxPwrSuplVlt : 21|9@0+ (0.1,0) [0|50] "V" VCU
 SG_ P3_BMSKL15ON : 28|1@0+ (1,0) [0|1] "" VCU
 SG_ P3_DCStepState : 27|8@0+ (1,0) [0|255] "" VCU
 SG_ P3_ExtLvWakeup_28VOnly : 35|9@0+ (0.1,0) [0|50] "V" VCU

CM_ SG_ 2550398993 P1_BMSPwrSuplVlt1 "电池包1的BMS供电电源电压1";
CM_ SG_ 2550398993 P1_BMSPwrSuplVlt2 "电池包1的BMS供电电源电压2";
CM_ SG_ 2550398993 P1_ChrgStationAuxPwrSuplVlt "电池包1的快充桩A+电压";
CM_ SG_ 2550398993 P1_BMSKL15ON "电池包1的BMS唤醒信号";
CM_ SG_ 2550398993 P1_DCStepState "电池包1的充电状态机";
CM_ SG_ 2550398993 P1_ExtLvWakeup_28VOnly "电池包1的外部唤醒";
CM_ SG_ 2550464529 P1_PackVltUprLmt "电池包1的电压使用上限";
CM_ SG_ 2550464529 P1_PackVltLoLmt "电池包1的电压使用下限";
CM_ SG_ 2550464529 P1_PackMaxDschrgCrnt "电池包1的最大允许放电电流";
CM_ SG_ 2550464529 P1_PackMaxChrgCrnt "电池包1的最大允许充电电流";
CM_ SG_ 2550530065 P1_PackDschrgPwrLmt "电池包1的放电功率限值";
CM_ SG_ 2550530065 P1_PackDschrgPwrStat "电池包1的放电功率状态";
CM_ SG_ 2550530065 P1_PackChrgPwrLmt "电池包1的充电功率限值";
CM_ SG_ 2550530065 P1_PackChrgPwrStat "电池包1的充电功率状态";
CM_ SG_ 2550595601 P1_ChrgrCplrStat "电池包1的充电枪连接状态";
CM_ SG_ 2550595601 P1_HVBattChrgSysStatus "电池包1的充电系统状态";
CM_ SG_ 2550595601 P1_DCChrgCrntCmd "电池包1的直流充电请求电流";
CM_ SG_ 2550595601 P1_CC2Vlt "电池包1的CC2电压值";
CM_ SG_ 2550595601 P1_DCRcptPosTemp "电池包1的快充充电插座正极温度";
CM_ SG_ 2550595601 P1_DCRcptNegTemp "电池包1的快充充电插座负极温度";
CM_ SG_ 2550595601 P1_Tm2FullChrg "电池包1满充剩余时间";
CM_ SG_ 2550661137 P1_Inlet1ClntTemp "进水口1冷却液温度";
CM_ SG_ 2550661137 P1_Inlet2ClntTemp "进水口2冷却液温度";
CM_ SG_ 2550661137 P1_Outlet1ClntTemp "出水口1冷却液温度";
CM_ SG_ 2550661137 P1_Outlet2ClntTemp "出水口2冷却液温度";
CM_ SG_ 2550661137 P1_TrgtClntTemp "冷却水目标温度";
CM_ SG_ 2550661137 P1_TrgtClntFlowRate "冷却水目标流量";
CM_ SG_ 2550726673 P1_MaxCellVlt "电池包1的最大单体电压";
CM_ SG_ 2550726673 P1_MaxCellVltNum "电池包1的最大单体电压编号";
CM_ SG_ 2550726673 P1_MinCellVlt "电池包1的最小单体电压";
CM_ SG_ 2550726673 P1_MinCellVltNum "电池包1的最小单体电压编号";
CM_ SG_ 2550726673 P1_AvgCellVlt "电池包1的平均单体电压";
CM_ SG_ 2550792209 P1_MaxCellTemp "电池包1的最高单体温度";
CM_ SG_ 2550792209 P1_MaxCellTempNum "电池包1的最高单体温度编号";
CM_ SG_ 2550792209 P1_MinCellTemp "电池包1的最低单体温度";
CM_ SG_ 2550792209 P1_MinCellTempNum "电池包1的最低单体温度编号";
CM_ SG_ 2550792209 P1_AvgCellTemp "电池包1的单体平均温度";
CM_ SG_ 2550857745 P1_PackTotFltNum "电池包1的电池故障总数";
CM_ SG_ 2550857745 P1_CellOverVoltage "电池包1的单体过压";
CM_ SG_ 2550857745 P1_CellUnderVoltage "电池包1的单体欠压";
CM_ SG_ 2550857745 P1_CellVoltageDiffHi "电池包1的单体压差过大";
CM_ SG_ 2550857745 P1_PackOverVoltage "电池包1的电压过高";
CM_ SG_ 2550857745 P1_PackUnderVoltage "电池包1的电压过低";
CM_ SG_ 2550857745 P1_CellOverTemp "电池包1的单体过温";
CM_ SG_ 2550857745 P1_CellTempLow "电池包1的单体温度过低";
CM_ SG_ 2550857745 P1_CellTempDiffHi "电池包1的单体温度差异过大";
CM_ SG_ 2550857745 P1_PackDschrgCrntHi "电池包1的放电电流过流";
CM_ SG_ 2550857745 P1_PackChrgCrntHi "电池包1的充电电流过流";
CM_ SG_ 2550857745 P1_PackCrnSnsr1OffsetHi "电池包1的电流传感器1零漂过大";
CM_ SG_ 2550857745 P1_HVIsolFlt "电池包1的高压绝缘故障";
CM_ SG_ 2550857745 P1_HVILFlt "电池包1的高压互锁故障";
CM_ SG_ 2550857745 P1_ThrmlRunaway "电池包1的热失控故障";
CM_ SG_ 2550857745 P1_CellVoltInvalid "电池包1的单体电压采样失效";
CM_ SG_ 2550857745 P1_CellTempInvalid "电池包1的电芯温度采样失效";
CM_ SG_ 2550857745 P1_DaisyChainComFlt "电池包1的菊花链通信故障";
CM_ SG_ 2550857745 P1_PackVoltRatFlt "电池包1的总电压与单体电压总和偏差过大";
CM_ SG_ 2550857745 P1_CrntSnsr1Invalid "电池包1的电流传感器1电流采样失效";
CM_ SG_ 2550857745 P1_CrntSnsr1OOR "电池包1的电流传感器1电流超出采样范围";
CM_ SG_ 2550857745 P1_CrntSnsr2Invalid "电池包1的电流传感器2电流采样失效";
CM_ SG_ 2550857745 P1_CrntSnsr2OOR "电池包1的电流传感器2电流超出采样范围";
CM_ SG_ 2550857745 P1_PackCrnSnsr2OffsetHi "电池包1的电流传感器2零漂过大";
CM_ SG_ 2550857745 P1_OutofEnergy "电池包1的电池剩余电量低";
CM_ SG_ 2550857745 P1_IsolDetCircErr "电池包1的绝缘检测电路失效";
CM_ SG_ 2550857745 P1_HVILCircShortToGND "电池包1的高压互锁对地短路";
CM_ SG_ 2550857745 P1_HVILCircShortToPwr "电池包1的高压互锁对电源短路";
CM_ SG_ 2550923281 P1_MainPosCntctrStkClsd "电池包1的主正继电器粘连故障";
CM_ SG_ 2550923281 P1_MainPosCntctrStkOpn "电池包1的主正继电器常开故障";
CM_ SG_ 2550923281 P1_MainNegCntctr1StkClsd "电池包1的主负继电器1粘连故障";
CM_ SG_ 2550923281 P1_MainNegCntctr1StkOpn "电池包1的主负继电器1常开故障";
CM_ SG_ 2550923281 P1_MainNegCntctr2StkClsd "电池包1的主负继电器2粘连故障";
CM_ SG_ 2550923281 P1_MainNegCntctr2StkOpn "电池包1的主负继电器2常开故障";
CM_ SG_ 2550923281 P1_PrechargTmOut "电池包1的预充超时故障";
CM_ SG_ 2550923281 P1_PrechrgCrntHi "电池包1的预充过流故障";
CM_ SG_ 2550923281 P1_ChrgCplrPosTempHi "电池包1的充电正极接口温度过高故障";
CM_ SG_ 2550923281 P1_ChrgCplrNegTempHi "电池包1的充电负极接口温度过高故障";
CM_ SG_ 2550923281 P1_BMSPwrSuplVlt1Hi "电池包1的BMS供电电压1过高";
CM_ SG_ 2550923281 P1_BMSPwrSuplVlt1Lo "电池包1的BMS供电电压1过低";
CM_ SG_ 2550923281 P1_BMSPwrSuplVlt2Hi "电池包1的BMS供电电压2过高";
CM_ SG_ 2550923281 P1_BMSPwrSuplVlt2Lo "电池包1的BMS供电电压2过低";
CM_ SG_ 2550923281 P1_CntctrCirPwrSuplVltLo "电池包1的继电器驱动供电电压过低";
CM_ SG_ 2550923281 P1_CntctrCirPwrSuplVltHi "电池包1的继电器驱动供电电压过高";
CM_ SG_ 2550923281 P1_CAN1BusOff "电池包1的CAN1通信Bus off";
CM_ SG_ 2550923281 P1_CAN1BusTmOut "电池包1的CAN1报文超时（Timeout）";
CM_ SG_ 2550923281 P1_CAN2BusOff "电池包1的CAN2通信Bus off";
CM_ SG_ 2550923281 P1_CAN2BusTmOut "电池包1的CAN2报文超时（Timeout）";
CM_ SG_ 2550923281 P1_CellBalCircTempHi "电池包1的均衡电路过温";
CM_ SG_ 2550923281 P1_ClntInTempHi "电池包1的入水口温度过高";
CM_ SG_ 2550923281 P1_ClntOutTempHi "电池包1的出水口温度过高";
CM_ SG_ 2550923281 P1_CellExtrmUdrVolt "电池包1的单体极限欠压";
CM_ SG_ 2550923281 P1_CellExtrmOvrVolt "电池包1的单体极限过压";
CM_ SG_ 2550923281 P1_Branch1DischrgCrntHi  "电池包1的支路1放电过流";
CM_ SG_ 2550923281 P1_Branch2DischrgCrntHi  "电池包1的支路2放电过流";
CM_ SG_ 2550923281 P1_Branch1ChrgCrntHi  "电池包1的支路1充电过流";
CM_ SG_ 2550923281 P1_Branch2ChrgCrntHi  "电池包1的支路2充电过流";
CM_ SG_ 2550923281 P1_InitFailed "电池包1的BMS初始化失败";
CM_ SG_ 2550923281 P1_PackErrCode "电池包1的故障代码";
CM_ SG_ 2550988817 P1_PackTotCellNum "电池包1的单体电池总数";
CM_ SG_ 2550988817 P1_PackTotCellTempSnsrNum "电池包1的单体温度传感器总数";
CM_ SG_ 2552299537 P1_BMSASWMajVerNum "电池包1的BMS应用层软件主版本号";
CM_ SG_ 2552299537 P1_BMSASWMinVerNum "电池包1的BMS应用层软件子版本号";
CM_ SG_ 2552299537 P1_BMSASWPatchVerNum "电池包1的BMS应用层软件修订版本号";
CM_ SG_ 2552299537 P1_BMSBSWMajVerNum "电池包1的BMS底层软件主版本号";
CM_ SG_ 2552299537 P1_BMSBSWMinVerNum "电池包1的BMS底层软件子版本号";
CM_ SG_ 2552299537 P1_BMSBSWPatchVerNum "电池包1的BMS底层软件修订版本号";
CM_ SG_ 2554396689 P1_CellVoltage1 "电池包1的单体电压1";
CM_ SG_ 2554396689 P1_CellVoltage2 "电池包1的单体电压2";
CM_ SG_ 2554396689 P1_CellVoltage3 "电池包1的单体电压3";
CM_ SG_ 2554396689 P1_CellVoltage4 "电池包1的单体电压4";
CM_ SG_ 2554396689 P1_BalSwCell1 "电池包1的电芯1均衡状态";
CM_ SG_ 2554396689 P1_BalSwCell2 "电池包1的电芯2均衡状态";
CM_ SG_ 2554396689 P1_BalSwCell3 "电池包1的电芯3均衡状态";
CM_ SG_ 2554396689 P1_BalSwCell4 "电池包1的电芯4均衡状态";
CM_ SG_ 2554462225 P1_CellVoltage5 "电池包1的单体电压5";
CM_ SG_ 2554462225 P1_CellVoltage6 "电池包1的单体电压6";
CM_ SG_ 2554462225 P1_CellVoltage7 "电池包1的单体电压7";
CM_ SG_ 2554462225 P1_CellVoltage8 "电池包1的单体电压8";
CM_ SG_ 2554462225 P1_BalSwCell5 "电池包1的电芯5均衡状态";
CM_ SG_ 2554462225 P1_BalSwCell6 "电池包1的电芯6均衡状态";
CM_ SG_ 2554462225 P1_BalSwCell7 "电池包1的电芯7均衡状态";
CM_ SG_ 2554462225 P1_BalSwCell8 "电池包1的电芯8均衡状态";
CM_ SG_ 2554527761 P1_CellVoltage9 "电池包1的单体电压9";
CM_ SG_ 2554527761 P1_CellVoltage10 "电池包1的单体电压10";
CM_ SG_ 2554527761 P1_CellVoltage11 "电池包1的单体电压11";
CM_ SG_ 2554527761 P1_CellVoltage12 "电池包1的单体电压12";
CM_ SG_ 2554527761 P1_BalSwCell9 "电池包1的电芯9均衡状态";
CM_ SG_ 2554527761 P1_BalSwCell10 "电池包1的电芯10均衡状态";
CM_ SG_ 2554527761 P1_BalSwCell11 "电池包1的电芯11均衡状态";
CM_ SG_ 2554527761 P1_BalSwCell12 "电池包1的电芯12均衡状态";
CM_ SG_ 2554593297 P1_CellVoltage13 "电池包1的单体电压13";
CM_ SG_ 2554593297 P1_CellVoltage14 "电池包1的单体电压14";
CM_ SG_ 2554593297 P1_CellVoltage15 "电池包1的单体电压15";
CM_ SG_ 2554593297 P1_CellVoltage16 "电池包1的单体电压16";
CM_ SG_ 2554593297 P1_BalSwCell13 "电池包1的电芯13均衡状态";
CM_ SG_ 2554593297 P1_BalSwCell14 "电池包1的电芯14均衡状态";
CM_ SG_ 2554593297 P1_BalSwCell15 "电池包1的电芯15均衡状态";
CM_ SG_ 2554593297 P1_BalSwCell16 "电池包1的电芯16均衡状态";
CM_ SG_ 2554658833 P1_CellVoltage17 "电池包1的单体电压17";
CM_ SG_ 2554658833 P1_CellVoltage18 "电池包1的单体电压18";
CM_ SG_ 2554658833 P1_CellVoltage19 "电池包1的单体电压19";
CM_ SG_ 2554658833 P1_CellVoltage20 "电池包1的单体电压20";
CM_ SG_ 2554658833 P1_BalSwCell17 "电池包1的电芯17均衡状态";
CM_ SG_ 2554658833 P1_BalSwCell18 "电池包1的电芯18均衡状态";
CM_ SG_ 2554658833 P1_BalSwCell19 "电池包1的电芯19均衡状态";
CM_ SG_ 2554658833 P1_BalSwCell20 "电池包1的电芯20均衡状态";
CM_ SG_ 2554724369 P1_CellVoltage21 "电池包1的单体电压21";
CM_ SG_ 2554724369 P1_CellVoltage22 "电池包1的单体电压22";
CM_ SG_ 2554724369 P1_CellVoltage23 "电池包1的单体电压23";
CM_ SG_ 2554724369 P1_CellVoltage24 "电池包1的单体电压24";
CM_ SG_ 2554724369 P1_BalSwCell21 "电池包1的电芯21均衡状态";
CM_ SG_ 2554724369 P1_BalSwCell22 "电池包1的电芯22均衡状态";
CM_ SG_ 2554724369 P1_BalSwCell23 "电池包1的电芯23均衡状态";
CM_ SG_ 2554724369 P1_BalSwCell24 "电池包1的电芯24均衡状态";
CM_ SG_ 2554789905 P1_CellVoltage25 "电池包1的单体电压25";
CM_ SG_ 2554789905 P1_CellVoltage26 "电池包1的单体电压26";
CM_ SG_ 2554789905 P1_CellVoltage27 "电池包1的单体电压27";
CM_ SG_ 2554789905 P1_CellVoltage28 "电池包1的单体电压28";
CM_ SG_ 2554789905 P1_BalSwCell25 "电池包1的电芯25均衡状态";
CM_ SG_ 2554789905 P1_BalSwCell26 "电池包1的电芯26均衡状态";
CM_ SG_ 2554789905 P1_BalSwCell27 "电池包1的电芯27均衡状态";
CM_ SG_ 2554789905 P1_BalSwCell28 "电池包1的电芯28均衡状态";
CM_ SG_ 2554855441 P1_CellVoltage29 "电池包1的单体电压29";
CM_ SG_ 2554855441 P1_CellVoltage30 "电池包1的单体电压30";
CM_ SG_ 2554855441 P1_CellVoltage31 "电池包1的单体电压31";
CM_ SG_ 2554855441 P1_CellVoltage32 "电池包1的单体电压32";
CM_ SG_ 2554855441 P1_BalSwCell29 "电池包1的电芯29均衡状态";
CM_ SG_ 2554855441 P1_BalSwCell30 "电池包1的电芯30均衡状态";
CM_ SG_ 2554855441 P1_BalSwCell31 "电池包1的电芯31均衡状态";
CM_ SG_ 2554855441 P1_BalSwCell32 "电池包1的电芯32均衡状态";
CM_ SG_ 2554920977 P1_CellVoltage33 "电池包1的单体电压33";
CM_ SG_ 2554920977 P1_CellVoltage34 "电池包1的单体电压34";
CM_ SG_ 2554920977 P1_CellVoltage35 "电池包1的单体电压35";
CM_ SG_ 2554920977 P1_CellVoltage36 "电池包1的单体电压36";
CM_ SG_ 2554920977 P1_BalSwCell33 "电池包1的电芯33均衡状态";
CM_ SG_ 2554920977 P1_BalSwCell34 "电池包1的电芯34均衡状态";
CM_ SG_ 2554920977 P1_BalSwCell35 "电池包1的电芯35均衡状态";
CM_ SG_ 2554920977 P1_BalSwCell36 "电池包1的电芯36均衡状态";
CM_ SG_ 2554986513 P1_CellVoltage37 "电池包1的单体电压37";
CM_ SG_ 2554986513 P1_CellVoltage38 "电池包1的单体电压38";
CM_ SG_ 2554986513 P1_CellVoltage39 "电池包1的单体电压39";
CM_ SG_ 2554986513 P1_CellVoltage40 "电池包1的单体电压40";
CM_ SG_ 2554986513 P1_BalSwCell37 "电池包1的电芯37均衡状态";
CM_ SG_ 2554986513 P1_BalSwCell38 "电池包1的电芯38均衡状态";
CM_ SG_ 2554986513 P1_BalSwCell39 "电池包1的电芯39均衡状态";
CM_ SG_ 2554986513 P1_BalSwCell40 "电池包1的电芯40均衡状态";
CM_ SG_ 2555052049 P1_CellVoltage41 "电池包1的单体电压41";
CM_ SG_ 2555052049 P1_CellVoltage42 "电池包1的单体电压42";
CM_ SG_ 2555052049 P1_CellVoltage43 "电池包1的单体电压43";
CM_ SG_ 2555052049 P1_CellVoltage44 "电池包1的单体电压44";
CM_ SG_ 2555052049 P1_BalSwCell41 "电池包1的电芯41均衡状态";
CM_ SG_ 2555052049 P1_BalSwCell42 "电池包1的电芯42均衡状态";
CM_ SG_ 2555052049 P1_BalSwCell43 "电池包1的电芯43均衡状态";
CM_ SG_ 2555052049 P1_BalSwCell44 "电池包1的电芯44均衡状态";
CM_ SG_ 2555117585 P1_CellVoltage45 "电池包1的单体电压45";
CM_ SG_ 2555117585 P1_CellVoltage46 "电池包1的单体电压46";
CM_ SG_ 2555117585 P1_CellVoltage47 "电池包1的单体电压47";
CM_ SG_ 2555117585 P1_CellVoltage48 "电池包1的单体电压48";
CM_ SG_ 2555117585 P1_BalSwCell45 "电池包1的电芯45均衡状态";
CM_ SG_ 2555117585 P1_BalSwCell46 "电池包1的电芯46均衡状态";
CM_ SG_ 2555117585 P1_BalSwCell47 "电池包1的电芯47均衡状态";
CM_ SG_ 2555117585 P1_BalSwCell48 "电池包1的电芯48均衡状态";
CM_ SG_ 2555183121 P1_CellVoltage49 "电池包1的单体电压49";
CM_ SG_ 2555183121 P1_CellVoltage50 "电池包1的单体电压50";
CM_ SG_ 2555183121 P1_CellVoltage51 "电池包1的单体电压51";
CM_ SG_ 2555183121 P1_CellVoltage52 "电池包1的单体电压52";
CM_ SG_ 2555183121 P1_BalSwCell49 "电池包1的电芯49均衡状态";
CM_ SG_ 2555183121 P1_BalSwCell50 "电池包1的电芯50均衡状态";
CM_ SG_ 2555183121 P1_BalSwCell51 "电池包1的电芯51均衡状态";
CM_ SG_ 2555183121 P1_BalSwCell52 "电池包1的电芯52均衡状态";
CM_ SG_ 2555248657 P1_CellVoltage53 "电池包1的单体电压53";
CM_ SG_ 2555248657 P1_CellVoltage54 "电池包1的单体电压54";
CM_ SG_ 2555248657 P1_CellVoltage55 "电池包1的单体电压55";
CM_ SG_ 2555248657 P1_CellVoltage56 "电池包1的单体电压56";
CM_ SG_ 2555248657 P1_BalSwCell53 "电池包1的电芯53均衡状态";
CM_ SG_ 2555248657 P1_BalSwCell54 "电池包1的电芯54均衡状态";
CM_ SG_ 2555248657 P1_BalSwCell55 "电池包1的电芯55均衡状态";
CM_ SG_ 2555248657 P1_BalSwCell56 "电池包1的电芯56均衡状态";
CM_ SG_ 2555314193 P1_CellVoltage57 "电池包1的单体电压57";
CM_ SG_ 2555314193 P1_CellVoltage58 "电池包1的单体电压58";
CM_ SG_ 2555314193 P1_CellVoltage59 "电池包1的单体电压59";
CM_ SG_ 2555314193 P1_CellVoltage60 "电池包1的单体电压60";
CM_ SG_ 2555314193 P1_BalSwCell57 "电池包1的电芯57均衡状态";
CM_ SG_ 2555314193 P1_BalSwCell58 "电池包1的电芯58均衡状态";
CM_ SG_ 2555314193 P1_BalSwCell59 "电池包1的电芯59均衡状态";
CM_ SG_ 2555314193 P1_BalSwCell60 "电池包1的电芯60均衡状态";
CM_ SG_ 2555379729 P1_CellVoltage61 "电池包1的单体电压61";
CM_ SG_ 2555379729 P1_CellVoltage62 "电池包1的单体电压62";
CM_ SG_ 2555379729 P1_CellVoltage63 "电池包1的单体电压63";
CM_ SG_ 2555379729 P1_CellVoltage64 "电池包1的单体电压64";
CM_ SG_ 2555379729 P1_BalSwCell61 "电池包1的电芯61均衡状态";
CM_ SG_ 2555379729 P1_BalSwCell62 "电池包1的电芯62均衡状态";
CM_ SG_ 2555379729 P1_BalSwCell63 "电池包1的电芯63均衡状态";
CM_ SG_ 2555379729 P1_BalSwCell64 "电池包1的电芯64均衡状态";
CM_ SG_ 2555445265 P1_CellVoltage65 "电池包1的单体电压65";
CM_ SG_ 2555445265 P1_CellVoltage66 "电池包1的单体电压66";
CM_ SG_ 2555445265 P1_CellVoltage67 "电池包1的单体电压67";
CM_ SG_ 2555445265 P1_CellVoltage68 "电池包1的单体电压68";
CM_ SG_ 2555445265 P1_BalSwCell65 "电池包1的电芯65均衡状态";
CM_ SG_ 2555445265 P1_BalSwCell66 "电池包1的电芯66均衡状态";
CM_ SG_ 2555445265 P1_BalSwCell67 "电池包1的电芯67均衡状态";
CM_ SG_ 2555445265 P1_BalSwCell68 "电池包1的电芯68均衡状态";
CM_ SG_ 2555510801 P1_CellVoltage69 "电池包1的单体电压69";
CM_ SG_ 2555510801 P1_CellVoltage70 "电池包1的单体电压70";
CM_ SG_ 2555510801 P1_CellVoltage71 "电池包1的单体电压71";
CM_ SG_ 2555510801 P1_CellVoltage72 "电池包1的单体电压72";
CM_ SG_ 2555510801 P1_BalSwCell69 "电池包1的电芯69均衡状态";
CM_ SG_ 2555510801 P1_BalSwCell70 "电池包1的电芯70均衡状态";
CM_ SG_ 2555510801 P1_BalSwCell71 "电池包1的电芯71均衡状态";
CM_ SG_ 2555510801 P1_BalSwCell72 "电池包1的电芯72均衡状态";
CM_ SG_ 2555576337 P1_CellVoltage73 "电池包1的单体电压73";
CM_ SG_ 2555576337 P1_CellVoltage74 "电池包1的单体电压74";
CM_ SG_ 2555576337 P1_CellVoltage75 "电池包1的单体电压75";
CM_ SG_ 2555576337 P1_CellVoltage76 "电池包1的单体电压76";
CM_ SG_ 2555576337 P1_BalSwCell73 "电池包1的电芯73均衡状态";
CM_ SG_ 2555576337 P1_BalSwCell74 "电池包1的电芯74均衡状态";
CM_ SG_ 2555576337 P1_BalSwCell75 "电池包1的电芯75均衡状态";
CM_ SG_ 2555576337 P1_BalSwCell76 "电池包1的电芯76均衡状态";
CM_ SG_ 2555641873 P1_CellVoltage77 "电池包1的单体电压77";
CM_ SG_ 2555641873 P1_CellVoltage78 "电池包1的单体电压78";
CM_ SG_ 2555641873 P1_CellVoltage79 "电池包1的单体电压79";
CM_ SG_ 2555641873 P1_CellVoltage80 "电池包1的单体电压80";
CM_ SG_ 2555641873 P1_BalSwCell77 "电池包1的电芯77均衡状态";
CM_ SG_ 2555641873 P1_BalSwCell78 "电池包1的电芯78均衡状态";
CM_ SG_ 2555641873 P1_BalSwCell79 "电池包1的电芯79均衡状态";
CM_ SG_ 2555641873 P1_BalSwCell80 "电池包1的电芯80均衡状态";
CM_ SG_ 2555707409 P1_CellVoltage81 "电池包1的单体电压81";
CM_ SG_ 2555707409 P1_CellVoltage82 "电池包1的单体电压82";
CM_ SG_ 2555707409 P1_CellVoltage83 "电池包1的单体电压83";
CM_ SG_ 2555707409 P1_CellVoltage84 "电池包1的单体电压84";
CM_ SG_ 2555707409 P1_BalSwCell81 "电池包1的电芯81均衡状态";
CM_ SG_ 2555707409 P1_BalSwCell82 "电池包1的电芯82均衡状态";
CM_ SG_ 2555707409 P1_BalSwCell83 "电池包1的电芯83均衡状态";
CM_ SG_ 2555707409 P1_BalSwCell84 "电池包1的电芯84均衡状态";
CM_ SG_ 2555772945 P1_CellVoltage85 "电池包1的单体电压85";
CM_ SG_ 2555772945 P1_CellVoltage86 "电池包1的单体电压86";
CM_ SG_ 2555772945 P1_CellVoltage87 "电池包1的单体电压87";
CM_ SG_ 2555772945 P1_CellVoltage88 "电池包1的单体电压88";
CM_ SG_ 2555772945 P1_BalSwCell85 "电池包1的电芯85均衡状态";
CM_ SG_ 2555772945 P1_BalSwCell86 "电池包1的电芯86均衡状态";
CM_ SG_ 2555772945 P1_BalSwCell87 "电池包1的电芯87均衡状态";
CM_ SG_ 2555772945 P1_BalSwCell88 "电池包1的电芯88均衡状态";
CM_ SG_ 2555838481 P1_CellVoltage89 "电池包1的单体电压89";
CM_ SG_ 2555838481 P1_CellVoltage90 "电池包1的单体电压90";
CM_ SG_ 2555838481 P1_CellVoltage91 "电池包1的单体电压91";
CM_ SG_ 2555838481 P1_CellVoltage92 "电池包1的单体电压92";
CM_ SG_ 2555838481 P1_BalSwCell89 "电池包1的电芯89均衡状态";
CM_ SG_ 2555838481 P1_BalSwCell90 "电池包1的电芯90均衡状态";
CM_ SG_ 2555838481 P1_BalSwCell91 "电池包1的电芯91均衡状态";
CM_ SG_ 2555838481 P1_BalSwCell92 "电池包1的电芯92均衡状态";
CM_ SG_ 2555904017 P1_CellVoltage93 "电池包1的单体电压93";
CM_ SG_ 2555904017 P1_CellVoltage94 "电池包1的单体电压94";
CM_ SG_ 2555904017 P1_CellVoltage95 "电池包1的单体电压95";
CM_ SG_ 2555904017 P1_CellVoltage96 "电池包1的单体电压96";
CM_ SG_ 2555904017 P1_BalSwCell93 "电池包1的电芯93均衡状态";
CM_ SG_ 2555904017 P1_BalSwCell94 "电池包1的电芯94均衡状态";
CM_ SG_ 2555904017 P1_BalSwCell95 "电池包1的电芯95均衡状态";
CM_ SG_ 2555904017 P1_BalSwCell96 "电池包1的电芯96均衡状态";
CM_ SG_ 2555969553 P1_CellVoltage97 "电池包1的单体电压97";
CM_ SG_ 2555969553 P1_CellVoltage98 "电池包1的单体电压98";
CM_ SG_ 2555969553 P1_CellVoltage99 "电池包1的单体电压99";
CM_ SG_ 2555969553 P1_CellVoltage100 "电池包1的单体电压100";
CM_ SG_ 2555969553 P1_BalSwCell97 "电池包1的电芯97均衡状态";
CM_ SG_ 2555969553 P1_BalSwCell98 "电池包1的电芯98均衡状态";
CM_ SG_ 2555969553 P1_BalSwCell99 "电池包1的电芯99均衡状态";
CM_ SG_ 2555969553 P1_BalSwCell100 "电池包1的电芯100均衡状态";
CM_ SG_ 2556035089 P1_CellVoltage101 "电池包1的单体电压101";
CM_ SG_ 2556035089 P1_CellVoltage102 "电池包1的单体电压102";
CM_ SG_ 2556035089 P1_CellVoltage103 "电池包1的单体电压103";
CM_ SG_ 2556035089 P1_CellVoltage104 "电池包1的单体电压104";
CM_ SG_ 2556035089 P1_BalSwCell101 "电池包1的电芯101均衡状态";
CM_ SG_ 2556035089 P1_BalSwCell102 "电池包1的电芯102均衡状态";
CM_ SG_ 2556035089 P1_BalSwCell103 "电池包1的电芯103均衡状态";
CM_ SG_ 2556035089 P1_BalSwCell104 "电池包1的电芯104均衡状态";
CM_ SG_ 2556100625 P1_CellVoltage105 "电池包1的单体电压105";
CM_ SG_ 2556100625 P1_CellVoltage106 "电池包1的单体电压106";
CM_ SG_ 2556100625 P1_CellVoltage107 "电池包1的单体电压107";
CM_ SG_ 2556100625 P1_CellVoltage108 "电池包1的单体电压108";
CM_ SG_ 2556100625 P1_BalSwCell105 "电池包1的电芯105均衡状态";
CM_ SG_ 2556100625 P1_BalSwCell106 "电池包1的电芯106均衡状态";
CM_ SG_ 2556100625 P1_BalSwCell107 "电池包1的电芯107均衡状态";
CM_ SG_ 2556100625 P1_BalSwCell108 "电池包1的电芯108均衡状态";
CM_ SG_ 2556166161 P1_CellVoltage109 "电池包1的单体电压109";
CM_ SG_ 2556166161 P1_CellVoltage110 "电池包1的单体电压110";
CM_ SG_ 2556166161 P1_CellVoltage111 "电池包1的单体电压111";
CM_ SG_ 2556166161 P1_CellVoltage112 "电池包1的单体电压112";
CM_ SG_ 2556166161 P1_BalSwCell109 "电池包1的电芯109均衡状态";
CM_ SG_ 2556166161 P1_BalSwCell110 "电池包1的电芯110均衡状态";
CM_ SG_ 2556166161 P1_BalSwCell111 "电池包1的电芯111均衡状态";
CM_ SG_ 2556166161 P1_BalSwCell112 "电池包1的电芯112均衡状态";
CM_ SG_ 2556231697 P1_CellVoltage113 "电池包1的单体电压113";
CM_ SG_ 2556231697 P1_CellVoltage114 "电池包1的单体电压114";
CM_ SG_ 2556231697 P1_CellVoltage115 "电池包1的单体电压115";
CM_ SG_ 2556231697 P1_CellVoltage116 "电池包1的单体电压116";
CM_ SG_ 2556231697 P1_BalSwCell113 "电池包1的电芯113均衡状态";
CM_ SG_ 2556231697 P1_BalSwCell114 "电池包1的电芯114均衡状态";
CM_ SG_ 2556231697 P1_BalSwCell115 "电池包1的电芯115均衡状态";
CM_ SG_ 2556231697 P1_BalSwCell116 "电池包1的电芯116均衡状态";
CM_ SG_ 2556297233 P1_CellVoltage117 "电池包1的单体电压117";
CM_ SG_ 2556297233 P1_CellVoltage118 "电池包1的单体电压118";
CM_ SG_ 2556297233 P1_CellVoltage119 "电池包1的单体电压119";
CM_ SG_ 2556297233 P1_CellVoltage120 "电池包1的单体电压120";
CM_ SG_ 2556297233 P1_BalSwCell117 "电池包1的电芯117均衡状态";
CM_ SG_ 2556297233 P1_BalSwCell118 "电池包1的电芯118均衡状态";
CM_ SG_ 2556297233 P1_BalSwCell119 "电池包1的电芯119均衡状态";
CM_ SG_ 2556297233 P1_BalSwCell120 "电池包1的电芯120均衡状态";
CM_ SG_ 2556362769 P1_CellVoltage121 "电池包1的单体电压121";
CM_ SG_ 2556362769 P1_CellVoltage122 "电池包1的单体电压122";
CM_ SG_ 2556362769 P1_CellVoltage123 "电池包1的单体电压123";
CM_ SG_ 2556362769 P1_CellVoltage124 "电池包1的单体电压124";
CM_ SG_ 2556362769 P1_BalSwCell121 "电池包1的电芯121均衡状态";
CM_ SG_ 2556362769 P1_BalSwCell122 "电池包1的电芯122均衡状态";
CM_ SG_ 2556362769 P1_BalSwCell123 "电池包1的电芯123均衡状态";
CM_ SG_ 2556362769 P1_BalSwCell124 "电池包1的电芯124均衡状态";
CM_ SG_ 2556428305 P1_CellVoltage125 "电池包1的单体电压125";
CM_ SG_ 2556428305 P1_CellVoltage126 "电池包1的单体电压126";
CM_ SG_ 2556428305 P1_CellVoltage127 "电池包1的单体电压127";
CM_ SG_ 2556428305 P1_CellVoltage128 "电池包1的单体电压128";
CM_ SG_ 2556428305 P1_BalSwCell125 "电池包1的电芯125均衡状态";
CM_ SG_ 2556428305 P1_BalSwCell126 "电池包1的电芯126均衡状态";
CM_ SG_ 2556428305 P1_BalSwCell127 "电池包1的电芯127均衡状态";
CM_ SG_ 2556428305 P1_BalSwCell128 "电池包1的电芯128均衡状态";
CM_ SG_ 2556493841 P1_CellVoltage129 "电池包1的单体电压129";
CM_ SG_ 2556493841 P1_CellVoltage130 "电池包1的单体电压130";
CM_ SG_ 2556493841 P1_CellVoltage131 "电池包1的单体电压131";
CM_ SG_ 2556493841 P1_CellVoltage132 "电池包1的单体电压132";
CM_ SG_ 2556493841 P1_BalSwCell129 "电池包1的电芯129均衡状态";
CM_ SG_ 2556493841 P1_BalSwCell130 "电池包1的电芯130均衡状态";
CM_ SG_ 2556493841 P1_BalSwCell131 "电池包1的电芯131均衡状态";
CM_ SG_ 2556493841 P1_BalSwCell132 "电池包1的电芯132均衡状态";
CM_ SG_ 2556559377 P1_CellVoltage133 "电池包1的单体电压133";
CM_ SG_ 2556559377 P1_CellVoltage134 "电池包1的单体电压134";
CM_ SG_ 2556559377 P1_CellVoltage135 "电池包1的单体电压135";
CM_ SG_ 2556559377 P1_CellVoltage136 "电池包1的单体电压136";
CM_ SG_ 2556559377 P1_BalSwCell133 "电池包1的电芯133均衡状态";
CM_ SG_ 2556559377 P1_BalSwCell134 "电池包1的电芯134均衡状态";
CM_ SG_ 2556559377 P1_BalSwCell135 "电池包1的电芯135均衡状态";
CM_ SG_ 2556559377 P1_BalSwCell136 "电池包1的电芯136均衡状态";
CM_ SG_ 2556624913 P1_CellVoltage137 "电池包1的单体电压137";
CM_ SG_ 2556624913 P1_CellVoltage138 "电池包1的单体电压138";
CM_ SG_ 2556624913 P1_CellVoltage139 "电池包1的单体电压139";
CM_ SG_ 2556624913 P1_CellVoltage140 "电池包1的单体电压140";
CM_ SG_ 2556624913 P1_BalSwCell137 "电池包1的电芯137均衡状态";
CM_ SG_ 2556624913 P1_BalSwCell138 "电池包1的电芯138均衡状态";
CM_ SG_ 2556624913 P1_BalSwCell139 "电池包1的电芯139均衡状态";
CM_ SG_ 2556624913 P1_BalSwCell140 "电池包1的电芯140均衡状态";
CM_ SG_ 2556690449 P1_CellVoltage141 "电池包1的单体电压141";
CM_ SG_ 2556690449 P1_CellVoltage142 "电池包1的单体电压142";
CM_ SG_ 2556690449 P1_CellVoltage143 "电池包1的单体电压143";
CM_ SG_ 2556690449 P1_CellVoltage144 "电池包1的单体电压144";
CM_ SG_ 2556690449 P1_BalSwCell141 "电池包1的电芯141均衡状态";
CM_ SG_ 2556690449 P1_BalSwCell142 "电池包1的电芯142均衡状态";
CM_ SG_ 2556690449 P1_BalSwCell143 "电池包1的电芯143均衡状态";
CM_ SG_ 2556690449 P1_BalSwCell144 "电池包1的电芯144均衡状态";
CM_ SG_ 2556755985 P1_CellVoltage145 "电池包1的单体电压145";
CM_ SG_ 2556755985 P1_CellVoltage146 "电池包1的单体电压146";
CM_ SG_ 2556755985 P1_CellVoltage147 "电池包1的单体电压147";
CM_ SG_ 2556755985 P1_CellVoltage148 "电池包1的单体电压148";
CM_ SG_ 2556755985 P1_BalSwCell145 "电池包1的电芯145均衡状态";
CM_ SG_ 2556755985 P1_BalSwCell146 "电池包1的电芯146均衡状态";
CM_ SG_ 2556755985 P1_BalSwCell147 "电池包1的电芯147均衡状态";
CM_ SG_ 2556755985 P1_BalSwCell148 "电池包1的电芯148均衡状态";
CM_ SG_ 2556821521 P1_CellVoltage149 "电池包1的单体电压149";
CM_ SG_ 2556821521 P1_CellVoltage150 "电池包1的单体电压150";
CM_ SG_ 2556821521 P1_CellVoltage151 "电池包1的单体电压151";
CM_ SG_ 2556821521 P1_CellVoltage152 "电池包1的单体电压152";
CM_ SG_ 2556821521 P1_BalSwCell149 "电池包1的电芯149均衡状态";
CM_ SG_ 2556821521 P1_BalSwCell150 "电池包1的电芯150均衡状态";
CM_ SG_ 2556821521 P1_BalSwCell151 "电池包1的电芯151均衡状态";
CM_ SG_ 2556821521 P1_BalSwCell152 "电池包1的电芯152均衡状态";
CM_ SG_ 2556887057 P1_CellVoltage153 "电池包1的单体电压153";
CM_ SG_ 2556887057 P1_CellVoltage154 "电池包1的单体电压154";
CM_ SG_ 2556887057 P1_CellVoltage155 "电池包1的单体电压155";
CM_ SG_ 2556887057 P1_CellVoltage156 "电池包1的单体电压156";
CM_ SG_ 2556887057 P1_BalSwCell153 "电池包1的电芯153均衡状态";
CM_ SG_ 2556887057 P1_BalSwCell154 "电池包1的电芯154均衡状态";
CM_ SG_ 2556887057 P1_BalSwCell155 "电池包1的电芯155均衡状态";
CM_ SG_ 2556887057 P1_BalSwCell156 "电池包1的电芯156均衡状态";
CM_ SG_ 2556952593 P1_CellVoltage157 "电池包1的单体电压157";
CM_ SG_ 2556952593 P1_CellVoltage158 "电池包1的单体电压158";
CM_ SG_ 2556952593 P1_CellVoltage159 "电池包1的单体电压159";
CM_ SG_ 2556952593 P1_CellVoltage160 "电池包1的单体电压160";
CM_ SG_ 2556952593 P1_BalSwCell157 "电池包1的电芯157均衡状态";
CM_ SG_ 2556952593 P1_BalSwCell158 "电池包1的电芯158均衡状态";
CM_ SG_ 2556952593 P1_BalSwCell159 "电池包1的电芯159均衡状态";
CM_ SG_ 2556952593 P1_BalSwCell160 "电池包1的电芯160均衡状态";
CM_ SG_ 2557018129 P1_CellVoltage161 "电池包1的单体电压161";
CM_ SG_ 2557018129 P1_CellVoltage162 "电池包1的单体电压162";
CM_ SG_ 2557018129 P1_CellVoltage163 "电池包1的单体电压163";
CM_ SG_ 2557018129 P1_CellVoltage164 "电池包1的单体电压164";
CM_ SG_ 2557018129 P1_BalSwCell161 "电池包1的电芯161均衡状态";
CM_ SG_ 2557018129 P1_BalSwCell162 "电池包1的电芯162均衡状态";
CM_ SG_ 2557018129 P1_BalSwCell163 "电池包1的电芯163均衡状态";
CM_ SG_ 2557018129 P1_BalSwCell164 "电池包1的电芯164均衡状态";
CM_ SG_ 2557083665 P1_CellVoltage165 "电池包1的单体电压165";
CM_ SG_ 2557083665 P1_CellVoltage166 "电池包1的单体电压166";
CM_ SG_ 2557083665 P1_CellVoltage167 "电池包1的单体电压167";
CM_ SG_ 2557083665 P1_CellVoltage168 "电池包1的单体电压168";
CM_ SG_ 2557083665 P1_BalSwCell165 "电池包1的电芯165均衡状态";
CM_ SG_ 2557083665 P1_BalSwCell166 "电池包1的电芯166均衡状态";
CM_ SG_ 2557083665 P1_BalSwCell167 "电池包1的电芯167均衡状态";
CM_ SG_ 2557083665 P1_BalSwCell168 "电池包1的电芯168均衡状态";
CM_ SG_ 2557149201 P1_CellVoltage169 "电池包1的单体电压169";
CM_ SG_ 2557149201 P1_CellVoltage170 "电池包1的单体电压170";
CM_ SG_ 2557149201 P1_CellVoltage171 "电池包1的单体电压171";
CM_ SG_ 2557149201 P1_CellVoltage172 "电池包1的单体电压172";
CM_ SG_ 2557149201 P1_BalSwCell169 "电池包1的电芯169均衡状态";
CM_ SG_ 2557149201 P1_BalSwCell170 "电池包1的电芯170均衡状态";
CM_ SG_ 2557149201 P1_BalSwCell171 "电池包1的电芯171均衡状态";
CM_ SG_ 2557149201 P1_BalSwCell172 "电池包1的电芯172均衡状态";
CM_ SG_ 2557214737 P1_CellVoltage173 "电池包1的单体电压173";
CM_ SG_ 2557214737 P1_CellVoltage174 "电池包1的单体电压174";
CM_ SG_ 2557214737 P1_CellVoltage175 "电池包1的单体电压175";
CM_ SG_ 2557214737 P1_CellVoltage176 "电池包1的单体电压176";
CM_ SG_ 2557214737 P1_BalSwCell173 "电池包1的电芯173均衡状态";
CM_ SG_ 2557214737 P1_BalSwCell174 "电池包1的电芯174均衡状态";
CM_ SG_ 2557214737 P1_BalSwCell175 "电池包1的电芯175均衡状态";
CM_ SG_ 2557214737 P1_BalSwCell176 "电池包1的电芯176均衡状态";
CM_ SG_ 2557280273 P1_CellVoltage177 "电池包1的单体电压177";
CM_ SG_ 2557280273 P1_CellVoltage178 "电池包1的单体电压178";
CM_ SG_ 2557280273 P1_CellVoltage179 "电池包1的单体电压179";
CM_ SG_ 2557280273 P1_CellVoltage180 "电池包1的单体电压180";
CM_ SG_ 2557280273 P1_BalSwCell177 "电池包1的电芯177均衡状态";
CM_ SG_ 2557280273 P1_BalSwCell178 "电池包1的电芯178均衡状态";
CM_ SG_ 2557280273 P1_BalSwCell179 "电池包1的电芯179均衡状态";
CM_ SG_ 2557280273 P1_BalSwCell180 "电池包1的电芯180均衡状态";
CM_ SG_ 2557345809 P1_CellVoltage181 "电池包1的单体电压181";
CM_ SG_ 2557345809 P1_CellVoltage182 "电池包1的单体电压182";
CM_ SG_ 2557345809 P1_CellVoltage183 "电池包1的单体电压183";
CM_ SG_ 2557345809 P1_CellVoltage184 "电池包1的单体电压184";
CM_ SG_ 2557345809 P1_BalSwCell181 "电池包1的电芯181均衡状态";
CM_ SG_ 2557345809 P1_BalSwCell182 "电池包1的电芯182均衡状态";
CM_ SG_ 2557345809 P1_BalSwCell183 "电池包1的电芯183均衡状态";
CM_ SG_ 2557345809 P1_BalSwCell184 "电池包1的电芯184均衡状态";
CM_ SG_ 2557411345 P1_CellVoltage185 "电池包1的单体电压185";
CM_ SG_ 2557411345 P1_CellVoltage186 "电池包1的单体电压186";
CM_ SG_ 2557411345 P1_CellVoltage187 "电池包1的单体电压187";
CM_ SG_ 2557411345 P1_CellVoltage188 "电池包1的单体电压188";
CM_ SG_ 2557411345 P1_BalSwCell185 "电池包1的电芯185均衡状态";
CM_ SG_ 2557411345 P1_BalSwCell186 "电池包1的电芯186均衡状态";
CM_ SG_ 2557411345 P1_BalSwCell187 "电池包1的电芯187均衡状态";
CM_ SG_ 2557411345 P1_BalSwCell188 "电池包1的电芯188均衡状态";
CM_ SG_ 2557476881 P1_CellVoltage189 "电池包1的单体电压189";
CM_ SG_ 2557476881 P1_CellVoltage190 "电池包1的单体电压190";
CM_ SG_ 2557476881 P1_CellVoltage191 "电池包1的单体电压191";
CM_ SG_ 2557476881 P1_CellVoltage192 "电池包1的单体电压192";
CM_ SG_ 2557476881 P1_BalSwCell189 "电池包1的电芯189均衡状态";
CM_ SG_ 2557476881 P1_BalSwCell190 "电池包1的电芯190均衡状态";
CM_ SG_ 2557476881 P1_BalSwCell191 "电池包1的电芯191均衡状态";
CM_ SG_ 2557476881 P1_BalSwCell192 "电池包1的电芯192均衡状态";
CM_ SG_ 2558525457 P1_CellTemp1 "电池包1的单体温度1";
CM_ SG_ 2558525457 P1_CellTemp2 "电池包1的单体温度2";
CM_ SG_ 2558525457 P1_CellTemp3 "电池包1的单体温度3";
CM_ SG_ 2558525457 P1_CellTemp4 "电池包1的单体温度4";
CM_ SG_ 2558525457 P1_CellTemp5 "电池包1的单体温度5";
CM_ SG_ 2558590993 P1_CellTemp6 "电池包1的单体温度6";
CM_ SG_ 2558590993 P1_CellTemp7 "电池包1的单体温度7";
CM_ SG_ 2558590993 P1_CellTemp8 "电池包1的单体温度8";
CM_ SG_ 2558590993 P1_CellTemp9 "电池包1的单体温度9";
CM_ SG_ 2558590993 P1_CellTemp10 "电池包1的单体温度10";
CM_ SG_ 2558656529 P1_CellTemp11 "电池包1的单体温度11";
CM_ SG_ 2558656529 P1_CellTemp12 "电池包1的单体温度12";
CM_ SG_ 2558656529 P1_CellTemp13 "电池包1的单体温度13";
CM_ SG_ 2558656529 P1_CellTemp14 "电池包1的单体温度14";
CM_ SG_ 2558656529 P1_CellTemp15 "电池包1的单体温度15";
CM_ SG_ 2558722065 P1_CellTemp16 "电池包1的单体温度16";
CM_ SG_ 2558722065 P1_CellTemp17 "电池包1的单体温度17";
CM_ SG_ 2558722065 P1_CellTemp18 "电池包1的单体温度18";
CM_ SG_ 2558722065 P1_CellTemp19 "电池包1的单体温度19";
CM_ SG_ 2558722065 P1_CellTemp20 "电池包1的单体温度20";
CM_ SG_ 2558787601 P1_CellTemp21 "电池包1的单体温度21";
CM_ SG_ 2558787601 P1_CellTemp22 "电池包1的单体温度22";
CM_ SG_ 2558787601 P1_CellTemp23 "电池包1的单体温度23";
CM_ SG_ 2558787601 P1_CellTemp24 "电池包1的单体温度24";
CM_ SG_ 2558787601 P1_CellTemp25 "电池包1的单体温度25";
CM_ SG_ 2558853137 P1_CellTemp26 "电池包1的单体温度26";
CM_ SG_ 2558853137 P1_CellTemp27 "电池包1的单体温度27";
CM_ SG_ 2558853137 P1_CellTemp28 "电池包1的单体温度28";
CM_ SG_ 2558853137 P1_CellTemp29 "电池包1的单体温度29";
CM_ SG_ 2558853137 P1_CellTemp30 "电池包1的单体温度30";
CM_ SG_ 2558918673 P1_CellTemp31 "电池包1的单体温度31";
CM_ SG_ 2558918673 P1_CellTemp32 "电池包1的单体温度32";
CM_ SG_ 2558918673 P1_CellTemp33 "电池包1的单体温度33";
CM_ SG_ 2558918673 P1_CellTemp34 "电池包1的单体温度34";
CM_ SG_ 2558918673 P1_CellTemp35 "电池包1的单体温度35";
CM_ SG_ 2558984209 P1_CellTemp36 "电池包1的单体温度36";
CM_ SG_ 2558984209 P1_CellTemp37 "电池包1的单体温度37";
CM_ SG_ 2558984209 P1_CellTemp38 "电池包1的单体温度38";
CM_ SG_ 2558984209 P1_CellTemp39 "电池包1的单体温度39";
CM_ SG_ 2558984209 P1_CellTemp40 "电池包1的单体温度40";
CM_ SG_ 2559049745 P1_CellTemp41 "电池包1的单体温度41";
CM_ SG_ 2559049745 P1_CellTemp42 "电池包1的单体温度42";
CM_ SG_ 2559049745 P1_CellTemp43 "电池包1的单体温度43";
CM_ SG_ 2559049745 P1_CellTemp44 "电池包1的单体温度44";
CM_ SG_ 2559049745 P1_CellTemp45 "电池包1的单体温度45";
CM_ SG_ 2559115281 P1_CellTemp46 "电池包1的单体温度46";
CM_ SG_ 2559115281 P1_CellTemp47 "电池包1的单体温度47";
CM_ SG_ 2559115281 P1_CellTemp48 "电池包1的单体温度48";
CM_ SG_ 2559115281 P1_CellTemp49 "电池包1的单体温度49";
CM_ SG_ 2559115281 P1_CellTemp50 "电池包1的单体温度50";
CM_ SG_ 2559180817 P1_CellTemp51 "电池包1的单体温度51";
CM_ SG_ 2559180817 P1_CellTemp52 "电池包1的单体温度52";
CM_ SG_ 2559180817 P1_CellTemp53 "电池包1的单体温度53";
CM_ SG_ 2559180817 P1_CellTemp54 "电池包1的单体温度54";
CM_ SG_ 2559180817 P1_CellTemp55 "电池包1的单体温度55";
CM_ SG_ 2559246353 P1_CellTemp56 "电池包1的单体温度56";
CM_ SG_ 2559246353 P1_CellTemp57 "电池包1的单体温度57";
CM_ SG_ 2559246353 P1_CellTemp58 "电池包1的单体温度58";
CM_ SG_ 2559246353 P1_CellTemp59 "电池包1的单体温度59";
CM_ SG_ 2559246353 P1_CellTemp60 "电池包1的单体温度60";
CM_ SG_ 2559311889 P1_CellTemp61 "电池包1的单体温度61";
CM_ SG_ 2559311889 P1_CellTemp62 "电池包1的单体温度62";
CM_ SG_ 2559311889 P1_CellTemp63 "电池包1的单体温度63";
CM_ SG_ 2559311889 P1_CellTemp64 "电池包1的单体温度64";
CM_ SG_ 2559311889 P1_CellTemp65 "电池包1的单体温度65";
CM_ SG_ 2559377425 P1_CellTemp66 "电池包1的单体温度66";
CM_ SG_ 2559377425 P1_CellTemp67 "电池包1的单体温度67";
CM_ SG_ 2559377425 P1_CellTemp68 "电池包1的单体温度68";
CM_ SG_ 2559377425 P1_CellTemp69 "电池包1的单体温度69";
CM_ SG_ 2559377425 P1_CellTemp70 "电池包1的单体温度70";
CM_ SG_ 2559442961 P1_CellTemp71 "电池包1的单体温度71";
CM_ SG_ 2559442961 P1_CellTemp72 "电池包1的单体温度72";
CM_ SG_ 2559442961 P1_CellTemp73 "电池包1的单体温度73";
CM_ SG_ 2559442961 P1_CellTemp74 "电池包1的单体温度74";
CM_ SG_ 2559442961 P1_CellTemp75 "电池包1的单体温度75";
CM_ SG_ 2559508497 P1_CellTemp76 "电池包1的单体温度76";
CM_ SG_ 2559508497 P1_CellTemp77 "电池包1的单体温度77";
CM_ SG_ 2559508497 P1_CellTemp78 "电池包1的单体温度78";
CM_ SG_ 2559508497 P1_CellTemp79 "电池包1的单体温度79";
CM_ SG_ 2559508497 P1_CellTemp80 "电池包1的单体温度80";
CM_ SG_ 2559574033 P1_CellTemp81 "电池包1的单体温度81";
CM_ SG_ 2559574033 P1_CellTemp82 "电池包1的单体温度82";
CM_ SG_ 2559574033 P1_CellTemp83 "电池包1的单体温度83";
CM_ SG_ 2559574033 P1_CellTemp84 "电池包1的单体温度84";
CM_ SG_ 2559574033 P1_CellTemp85 "电池包1的单体温度85";
CM_ SG_ 2559639569 P1_CellTemp86 "电池包1的单体温度86";
CM_ SG_ 2559639569 P1_CellTemp87 "电池包1的单体温度87";
CM_ SG_ 2559639569 P1_CellTemp88 "电池包1的单体温度88";
CM_ SG_ 2559639569 P1_CellTemp89 "电池包1的单体温度89";
CM_ SG_ 2559639569 P1_CellTemp90 "电池包1的单体温度90";
CM_ SG_ 2559705105 P1_CellTemp91 "电池包1的单体温度91";
CM_ SG_ 2559705105 P1_CellTemp92 "电池包1的单体温度92";
CM_ SG_ 2559705105 P1_CellTemp93 "电池包1的单体温度93";
CM_ SG_ 2559705105 P1_CellTemp94 "电池包1的单体温度94";
CM_ SG_ 2559705105 P1_CellTemp95 "电池包1的单体温度95";
CM_ SG_ 2559770641 P1_CellTemp96 "电池包1的单体温度96";
CM_ SG_ 2559770641 P1_CellTemp97 "电池包1的单体温度97";
CM_ SG_ 2559770641 P1_CellTemp98 "电池包1的单体温度98";
CM_ SG_ 2559770641 P1_CellTemp99 "电池包1的单体温度99";
CM_ SG_ 2559770641 P1_CellTemp100 "电池包1的单体温度100";
CM_ SG_ 2559836177 P1_CellTemp101 "电池包1的单体温度101";
CM_ SG_ 2559836177 P1_CellTemp102 "电池包1的单体温度102";
CM_ SG_ 2559836177 P1_CellTemp103 "电池包1的单体温度103";
CM_ SG_ 2559836177 P1_CellTemp104 "电池包1的单体温度104";
CM_ SG_ 2559836177 P1_CellTemp105 "电池包1的单体温度105";
CM_ SG_ 2559901713 P1_CellTemp106 "电池包1的单体温度106";
CM_ SG_ 2559901713 P1_CellTemp107 "电池包1的单体温度107";
CM_ SG_ 2559901713 P1_CellTemp108 "电池包1的单体温度108";
CM_ SG_ 2559901713 P1_CellTemp109 "电池包1的单体温度109";
CM_ SG_ 2559901713 P1_CellTemp110 "电池包1的单体温度110";
CM_ SG_ 2559967249 P1_CellTemp111 "电池包1的单体温度111";
CM_ SG_ 2559967249 P1_CellTemp112 "电池包1的单体温度112";
CM_ SG_ 2559967249 P1_CellTemp113 "电池包1的单体温度113";
CM_ SG_ 2559967249 P1_CellTemp114 "电池包1的单体温度114";
CM_ SG_ 2559967249 P1_CellTemp115 "电池包1的单体温度115";
CM_ SG_ 2560032785 P1_CellTemp116 "电池包1的单体温度116";
CM_ SG_ 2560032785 P1_CellTemp117 "电池包1的单体温度117";
CM_ SG_ 2560032785 P1_CellTemp118 "电池包1的单体温度118";
CM_ SG_ 2560032785 P1_CellTemp119 "电池包1的单体温度119";
CM_ SG_ 2560032785 P1_CellTemp120 "电池包1的单体温度120";
CM_ SG_ 2560098321 P1_CellTemp121 "电池包1的单体温度121";
CM_ SG_ 2560098321 P1_CellTemp122 "电池包1的单体温度122";
CM_ SG_ 2560098321 P1_CellTemp123 "电池包1的单体温度123";
CM_ SG_ 2560098321 P1_CellTemp124 "电池包1的单体温度124";
CM_ SG_ 2560098321 P1_CellTemp125 "电池包1的单体温度125";
CM_ SG_ 2560163857 P1_CellTemp126 "电池包1的单体温度126";
CM_ SG_ 2560163857 P1_CellTemp127 "电池包1的单体温度127";
CM_ SG_ 2560163857 P1_CellTemp128 "电池包1的单体温度128";
CM_ SG_ 2560163857 P1_CellTemp129 "电池包1的单体温度129";
CM_ SG_ 2560163857 P1_CellTemp130 "电池包1的单体温度130";
CM_ SG_ 2560229393 P1_CellTemp131 "电池包1的单体温度131";
CM_ SG_ 2560229393 P1_CellTemp132 "电池包1的单体温度132";
CM_ SG_ 2560229393 P1_CellTemp133 "电池包1的单体温度133";
CM_ SG_ 2560229393 P1_CellTemp134 "电池包1的单体温度134";
CM_ SG_ 2560229393 P1_CellTemp135 "电池包1的单体温度135";
CM_ SG_ 2560294929 P1_CellTemp136 "电池包1的单体温度136";
CM_ SG_ 2560294929 P1_CellTemp137 "电池包1的单体温度137";
CM_ SG_ 2560294929 P1_CellTemp138 "电池包1的单体温度138";
CM_ SG_ 2560294929 P1_CellTemp139 "电池包1的单体温度139";
CM_ SG_ 2560294929 P1_CellTemp140 "电池包1的单体温度140";
CM_ SG_ 2560360465 P1_CellTemp141 "电池包1的单体温度141";
CM_ SG_ 2560360465 P1_CellTemp142 "电池包1的单体温度142";
CM_ SG_ 2560360465 P1_CellTemp143 "电池包1的单体温度143";
CM_ SG_ 2560360465 P1_CellTemp144 "电池包1的单体温度144";
CM_ SG_ 2560360465 P1_CellTemp145 "电池包1的单体温度145";
CM_ SG_ 2560426001 P1_CellTemp146 "电池包1的单体温度146";
CM_ SG_ 2560426001 P1_CellTemp147 "电池包1的单体温度147";
CM_ SG_ 2560426001 P1_CellTemp148 "电池包1的单体温度148";
CM_ SG_ 2560426001 P1_CellTemp149 "电池包1的单体温度149";
CM_ SG_ 2560426001 P1_CellTemp150 "电池包1的单体温度150";
CM_ SG_ 2560491537 P1_CellTemp151 "电池包1的单体温度151";
CM_ SG_ 2560491537 P1_CellTemp152 "电池包1的单体温度152";
CM_ SG_ 2560491537 P1_CellTemp153 "电池包1的单体温度153";
CM_ SG_ 2560491537 P1_CellTemp154 "电池包1的单体温度154";
CM_ SG_ 2560491537 P1_CellTemp155 "电池包1的单体温度155";
CM_ SG_ 2560557073 P1_CellTemp156 "电池包1的单体温度156";
CM_ SG_ 2560557073 P1_CellTemp157 "电池包1的单体温度157";
CM_ SG_ 2560557073 P1_CellTemp158 "电池包1的单体温度158";
CM_ SG_ 2560557073 P1_CellTemp159 "电池包1的单体温度159";
CM_ SG_ 2560557073 P1_CellTemp160 "电池包1的单体温度160";
CM_ SG_ 2560622609 P1_CellTemp161 "电池包1的单体温度161";
CM_ SG_ 2560622609 P1_CellTemp162 "电池包1的单体温度162";
CM_ SG_ 2560622609 P1_CellTemp163 "电池包1的单体温度163";
CM_ SG_ 2560622609 P1_CellTemp164 "电池包1的单体温度164";
CM_ SG_ 2560622609 P1_CellTemp165 "电池包1的单体温度165";
CM_ SG_ 2560688145 P1_CellTemp166 "电池包1的单体温度166";
CM_ SG_ 2560688145 P1_CellTemp167 "电池包1的单体温度167";
CM_ SG_ 2560688145 P1_CellTemp168 "电池包1的单体温度168";
CM_ SG_ 2560688145 P1_CellTemp169 "电池包1的单体温度169";
CM_ SG_ 2560688145 P1_CellTemp170 "电池包1的单体温度170";
CM_ SG_ 2560753681 P1_CellTemp171 "电池包1的单体温度171";
CM_ SG_ 2560753681 P1_CellTemp172 "电池包1的单体温度172";
CM_ SG_ 2560753681 P1_CellTemp173 "电池包1的单体温度173";
CM_ SG_ 2560753681 P1_CellTemp174 "电池包1的单体温度174";
CM_ SG_ 2560753681 P1_CellTemp175 "电池包1的单体温度175";
CM_ SG_ 2560819217 P1_CellTemp176 "电池包1的单体温度176";
CM_ SG_ 2560819217 P1_CellTemp177 "电池包1的单体温度177";
CM_ SG_ 2560819217 P1_CellTemp178 "电池包1的单体温度178";
CM_ SG_ 2560819217 P1_CellTemp179 "电池包1的单体温度179";
CM_ SG_ 2560819217 P1_CellTemp180 "电池包1的单体温度180";
CM_ SG_ 2560884753 P1_CellTemp181 "电池包1的单体温度181";
CM_ SG_ 2560884753 P1_CellTemp182 "电池包1的单体温度182";
CM_ SG_ 2560884753 P1_CellTemp183 "电池包1的单体温度183";
CM_ SG_ 2560884753 P1_CellTemp184 "电池包1的单体温度184";
CM_ SG_ 2560884753 P1_CellTemp185 "电池包1的单体温度185";
CM_ SG_ 2560950289 P1_CellTemp186 "电池包1的单体温度186";
CM_ SG_ 2560950289 P1_CellTemp187 "电池包1的单体温度187";
CM_ SG_ 2560950289 P1_CellTemp188 "电池包1的单体温度188";
CM_ SG_ 2560950289 P1_CellTemp189 "电池包1的单体温度189";
CM_ SG_ 2560950289 P1_CellTemp190 "电池包1的单体温度190";
CM_ SG_ 2561015825 P1_CellTemp191 "电池包1的单体温度191";
CM_ SG_ 2561015825 P1_CellTemp192 "电池包1的单体温度192";
CM_ SG_ 2561015825 P1_DatLen16DbgInfo1 "长度为16的调试信息1";
CM_ SG_ 2561015825 P1_DatLen16DbgInfo2 "长度为16的调试信息2";
CM_ SG_ 2561015825 P1_DatLen16DbgInfo3 "长度为16的调试信息3";
CM_ SG_ 2561015825 P1_DatLen16DbgInfo4 "长度为16的调试信息4";
CM_ SG_ 2550399010 P2_BMSPwrSuplVlt1 "电池包2的BMS供电电源电压1";
CM_ SG_ 2550399010 P2_BMSPwrSuplVlt2 "电池包2的BMS供电电源电压2";
CM_ SG_ 2550399010 P2_ChrgStationAuxPwrSuplVlt "电池包2的快充桩A+电压";
CM_ SG_ 2550399010 P2_BMSKL15ON "电池包2的BMS唤醒信号";
CM_ SG_ 2550399010 P2_DCStepState "电池包2的充电状态机";
CM_ SG_ 2550399010 P2_ExtLvWakeup_28VOnly "电池包2的外部唤醒";
CM_ SG_ 2550464546 P2_PackVltUprLmt "电池包2的电压使用上限";
CM_ SG_ 2550464546 P2_PackVltLoLmt "电池包2的电压使用下限";
CM_ SG_ 2550464546 P2_PackMaxDschrgCrnt "电池包2的最大允许放电电流";
CM_ SG_ 2550464546 P2_PackMaxChrgCrnt "电池包2的最大允许充电电流";
CM_ SG_ 2550530082 P2_PackDschrgPwrLmt "电池包2的放电功率限值";
CM_ SG_ 2550530082 P2_PackDschrgPwrStat "电池包2的放电功率状态";
CM_ SG_ 2550530082 P2_PackChrgPwrLmt "电池包2的充电功率限值";
CM_ SG_ 2550530082 P2_PackChrgPwrStat "电池包2的充电功率状态";
CM_ SG_ 2550595618 P2_ChrgrCplrStat "电池包2的充电枪连接状态";
CM_ SG_ 2550595618 P2_HVBattChrgSysStatus "电池包2的充电系统状态";
CM_ SG_ 2550595618 P2_DCChrgCrntCmd "电池包2的直流充电请求电流";
CM_ SG_ 2550595618 P2_CC2Vlt "电池包2的CC2电压值";
CM_ SG_ 2550595618 P2_DCRcptPosTemp "电池包2的快充充电插座正极温度";
CM_ SG_ 2550595618 P2_DCRcptNegTemp "电池包2的快充充电插座负极温度";
CM_ SG_ 2550595618 P2_Tm2FullChrg "电池包2满充剩余时间";
CM_ SG_ 2550661154 P2_Inlet1ClntTemp "进水口1冷却液温度";
CM_ SG_ 2550661154 P2_Inlet2ClntTemp "进水口2冷却液温度";
CM_ SG_ 2550661154 P2_Outlet1ClntTemp "出水口1冷却液温度";
CM_ SG_ 2550661154 P2_Outlet2ClntTemp "出水口2冷却液温度";
CM_ SG_ 2550661154 P2_TrgtClntTemp "冷却水目标温度";
CM_ SG_ 2550661154 P2_TrgtClntFlowRate "冷却水目标流量";
CM_ SG_ 2550726690 P2_MaxCellVlt "电池包2的最大单体电压";
CM_ SG_ 2550726690 P2_MaxCellVltNum "电池包2的最大单体电压编号";
CM_ SG_ 2550726690 P2_MinCellVlt "电池包2的最小单体电压";
CM_ SG_ 2550726690 P2_MinCellVltNum "电池包2的最小单体电压编号";
CM_ SG_ 2550726690 P2_AvgCellVlt "电池包2的平均单体电压";
CM_ SG_ 2550792226 P2_MaxCellTemp "电池包2的最高单体温度";
CM_ SG_ 2550792226 P2_MaxCellTempNum "电池包2的最高单体温度编号";
CM_ SG_ 2550792226 P2_MinCellTemp "电池包2的最低单体温度";
CM_ SG_ 2550792226 P2_MinCellTempNum "电池包2的最低单体温度编号";
CM_ SG_ 2550792226 P2_AvgCellTemp "电池包2的单体平均温度";
CM_ SG_ 2550857762 P2_PackTotFltNum "电池包2的电池故障总数";
CM_ SG_ 2550857762 P2_CellOverVoltage "电池包2的单体过压";
CM_ SG_ 2550857762 P2_CellUnderVoltage "电池包2的单体欠压";
CM_ SG_ 2550857762 P2_CellVoltageDiffHi "电池包2的单体压差过大";
CM_ SG_ 2550857762 P2_PackOverVoltage "电池包2的电压过高";
CM_ SG_ 2550857762 P2_PackUnderVoltage "电池包2的电压过低";
CM_ SG_ 2550857762 P2_CellOverTemp "电池包2的单体过温";
CM_ SG_ 2550857762 P2_CellTempLow "电池包2的单体温度过低";
CM_ SG_ 2550857762 P2_CellTempDiffHi "电池包2的单体温度差异过大";
CM_ SG_ 2550857762 P2_PackDschrgCrntHi "电池包2的放电电流过流";
CM_ SG_ 2550857762 P2_PackChrgCrntHi "电池包2的充电电流过流";
CM_ SG_ 2550857762 P2_PackCrnSnsr1OffsetHi "电池包2的电流传感器1零漂过大";
CM_ SG_ 2550857762 P2_HVIsolFlt "电池包2的高压绝缘故障";
CM_ SG_ 2550857762 P2_HVILFlt "电池包2的高压互锁故障";
CM_ SG_ 2550857762 P2_ThrmlRunaway "电池包2的热失控故障";
CM_ SG_ 2550857762 P2_CellVoltInvalid "电池包2的单体电压采样失效";
CM_ SG_ 2550857762 P2_CellTempInvalid "电池包2的电芯温度采样失效";
CM_ SG_ 2550857762 P2_DaisyChainComFlt "电池包2的菊花链通信故障";
CM_ SG_ 2550857762 P2_PackVoltRatFlt "电池包2的总电压与单体电压总和偏差过大";
CM_ SG_ 2550857762 P2_CrntSnsr1Invalid "电池包2的电流传感器1电流采样失效";
CM_ SG_ 2550857762 P2_CrntSnsr1OOR "电池包2的电流传感器1电流超出采样范围";
CM_ SG_ 2550857762 P2_CrntSnsr2Invalid "电池包2的电流传感器2电流采样失效";
CM_ SG_ 2550857762 P2_CrntSnsr2OOR "电池包2的电流传感器2电流超出采样范围";
CM_ SG_ 2550857762 P2_PackCrnSnsr2OffsetHi "电池包2的电流传感器2零漂过大";
CM_ SG_ 2550857762 P2_OutofEnergy "电池包2的电池剩余电量低";
CM_ SG_ 2550857762 P2_IsolDetCircErr "电池包2的绝缘检测电路失效";
CM_ SG_ 2550857762 P2_HVILCircShortToGND "电池包2的高压互锁对地短路";
CM_ SG_ 2550857762 P2_HVILCircShortToPwr "电池包2的高压互锁对电源短路";
CM_ SG_ 2550923298 P2_MainPosCntctrStkClsd "电池包2的主正继电器粘连故障";
CM_ SG_ 2550923298 P2_MainPosCntctrStkOpn "电池包2的主正继电器常开故障";
CM_ SG_ 2550923298 P2_MainNegCntctr1StkClsd "电池包2的主负继电器1粘连故障";
CM_ SG_ 2550923298 P2_MainNegCntctr1StkOpn "电池包2的主负继电器1常开故障";
CM_ SG_ 2550923298 P2_MainNegCntctr2StkClsd "电池包2的主负继电器2粘连故障";
CM_ SG_ 2550923298 P2_MainNegCntctr2StkOpn "电池包2的主负继电器2常开故障";
CM_ SG_ 2550923298 P2_PrechargTmOut "电池包2的预充超时故障";
CM_ SG_ 2550923298 P2_PrechrgCrntHi "电池包2的预充过流故障";
CM_ SG_ 2550923298 P2_ChrgCplrPosTempHi "电池包2的充电正极接口温度过高故障";
CM_ SG_ 2550923298 P2_ChrgCplrNegTempHi "电池包2的充电负极接口温度过高故障";
CM_ SG_ 2550923298 P2_BMSPwrSuplVlt1Hi "电池包2的BMS供电电压1过高";
CM_ SG_ 2550923298 P2_BMSPwrSuplVlt1Lo "电池包2的BMS供电电压1过低";
CM_ SG_ 2550923298 P2_BMSPwrSuplVlt2Hi "电池包2的BMS供电电压2过高";
CM_ SG_ 2550923298 P2_BMSPwrSuplVlt2Lo "电池包2的BMS供电电压2过低";
CM_ SG_ 2550923298 P2_CntctrCirPwrSuplVltLo "电池包2的继电器驱动供电电压过低";
CM_ SG_ 2550923298 P2_CntctrCirPwrSuplVltHi "电池包2的继电器驱动供电电压过高";
CM_ SG_ 2550923298 P2_CAN1BusOff "电池包2的CAN1通信Bus off";
CM_ SG_ 2550923298 P2_CAN1BusTmOut "电池包2的CAN1报文超时（Timeout）";
CM_ SG_ 2550923298 P2_CAN2BusOff "电池包2的CAN2通信Bus off";
CM_ SG_ 2550923298 P2_CAN2BusTmOut "电池包2的CAN2报文超时（Timeout）";
CM_ SG_ 2550923298 P2_CellBalCircTempHi "电池包2的均衡电路过温";
CM_ SG_ 2550923298 P2_ClntInTempHi "电池包2的入水口温度过高";
CM_ SG_ 2550923298 P2_ClntOutTempHi "电池包2的出水口温度过高";
CM_ SG_ 2550923298 P2_CellExtrmUdrVolt "电池包2的单体极限欠压";
CM_ SG_ 2550923298 P2_CellExtrmOvrVolt "电池包2的单体极限过压";
CM_ SG_ 2550923298 P2_Branch1DischrgCrntHi  "电池包2的支路1放电过流";
CM_ SG_ 2550923298 P2_Branch2DischrgCrntHi  "电池包2的支路2放电过流";
CM_ SG_ 2550923298 P2_Branch1ChrgCrntHi  "电池包2的支路1充电过流";
CM_ SG_ 2550923298 P2_Branch2ChrgCrntHi  "电池包2的支路2充电过流";
CM_ SG_ 2550923298 P2_InitFailed "电池包2的BMS初始化失败";
CM_ SG_ 2550923298 P2_PackErrCode "电池包2的故障代码";
CM_ SG_ 2550988834 P2_PackTotCellNum "电池包2的单体电池总数";
CM_ SG_ 2550988834 P2_PackTotCellTempSnsrNum "电池包2的单体温度传感器总数";
CM_ SG_ 2552299554 P2_BMSASWMajVerNum "电池包2的BMS应用层软件主版本号";
CM_ SG_ 2552299554 P2_BMSASWMinVerNum "电池包2的BMS应用层软件子版本号";
CM_ SG_ 2552299554 P2_BMSASWPatchVerNum "电池包2的BMS应用层软件修订版本号";
CM_ SG_ 2552299554 P2_BMSBSWMajVerNum "电池包2的BMS底层软件主版本号";
CM_ SG_ 2552299554 P2_BMSBSWMinVerNum "电池包2的BMS底层软件子版本号";
CM_ SG_ 2552299554 P2_BMSBSWPatchVerNum "电池包2的BMS底层软件修订版本号";
CM_ SG_ 2554396706 P2_CellVoltage1 "电池包2的单体电压1";
CM_ SG_ 2554396706 P2_CellVoltage2 "电池包2的单体电压2";
CM_ SG_ 2554396706 P2_CellVoltage3 "电池包2的单体电压3";
CM_ SG_ 2554396706 P2_CellVoltage4 "电池包2的单体电压4";
CM_ SG_ 2554396706 P2_BalSwCell1 "电池包2的电芯1均衡状态";
CM_ SG_ 2554396706 P2_BalSwCell2 "电池包2的电芯2均衡状态";
CM_ SG_ 2554396706 P2_BalSwCell3 "电池包2的电芯3均衡状态";
CM_ SG_ 2554396706 P2_BalSwCell4 "电池包2的电芯4均衡状态";
CM_ SG_ 2554462242 P2_CellVoltage5 "电池包2的单体电压5";
CM_ SG_ 2554462242 P2_CellVoltage6 "电池包2的单体电压6";
CM_ SG_ 2554462242 P2_CellVoltage7 "电池包2的单体电压7";
CM_ SG_ 2554462242 P2_CellVoltage8 "电池包2的单体电压8";
CM_ SG_ 2554462242 P2_BalSwCell5 "电池包2的电芯5均衡状态";
CM_ SG_ 2554462242 P2_BalSwCell6 "电池包2的电芯6均衡状态";
CM_ SG_ 2554462242 P2_BalSwCell7 "电池包2的电芯7均衡状态";
CM_ SG_ 2554462242 P2_BalSwCell8 "电池包2的电芯8均衡状态";
CM_ SG_ 2554527778 P2_CellVoltage9 "电池包2的单体电压9";
CM_ SG_ 2554527778 P2_CellVoltage10 "电池包2的单体电压10";
CM_ SG_ 2554527778 P2_CellVoltage11 "电池包2的单体电压11";
CM_ SG_ 2554527778 P2_CellVoltage12 "电池包2的单体电压12";
CM_ SG_ 2554527778 P2_BalSwCell9 "电池包2的电芯9均衡状态";
CM_ SG_ 2554527778 P2_BalSwCell10 "电池包2的电芯10均衡状态";
CM_ SG_ 2554527778 P2_BalSwCell11 "电池包2的电芯11均衡状态";
CM_ SG_ 2554527778 P2_BalSwCell12 "电池包2的电芯12均衡状态";
CM_ SG_ 2554593314 P2_CellVoltage13 "电池包2的单体电压13";
CM_ SG_ 2554593314 P2_CellVoltage14 "电池包2的单体电压14";
CM_ SG_ 2554593314 P2_CellVoltage15 "电池包2的单体电压15";
CM_ SG_ 2554593314 P2_CellVoltage16 "电池包2的单体电压16";
CM_ SG_ 2554593314 P2_BalSwCell13 "电池包2的电芯13均衡状态";
CM_ SG_ 2554593314 P2_BalSwCell14 "电池包2的电芯14均衡状态";
CM_ SG_ 2554593314 P2_BalSwCell15 "电池包2的电芯15均衡状态";
CM_ SG_ 2554593314 P2_BalSwCell16 "电池包2的电芯16均衡状态";
CM_ SG_ 2554658850 P2_CellVoltage17 "电池包2的单体电压17";
CM_ SG_ 2554658850 P2_CellVoltage18 "电池包2的单体电压18";
CM_ SG_ 2554658850 P2_CellVoltage19 "电池包2的单体电压19";
CM_ SG_ 2554658850 P2_CellVoltage20 "电池包2的单体电压20";
CM_ SG_ 2554658850 P2_BalSwCell17 "电池包2的电芯17均衡状态";
CM_ SG_ 2554658850 P2_BalSwCell18 "电池包2的电芯18均衡状态";
CM_ SG_ 2554658850 P2_BalSwCell19 "电池包2的电芯19均衡状态";
CM_ SG_ 2554658850 P2_BalSwCell20 "电池包2的电芯20均衡状态";
CM_ SG_ 2554724386 P2_CellVoltage21 "电池包2的单体电压21";
CM_ SG_ 2554724386 P2_CellVoltage22 "电池包2的单体电压22";
CM_ SG_ 2554724386 P2_CellVoltage23 "电池包2的单体电压23";
CM_ SG_ 2554724386 P2_CellVoltage24 "电池包2的单体电压24";
CM_ SG_ 2554724386 P2_BalSwCell21 "电池包2的电芯21均衡状态";
CM_ SG_ 2554724386 P2_BalSwCell22 "电池包2的电芯22均衡状态";
CM_ SG_ 2554724386 P2_BalSwCell23 "电池包2的电芯23均衡状态";
CM_ SG_ 2554724386 P2_BalSwCell24 "电池包2的电芯24均衡状态";
CM_ SG_ 2554789922 P2_CellVoltage25 "电池包2的单体电压25";
CM_ SG_ 2554789922 P2_CellVoltage26 "电池包2的单体电压26";
CM_ SG_ 2554789922 P2_CellVoltage27 "电池包2的单体电压27";
CM_ SG_ 2554789922 P2_CellVoltage28 "电池包2的单体电压28";
CM_ SG_ 2554789922 P2_BalSwCell25 "电池包2的电芯25均衡状态";
CM_ SG_ 2554789922 P2_BalSwCell26 "电池包2的电芯26均衡状态";
CM_ SG_ 2554789922 P2_BalSwCell27 "电池包2的电芯27均衡状态";
CM_ SG_ 2554789922 P2_BalSwCell28 "电池包2的电芯28均衡状态";
CM_ SG_ 2554855458 P2_CellVoltage29 "电池包2的单体电压29";
CM_ SG_ 2554855458 P2_CellVoltage30 "电池包2的单体电压30";
CM_ SG_ 2554855458 P2_CellVoltage31 "电池包2的单体电压31";
CM_ SG_ 2554855458 P2_CellVoltage32 "电池包2的单体电压32";
CM_ SG_ 2554855458 P2_BalSwCell29 "电池包2的电芯29均衡状态";
CM_ SG_ 2554855458 P2_BalSwCell30 "电池包2的电芯30均衡状态";
CM_ SG_ 2554855458 P2_BalSwCell31 "电池包2的电芯31均衡状态";
CM_ SG_ 2554855458 P2_BalSwCell32 "电池包2的电芯32均衡状态";
CM_ SG_ 2554920994 P2_CellVoltage33 "电池包2的单体电压33";
CM_ SG_ 2554920994 P2_CellVoltage34 "电池包2的单体电压34";
CM_ SG_ 2554920994 P2_CellVoltage35 "电池包2的单体电压35";
CM_ SG_ 2554920994 P2_CellVoltage36 "电池包2的单体电压36";
CM_ SG_ 2554920994 P2_BalSwCell33 "电池包2的电芯33均衡状态";
CM_ SG_ 2554920994 P2_BalSwCell34 "电池包2的电芯34均衡状态";
CM_ SG_ 2554920994 P2_BalSwCell35 "电池包2的电芯35均衡状态";
CM_ SG_ 2554920994 P2_BalSwCell36 "电池包2的电芯36均衡状态";
CM_ SG_ 2554986530 P2_CellVoltage37 "电池包2的单体电压37";
CM_ SG_ 2554986530 P2_CellVoltage38 "电池包2的单体电压38";
CM_ SG_ 2554986530 P2_CellVoltage39 "电池包2的单体电压39";
CM_ SG_ 2554986530 P2_CellVoltage40 "电池包2的单体电压40";
CM_ SG_ 2554986530 P2_BalSwCell37 "电池包2的电芯37均衡状态";
CM_ SG_ 2554986530 P2_BalSwCell38 "电池包2的电芯38均衡状态";
CM_ SG_ 2554986530 P2_BalSwCell39 "电池包2的电芯39均衡状态";
CM_ SG_ 2554986530 P2_BalSwCell40 "电池包2的电芯40均衡状态";
CM_ SG_ 2555052066 P2_CellVoltage41 "电池包2的单体电压41";
CM_ SG_ 2555052066 P2_CellVoltage42 "电池包2的单体电压42";
CM_ SG_ 2555052066 P2_CellVoltage43 "电池包2的单体电压43";
CM_ SG_ 2555052066 P2_CellVoltage44 "电池包2的单体电压44";
CM_ SG_ 2555052066 P2_BalSwCell41 "电池包2的电芯41均衡状态";
CM_ SG_ 2555052066 P2_BalSwCell42 "电池包2的电芯42均衡状态";
CM_ SG_ 2555052066 P2_BalSwCell43 "电池包2的电芯43均衡状态";
CM_ SG_ 2555052066 P2_BalSwCell44 "电池包2的电芯44均衡状态";
CM_ SG_ 2555117602 P2_CellVoltage45 "电池包2的单体电压45";
CM_ SG_ 2555117602 P2_CellVoltage46 "电池包2的单体电压46";
CM_ SG_ 2555117602 P2_CellVoltage47 "电池包2的单体电压47";
CM_ SG_ 2555117602 P2_CellVoltage48 "电池包2的单体电压48";
CM_ SG_ 2555117602 P2_BalSwCell45 "电池包2的电芯45均衡状态";
CM_ SG_ 2555117602 P2_BalSwCell46 "电池包2的电芯46均衡状态";
CM_ SG_ 2555117602 P2_BalSwCell47 "电池包2的电芯47均衡状态";
CM_ SG_ 2555117602 P2_BalSwCell48 "电池包2的电芯48均衡状态";
CM_ SG_ 2555183138 P2_CellVoltage49 "电池包2的单体电压49";
CM_ SG_ 2555183138 P2_CellVoltage50 "电池包2的单体电压50";
CM_ SG_ 2555183138 P2_CellVoltage51 "电池包2的单体电压51";
CM_ SG_ 2555183138 P2_CellVoltage52 "电池包2的单体电压52";
CM_ SG_ 2555183138 P2_BalSwCell49 "电池包2的电芯49均衡状态";
CM_ SG_ 2555183138 P2_BalSwCell50 "电池包2的电芯50均衡状态";
CM_ SG_ 2555183138 P2_BalSwCell51 "电池包2的电芯51均衡状态";
CM_ SG_ 2555183138 P2_BalSwCell52 "电池包2的电芯52均衡状态";
CM_ SG_ 2555248674 P2_CellVoltage53 "电池包2的单体电压53";
CM_ SG_ 2555248674 P2_CellVoltage54 "电池包2的单体电压54";
CM_ SG_ 2555248674 P2_CellVoltage55 "电池包2的单体电压55";
CM_ SG_ 2555248674 P2_CellVoltage56 "电池包2的单体电压56";
CM_ SG_ 2555248674 P2_BalSwCell53 "电池包2的电芯53均衡状态";
CM_ SG_ 2555248674 P2_BalSwCell54 "电池包2的电芯54均衡状态";
CM_ SG_ 2555248674 P2_BalSwCell55 "电池包2的电芯55均衡状态";
CM_ SG_ 2555248674 P2_BalSwCell56 "电池包2的电芯56均衡状态";
CM_ SG_ 2555314210 P2_CellVoltage57 "电池包2的单体电压57";
CM_ SG_ 2555314210 P2_CellVoltage58 "电池包2的单体电压58";
CM_ SG_ 2555314210 P2_CellVoltage59 "电池包2的单体电压59";
CM_ SG_ 2555314210 P2_CellVoltage60 "电池包2的单体电压60";
CM_ SG_ 2555314210 P2_BalSwCell57 "电池包2的电芯57均衡状态";
CM_ SG_ 2555314210 P2_BalSwCell58 "电池包2的电芯58均衡状态";
CM_ SG_ 2555314210 P2_BalSwCell59 "电池包2的电芯59均衡状态";
CM_ SG_ 2555314210 P2_BalSwCell60 "电池包2的电芯60均衡状态";
CM_ SG_ 2555379746 P2_CellVoltage61 "电池包2的单体电压61";
CM_ SG_ 2555379746 P2_CellVoltage62 "电池包2的单体电压62";
CM_ SG_ 2555379746 P2_CellVoltage63 "电池包2的单体电压63";
CM_ SG_ 2555379746 P2_CellVoltage64 "电池包2的单体电压64";
CM_ SG_ 2555379746 P2_BalSwCell61 "电池包2的电芯61均衡状态";
CM_ SG_ 2555379746 P2_BalSwCell62 "电池包2的电芯62均衡状态";
CM_ SG_ 2555379746 P2_BalSwCell63 "电池包2的电芯63均衡状态";
CM_ SG_ 2555379746 P2_BalSwCell64 "电池包2的电芯64均衡状态";
CM_ SG_ 2555445282 P2_CellVoltage65 "电池包2的单体电压65";
CM_ SG_ 2555445282 P2_CellVoltage66 "电池包2的单体电压66";
CM_ SG_ 2555445282 P2_CellVoltage67 "电池包2的单体电压67";
CM_ SG_ 2555445282 P2_CellVoltage68 "电池包2的单体电压68";
CM_ SG_ 2555445282 P2_BalSwCell65 "电池包2的电芯65均衡状态";
CM_ SG_ 2555445282 P2_BalSwCell66 "电池包2的电芯66均衡状态";
CM_ SG_ 2555445282 P2_BalSwCell67 "电池包2的电芯67均衡状态";
CM_ SG_ 2555445282 P2_BalSwCell68 "电池包2的电芯68均衡状态";
CM_ SG_ 2555510818 P2_CellVoltage69 "电池包2的单体电压69";
CM_ SG_ 2555510818 P2_CellVoltage70 "电池包2的单体电压70";
CM_ SG_ 2555510818 P2_CellVoltage71 "电池包2的单体电压71";
CM_ SG_ 2555510818 P2_CellVoltage72 "电池包2的单体电压72";
CM_ SG_ 2555510818 P2_BalSwCell69 "电池包2的电芯69均衡状态";
CM_ SG_ 2555510818 P2_BalSwCell70 "电池包2的电芯70均衡状态";
CM_ SG_ 2555510818 P2_BalSwCell71 "电池包2的电芯71均衡状态";
CM_ SG_ 2555510818 P2_BalSwCell72 "电池包2的电芯72均衡状态";
CM_ SG_ 2555576354 P2_CellVoltage73 "电池包2的单体电压73";
CM_ SG_ 2555576354 P2_CellVoltage74 "电池包2的单体电压74";
CM_ SG_ 2555576354 P2_CellVoltage75 "电池包2的单体电压75";
CM_ SG_ 2555576354 P2_CellVoltage76 "电池包2的单体电压76";
CM_ SG_ 2555576354 P2_BalSwCell73 "电池包2的电芯73均衡状态";
CM_ SG_ 2555576354 P2_BalSwCell74 "电池包2的电芯74均衡状态";
CM_ SG_ 2555576354 P2_BalSwCell75 "电池包2的电芯75均衡状态";
CM_ SG_ 2555576354 P2_BalSwCell76 "电池包2的电芯76均衡状态";
CM_ SG_ 2555641890 P2_CellVoltage77 "电池包2的单体电压77";
CM_ SG_ 2555641890 P2_CellVoltage78 "电池包2的单体电压78";
CM_ SG_ 2555641890 P2_CellVoltage79 "电池包2的单体电压79";
CM_ SG_ 2555641890 P2_CellVoltage80 "电池包2的单体电压80";
CM_ SG_ 2555641890 P2_BalSwCell77 "电池包2的电芯77均衡状态";
CM_ SG_ 2555641890 P2_BalSwCell78 "电池包2的电芯78均衡状态";
CM_ SG_ 2555641890 P2_BalSwCell79 "电池包2的电芯79均衡状态";
CM_ SG_ 2555641890 P2_BalSwCell80 "电池包2的电芯80均衡状态";
CM_ SG_ 2555707426 P2_CellVoltage81 "电池包2的单体电压81";
CM_ SG_ 2555707426 P2_CellVoltage82 "电池包2的单体电压82";
CM_ SG_ 2555707426 P2_CellVoltage83 "电池包2的单体电压83";
CM_ SG_ 2555707426 P2_CellVoltage84 "电池包2的单体电压84";
CM_ SG_ 2555707426 P2_BalSwCell81 "电池包2的电芯81均衡状态";
CM_ SG_ 2555707426 P2_BalSwCell82 "电池包2的电芯82均衡状态";
CM_ SG_ 2555707426 P2_BalSwCell83 "电池包2的电芯83均衡状态";
CM_ SG_ 2555707426 P2_BalSwCell84 "电池包2的电芯84均衡状态";
CM_ SG_ 2555772962 P2_CellVoltage85 "电池包2的单体电压85";
CM_ SG_ 2555772962 P2_CellVoltage86 "电池包2的单体电压86";
CM_ SG_ 2555772962 P2_CellVoltage87 "电池包2的单体电压87";
CM_ SG_ 2555772962 P2_CellVoltage88 "电池包2的单体电压88";
CM_ SG_ 2555772962 P2_BalSwCell85 "电池包2的电芯85均衡状态";
CM_ SG_ 2555772962 P2_BalSwCell86 "电池包2的电芯86均衡状态";
CM_ SG_ 2555772962 P2_BalSwCell87 "电池包2的电芯87均衡状态";
CM_ SG_ 2555772962 P2_BalSwCell88 "电池包2的电芯88均衡状态";
CM_ SG_ 2555838498 P2_CellVoltage89 "电池包2的单体电压89";
CM_ SG_ 2555838498 P2_CellVoltage90 "电池包2的单体电压90";
CM_ SG_ 2555838498 P2_CellVoltage91 "电池包2的单体电压91";
CM_ SG_ 2555838498 P2_CellVoltage92 "电池包2的单体电压92";
CM_ SG_ 2555838498 P2_BalSwCell89 "电池包2的电芯89均衡状态";
CM_ SG_ 2555838498 P2_BalSwCell90 "电池包2的电芯90均衡状态";
CM_ SG_ 2555838498 P2_BalSwCell91 "电池包2的电芯91均衡状态";
CM_ SG_ 2555838498 P2_BalSwCell92 "电池包2的电芯92均衡状态";
CM_ SG_ 2555904034 P2_CellVoltage93 "电池包2的单体电压93";
CM_ SG_ 2555904034 P2_CellVoltage94 "电池包2的单体电压94";
CM_ SG_ 2555904034 P2_CellVoltage95 "电池包2的单体电压95";
CM_ SG_ 2555904034 P2_CellVoltage96 "电池包2的单体电压96";
CM_ SG_ 2555904034 P2_BalSwCell93 "电池包2的电芯93均衡状态";
CM_ SG_ 2555904034 P2_BalSwCell94 "电池包2的电芯94均衡状态";
CM_ SG_ 2555904034 P2_BalSwCell95 "电池包2的电芯95均衡状态";
CM_ SG_ 2555904034 P2_BalSwCell96 "电池包2的电芯96均衡状态";
CM_ SG_ 2555969570 P2_CellVoltage97 "电池包2的单体电压97";
CM_ SG_ 2555969570 P2_CellVoltage98 "电池包2的单体电压98";
CM_ SG_ 2555969570 P2_CellVoltage99 "电池包2的单体电压99";
CM_ SG_ 2555969570 P2_CellVoltage100 "电池包2的单体电压100";
CM_ SG_ 2555969570 P2_BalSwCell97 "电池包2的电芯97均衡状态";
CM_ SG_ 2555969570 P2_BalSwCell98 "电池包2的电芯98均衡状态";
CM_ SG_ 2555969570 P2_BalSwCell99 "电池包2的电芯99均衡状态";
CM_ SG_ 2555969570 P2_BalSwCell100 "电池包2的电芯100均衡状态";
CM_ SG_ 2556035106 P2_CellVoltage101 "电池包2的单体电压101";
CM_ SG_ 2556035106 P2_CellVoltage102 "电池包2的单体电压102";
CM_ SG_ 2556035106 P2_CellVoltage103 "电池包2的单体电压103";
CM_ SG_ 2556035106 P2_CellVoltage104 "电池包2的单体电压104";
CM_ SG_ 2556035106 P2_BalSwCell101 "电池包2的电芯101均衡状态";
CM_ SG_ 2556035106 P2_BalSwCell102 "电池包2的电芯102均衡状态";
CM_ SG_ 2556035106 P2_BalSwCell103 "电池包2的电芯103均衡状态";
CM_ SG_ 2556035106 P2_BalSwCell104 "电池包2的电芯104均衡状态";
CM_ SG_ 2556100642 P2_CellVoltage105 "电池包2的单体电压105";
CM_ SG_ 2556100642 P2_CellVoltage106 "电池包2的单体电压106";
CM_ SG_ 2556100642 P2_CellVoltage107 "电池包2的单体电压107";
CM_ SG_ 2556100642 P2_CellVoltage108 "电池包2的单体电压108";
CM_ SG_ 2556100642 P2_BalSwCell105 "电池包2的电芯105均衡状态";
CM_ SG_ 2556100642 P2_BalSwCell106 "电池包2的电芯106均衡状态";
CM_ SG_ 2556100642 P2_BalSwCell107 "电池包2的电芯107均衡状态";
CM_ SG_ 2556100642 P2_BalSwCell108 "电池包2的电芯108均衡状态";
CM_ SG_ 2556166178 P2_CellVoltage109 "电池包2的单体电压109";
CM_ SG_ 2556166178 P2_CellVoltage110 "电池包2的单体电压110";
CM_ SG_ 2556166178 P2_CellVoltage111 "电池包2的单体电压111";
CM_ SG_ 2556166178 P2_CellVoltage112 "电池包2的单体电压112";
CM_ SG_ 2556166178 P2_BalSwCell109 "电池包2的电芯109均衡状态";
CM_ SG_ 2556166178 P2_BalSwCell110 "电池包2的电芯110均衡状态";
CM_ SG_ 2556166178 P2_BalSwCell111 "电池包2的电芯111均衡状态";
CM_ SG_ 2556166178 P2_BalSwCell112 "电池包2的电芯112均衡状态";
CM_ SG_ 2556231714 P2_CellVoltage113 "电池包2的单体电压113";
CM_ SG_ 2556231714 P2_CellVoltage114 "电池包2的单体电压114";
CM_ SG_ 2556231714 P2_CellVoltage115 "电池包2的单体电压115";
CM_ SG_ 2556231714 P2_CellVoltage116 "电池包2的单体电压116";
CM_ SG_ 2556231714 P2_BalSwCell113 "电池包2的电芯113均衡状态";
CM_ SG_ 2556231714 P2_BalSwCell114 "电池包2的电芯114均衡状态";
CM_ SG_ 2556231714 P2_BalSwCell115 "电池包2的电芯115均衡状态";
CM_ SG_ 2556231714 P2_BalSwCell116 "电池包2的电芯116均衡状态";
CM_ SG_ 2556297250 P2_CellVoltage117 "电池包2的单体电压117";
CM_ SG_ 2556297250 P2_CellVoltage118 "电池包2的单体电压118";
CM_ SG_ 2556297250 P2_CellVoltage119 "电池包2的单体电压119";
CM_ SG_ 2556297250 P2_CellVoltage120 "电池包2的单体电压120";
CM_ SG_ 2556297250 P2_BalSwCell117 "电池包2的电芯117均衡状态";
CM_ SG_ 2556297250 P2_BalSwCell118 "电池包2的电芯118均衡状态";
CM_ SG_ 2556297250 P2_BalSwCell119 "电池包2的电芯119均衡状态";
CM_ SG_ 2556297250 P2_BalSwCell120 "电池包2的电芯120均衡状态";
CM_ SG_ 2556362786 P2_CellVoltage121 "电池包2的单体电压121";
CM_ SG_ 2556362786 P2_CellVoltage122 "电池包2的单体电压122";
CM_ SG_ 2556362786 P2_CellVoltage123 "电池包2的单体电压123";
CM_ SG_ 2556362786 P2_CellVoltage124 "电池包2的单体电压124";
CM_ SG_ 2556362786 P2_BalSwCell121 "电池包2的电芯121均衡状态";
CM_ SG_ 2556362786 P2_BalSwCell122 "电池包2的电芯122均衡状态";
CM_ SG_ 2556362786 P2_BalSwCell123 "电池包2的电芯123均衡状态";
CM_ SG_ 2556362786 P2_BalSwCell124 "电池包2的电芯124均衡状态";
CM_ SG_ 2556428322 P2_CellVoltage125 "电池包2的单体电压125";
CM_ SG_ 2556428322 P2_CellVoltage126 "电池包2的单体电压126";
CM_ SG_ 2556428322 P2_CellVoltage127 "电池包2的单体电压127";
CM_ SG_ 2556428322 P2_CellVoltage128 "电池包2的单体电压128";
CM_ SG_ 2556428322 P2_BalSwCell125 "电池包2的电芯125均衡状态";
CM_ SG_ 2556428322 P2_BalSwCell126 "电池包2的电芯126均衡状态";
CM_ SG_ 2556428322 P2_BalSwCell127 "电池包2的电芯127均衡状态";
CM_ SG_ 2556428322 P2_BalSwCell128 "电池包2的电芯128均衡状态";
CM_ SG_ 2556493858 P2_CellVoltage129 "电池包2的单体电压129";
CM_ SG_ 2556493858 P2_CellVoltage130 "电池包2的单体电压130";
CM_ SG_ 2556493858 P2_CellVoltage131 "电池包2的单体电压131";
CM_ SG_ 2556493858 P2_CellVoltage132 "电池包2的单体电压132";
CM_ SG_ 2556493858 P2_BalSwCell129 "电池包2的电芯129均衡状态";
CM_ SG_ 2556493858 P2_BalSwCell130 "电池包2的电芯130均衡状态";
CM_ SG_ 2556493858 P2_BalSwCell131 "电池包2的电芯131均衡状态";
CM_ SG_ 2556493858 P2_BalSwCell132 "电池包2的电芯132均衡状态";
CM_ SG_ 2556559394 P2_CellVoltage133 "电池包2的单体电压133";
CM_ SG_ 2556559394 P2_CellVoltage134 "电池包2的单体电压134";
CM_ SG_ 2556559394 P2_CellVoltage135 "电池包2的单体电压135";
CM_ SG_ 2556559394 P2_CellVoltage136 "电池包2的单体电压136";
CM_ SG_ 2556559394 P2_BalSwCell133 "电池包2的电芯133均衡状态";
CM_ SG_ 2556559394 P2_BalSwCell134 "电池包2的电芯134均衡状态";
CM_ SG_ 2556559394 P2_BalSwCell135 "电池包2的电芯135均衡状态";
CM_ SG_ 2556559394 P2_BalSwCell136 "电池包2的电芯136均衡状态";
CM_ SG_ 2556624930 P2_CellVoltage137 "电池包2的单体电压137";
CM_ SG_ 2556624930 P2_CellVoltage138 "电池包2的单体电压138";
CM_ SG_ 2556624930 P2_CellVoltage139 "电池包2的单体电压139";
CM_ SG_ 2556624930 P2_CellVoltage140 "电池包2的单体电压140";
CM_ SG_ 2556624930 P2_BalSwCell137 "电池包2的电芯137均衡状态";
CM_ SG_ 2556624930 P2_BalSwCell138 "电池包2的电芯138均衡状态";
CM_ SG_ 2556624930 P2_BalSwCell139 "电池包2的电芯139均衡状态";
CM_ SG_ 2556624930 P2_BalSwCell140 "电池包2的电芯140均衡状态";
CM_ SG_ 2556690466 P2_CellVoltage141 "电池包2的单体电压141";
CM_ SG_ 2556690466 P2_CellVoltage142 "电池包2的单体电压142";
CM_ SG_ 2556690466 P2_CellVoltage143 "电池包2的单体电压143";
CM_ SG_ 2556690466 P2_CellVoltage144 "电池包2的单体电压144";
CM_ SG_ 2556690466 P2_BalSwCell141 "电池包2的电芯141均衡状态";
CM_ SG_ 2556690466 P2_BalSwCell142 "电池包2的电芯142均衡状态";
CM_ SG_ 2556690466 P2_BalSwCell143 "电池包2的电芯143均衡状态";
CM_ SG_ 2556690466 P2_BalSwCell144 "电池包2的电芯144均衡状态";
CM_ SG_ 2556756002 P2_CellVoltage145 "电池包2的单体电压145";
CM_ SG_ 2556756002 P2_CellVoltage146 "电池包2的单体电压146";
CM_ SG_ 2556756002 P2_CellVoltage147 "电池包2的单体电压147";
CM_ SG_ 2556756002 P2_CellVoltage148 "电池包2的单体电压148";
CM_ SG_ 2556756002 P2_BalSwCell145 "电池包2的电芯145均衡状态";
CM_ SG_ 2556756002 P2_BalSwCell146 "电池包2的电芯146均衡状态";
CM_ SG_ 2556756002 P2_BalSwCell147 "电池包2的电芯147均衡状态";
CM_ SG_ 2556756002 P2_BalSwCell148 "电池包2的电芯148均衡状态";
CM_ SG_ 2556821538 P2_CellVoltage149 "电池包2的单体电压149";
CM_ SG_ 2556821538 P2_CellVoltage150 "电池包2的单体电压150";
CM_ SG_ 2556821538 P2_CellVoltage151 "电池包2的单体电压151";
CM_ SG_ 2556821538 P2_CellVoltage152 "电池包2的单体电压152";
CM_ SG_ 2556821538 P2_BalSwCell149 "电池包2的电芯149均衡状态";
CM_ SG_ 2556821538 P2_BalSwCell150 "电池包2的电芯150均衡状态";
CM_ SG_ 2556821538 P2_BalSwCell151 "电池包2的电芯151均衡状态";
CM_ SG_ 2556821538 P2_BalSwCell152 "电池包2的电芯152均衡状态";
CM_ SG_ 2556887074 P2_CellVoltage153 "电池包2的单体电压153";
CM_ SG_ 2556887074 P2_CellVoltage154 "电池包2的单体电压154";
CM_ SG_ 2556887074 P2_CellVoltage155 "电池包2的单体电压155";
CM_ SG_ 2556887074 P2_CellVoltage156 "电池包2的单体电压156";
CM_ SG_ 2556887074 P2_BalSwCell153 "电池包2的电芯153均衡状态";
CM_ SG_ 2556887074 P2_BalSwCell154 "电池包2的电芯154均衡状态";
CM_ SG_ 2556887074 P2_BalSwCell155 "电池包2的电芯155均衡状态";
CM_ SG_ 2556887074 P2_BalSwCell156 "电池包2的电芯156均衡状态";
CM_ SG_ 2556952610 P2_CellVoltage157 "电池包2的单体电压157";
CM_ SG_ 2556952610 P2_CellVoltage158 "电池包2的单体电压158";
CM_ SG_ 2556952610 P2_CellVoltage159 "电池包2的单体电压159";
CM_ SG_ 2556952610 P2_CellVoltage160 "电池包2的单体电压160";
CM_ SG_ 2556952610 P2_BalSwCell157 "电池包2的电芯157均衡状态";
CM_ SG_ 2556952610 P2_BalSwCell158 "电池包2的电芯158均衡状态";
CM_ SG_ 2556952610 P2_BalSwCell159 "电池包2的电芯159均衡状态";
CM_ SG_ 2556952610 P2_BalSwCell160 "电池包2的电芯160均衡状态";
CM_ SG_ 2557018146 P2_CellVoltage161 "电池包2的单体电压161";
CM_ SG_ 2557018146 P2_CellVoltage162 "电池包2的单体电压162";
CM_ SG_ 2557018146 P2_CellVoltage163 "电池包2的单体电压163";
CM_ SG_ 2557018146 P2_CellVoltage164 "电池包2的单体电压164";
CM_ SG_ 2557018146 P2_BalSwCell161 "电池包2的电芯161均衡状态";
CM_ SG_ 2557018146 P2_BalSwCell162 "电池包2的电芯162均衡状态";
CM_ SG_ 2557018146 P2_BalSwCell163 "电池包2的电芯163均衡状态";
CM_ SG_ 2557018146 P2_BalSwCell164 "电池包2的电芯164均衡状态";
CM_ SG_ 2557083682 P2_CellVoltage165 "电池包2的单体电压165";
CM_ SG_ 2557083682 P2_CellVoltage166 "电池包2的单体电压166";
CM_ SG_ 2557083682 P2_CellVoltage167 "电池包2的单体电压167";
CM_ SG_ 2557083682 P2_CellVoltage168 "电池包2的单体电压168";
CM_ SG_ 2557083682 P2_BalSwCell165 "电池包2的电芯165均衡状态";
CM_ SG_ 2557083682 P2_BalSwCell166 "电池包2的电芯166均衡状态";
CM_ SG_ 2557083682 P2_BalSwCell167 "电池包2的电芯167均衡状态";
CM_ SG_ 2557083682 P2_BalSwCell168 "电池包2的电芯168均衡状态";
CM_ SG_ 2557149218 P2_CellVoltage169 "电池包2的单体电压169";
CM_ SG_ 2557149218 P2_CellVoltage170 "电池包2的单体电压170";
CM_ SG_ 2557149218 P2_CellVoltage171 "电池包2的单体电压171";
CM_ SG_ 2557149218 P2_CellVoltage172 "电池包2的单体电压172";
CM_ SG_ 2557149218 P2_BalSwCell169 "电池包2的电芯169均衡状态";
CM_ SG_ 2557149218 P2_BalSwCell170 "电池包2的电芯170均衡状态";
CM_ SG_ 2557149218 P2_BalSwCell171 "电池包2的电芯171均衡状态";
CM_ SG_ 2557149218 P2_BalSwCell172 "电池包2的电芯172均衡状态";
CM_ SG_ 2557214754 P2_CellVoltage173 "电池包2的单体电压173";
CM_ SG_ 2557214754 P2_CellVoltage174 "电池包2的单体电压174";
CM_ SG_ 2557214754 P2_CellVoltage175 "电池包2的单体电压175";
CM_ SG_ 2557214754 P2_CellVoltage176 "电池包2的单体电压176";
CM_ SG_ 2557214754 P2_BalSwCell173 "电池包2的电芯173均衡状态";
CM_ SG_ 2557214754 P2_BalSwCell174 "电池包2的电芯174均衡状态";
CM_ SG_ 2557214754 P2_BalSwCell175 "电池包2的电芯175均衡状态";
CM_ SG_ 2557214754 P2_BalSwCell176 "电池包2的电芯176均衡状态";
CM_ SG_ 2557280290 P2_CellVoltage177 "电池包2的单体电压177";
CM_ SG_ 2557280290 P2_CellVoltage178 "电池包2的单体电压178";
CM_ SG_ 2557280290 P2_CellVoltage179 "电池包2的单体电压179";
CM_ SG_ 2557280290 P2_CellVoltage180 "电池包2的单体电压180";
CM_ SG_ 2557280290 P2_BalSwCell177 "电池包2的电芯177均衡状态";
CM_ SG_ 2557280290 P2_BalSwCell178 "电池包2的电芯178均衡状态";
CM_ SG_ 2557280290 P2_BalSwCell179 "电池包2的电芯179均衡状态";
CM_ SG_ 2557280290 P2_BalSwCell180 "电池包2的电芯180均衡状态";
CM_ SG_ 2557345826 P2_CellVoltage181 "电池包2的单体电压181";
CM_ SG_ 2557345826 P2_CellVoltage182 "电池包2的单体电压182";
CM_ SG_ 2557345826 P2_CellVoltage183 "电池包2的单体电压183";
CM_ SG_ 2557345826 P2_CellVoltage184 "电池包2的单体电压184";
CM_ SG_ 2557345826 P2_BalSwCell181 "电池包2的电芯181均衡状态";
CM_ SG_ 2557345826 P2_BalSwCell182 "电池包2的电芯182均衡状态";
CM_ SG_ 2557345826 P2_BalSwCell183 "电池包2的电芯183均衡状态";
CM_ SG_ 2557345826 P2_BalSwCell184 "电池包2的电芯184均衡状态";
CM_ SG_ 2557411362 P2_CellVoltage185 "电池包2的单体电压185";
CM_ SG_ 2557411362 P2_CellVoltage186 "电池包2的单体电压186";
CM_ SG_ 2557411362 P2_CellVoltage187 "电池包2的单体电压187";
CM_ SG_ 2557411362 P2_CellVoltage188 "电池包2的单体电压188";
CM_ SG_ 2557411362 P2_BalSwCell185 "电池包2的电芯185均衡状态";
CM_ SG_ 2557411362 P2_BalSwCell186 "电池包2的电芯186均衡状态";
CM_ SG_ 2557411362 P2_BalSwCell187 "电池包2的电芯187均衡状态";
CM_ SG_ 2557411362 P2_BalSwCell188 "电池包2的电芯188均衡状态";
CM_ SG_ 2557476898 P2_CellVoltage189 "电池包2的单体电压189";
CM_ SG_ 2557476898 P2_CellVoltage190 "电池包2的单体电压190";
CM_ SG_ 2557476898 P2_CellVoltage191 "电池包2的单体电压191";
CM_ SG_ 2557476898 P2_CellVoltage192 "电池包2的单体电压192";
CM_ SG_ 2557476898 P2_BalSwCell189 "电池包2的电芯189均衡状态";
CM_ SG_ 2557476898 P2_BalSwCell190 "电池包2的电芯190均衡状态";
CM_ SG_ 2557476898 P2_BalSwCell191 "电池包2的电芯191均衡状态";
CM_ SG_ 2557476898 P2_BalSwCell192 "电池包2的电芯192均衡状态";
CM_ SG_ 2558525474 P2_CellTemp1 "电池包2的单体温度1";
CM_ SG_ 2558525474 P2_CellTemp2 "电池包2的单体温度2";
CM_ SG_ 2558525474 P2_CellTemp3 "电池包2的单体温度3";
CM_ SG_ 2558525474 P2_CellTemp4 "电池包2的单体温度4";
CM_ SG_ 2558525474 P2_CellTemp5 "电池包2的单体温度5";
CM_ SG_ 2558591010 P2_CellTemp6 "电池包2的单体温度6";
CM_ SG_ 2558591010 P2_CellTemp7 "电池包2的单体温度7";
CM_ SG_ 2558591010 P2_CellTemp8 "电池包2的单体温度8";
CM_ SG_ 2558591010 P2_CellTemp9 "电池包2的单体温度9";
CM_ SG_ 2558591010 P2_CellTemp10 "电池包2的单体温度10";
CM_ SG_ 2558656546 P2_CellTemp11 "电池包2的单体温度11";
CM_ SG_ 2558656546 P2_CellTemp12 "电池包2的单体温度12";
CM_ SG_ 2558656546 P2_CellTemp13 "电池包2的单体温度13";
CM_ SG_ 2558656546 P2_CellTemp14 "电池包2的单体温度14";
CM_ SG_ 2558656546 P2_CellTemp15 "电池包2的单体温度15";
CM_ SG_ 2558722082 P2_CellTemp16 "电池包2的单体温度16";
CM_ SG_ 2558722082 P2_CellTemp17 "电池包2的单体温度17";
CM_ SG_ 2558722082 P2_CellTemp18 "电池包2的单体温度18";
CM_ SG_ 2558722082 P2_CellTemp19 "电池包2的单体温度19";
CM_ SG_ 2558722082 P2_CellTemp20 "电池包2的单体温度20";
CM_ SG_ 2558787618 P2_CellTemp21 "电池包2的单体温度21";
CM_ SG_ 2558787618 P2_CellTemp22 "电池包2的单体温度22";
CM_ SG_ 2558787618 P2_CellTemp23 "电池包2的单体温度23";
CM_ SG_ 2558787618 P2_CellTemp24 "电池包2的单体温度24";
CM_ SG_ 2558787618 P2_CellTemp25 "电池包2的单体温度25";
CM_ SG_ 2558853154 P2_CellTemp26 "电池包2的单体温度26";
CM_ SG_ 2558853154 P2_CellTemp27 "电池包2的单体温度27";
CM_ SG_ 2558853154 P2_CellTemp28 "电池包2的单体温度28";
CM_ SG_ 2558853154 P2_CellTemp29 "电池包2的单体温度29";
CM_ SG_ 2558853154 P2_CellTemp30 "电池包2的单体温度30";
CM_ SG_ 2558918690 P2_CellTemp31 "电池包2的单体温度31";
CM_ SG_ 2558918690 P2_CellTemp32 "电池包2的单体温度32";
CM_ SG_ 2558918690 P2_CellTemp33 "电池包2的单体温度33";
CM_ SG_ 2558918690 P2_CellTemp34 "电池包2的单体温度34";
CM_ SG_ 2558918690 P2_CellTemp35 "电池包2的单体温度35";
CM_ SG_ 2558984226 P2_CellTemp36 "电池包2的单体温度36";
CM_ SG_ 2558984226 P2_CellTemp37 "电池包2的单体温度37";
CM_ SG_ 2558984226 P2_CellTemp38 "电池包2的单体温度38";
CM_ SG_ 2558984226 P2_CellTemp39 "电池包2的单体温度39";
CM_ SG_ 2558984226 P2_CellTemp40 "电池包2的单体温度40";
CM_ SG_ 2559049762 P2_CellTemp41 "电池包2的单体温度41";
CM_ SG_ 2559049762 P2_CellTemp42 "电池包2的单体温度42";
CM_ SG_ 2559049762 P2_CellTemp43 "电池包2的单体温度43";
CM_ SG_ 2559049762 P2_CellTemp44 "电池包2的单体温度44";
CM_ SG_ 2559049762 P2_CellTemp45 "电池包2的单体温度45";
CM_ SG_ 2559115298 P2_CellTemp46 "电池包2的单体温度46";
CM_ SG_ 2559115298 P2_CellTemp47 "电池包2的单体温度47";
CM_ SG_ 2559115298 P2_CellTemp48 "电池包2的单体温度48";
CM_ SG_ 2559115298 P2_CellTemp49 "电池包2的单体温度49";
CM_ SG_ 2559115298 P2_CellTemp50 "电池包2的单体温度50";
CM_ SG_ 2559180834 P2_CellTemp51 "电池包2的单体温度51";
CM_ SG_ 2559180834 P2_CellTemp52 "电池包2的单体温度52";
CM_ SG_ 2559180834 P2_CellTemp53 "电池包2的单体温度53";
CM_ SG_ 2559180834 P2_CellTemp54 "电池包2的单体温度54";
CM_ SG_ 2559180834 P2_CellTemp55 "电池包2的单体温度55";
CM_ SG_ 2559246370 P2_CellTemp56 "电池包2的单体温度56";
CM_ SG_ 2559246370 P2_CellTemp57 "电池包2的单体温度57";
CM_ SG_ 2559246370 P2_CellTemp58 "电池包2的单体温度58";
CM_ SG_ 2559246370 P2_CellTemp59 "电池包2的单体温度59";
CM_ SG_ 2559246370 P2_CellTemp60 "电池包2的单体温度60";
CM_ SG_ 2559311906 P2_CellTemp61 "电池包2的单体温度61";
CM_ SG_ 2559311906 P2_CellTemp62 "电池包2的单体温度62";
CM_ SG_ 2559311906 P2_CellTemp63 "电池包2的单体温度63";
CM_ SG_ 2559311906 P2_CellTemp64 "电池包2的单体温度64";
CM_ SG_ 2559311906 P2_CellTemp65 "电池包2的单体温度65";
CM_ SG_ 2559377442 P2_CellTemp66 "电池包2的单体温度66";
CM_ SG_ 2559377442 P2_CellTemp67 "电池包2的单体温度67";
CM_ SG_ 2559377442 P2_CellTemp68 "电池包2的单体温度68";
CM_ SG_ 2559377442 P2_CellTemp69 "电池包2的单体温度69";
CM_ SG_ 2559377442 P2_CellTemp70 "电池包2的单体温度70";
CM_ SG_ 2559442978 P2_CellTemp71 "电池包2的单体温度71";
CM_ SG_ 2559442978 P2_CellTemp72 "电池包2的单体温度72";
CM_ SG_ 2559442978 P2_CellTemp73 "电池包2的单体温度73";
CM_ SG_ 2559442978 P2_CellTemp74 "电池包2的单体温度74";
CM_ SG_ 2559442978 P2_CellTemp75 "电池包2的单体温度75";
CM_ SG_ 2559508514 P2_CellTemp76 "电池包2的单体温度76";
CM_ SG_ 2559508514 P2_CellTemp77 "电池包2的单体温度77";
CM_ SG_ 2559508514 P2_CellTemp78 "电池包2的单体温度78";
CM_ SG_ 2559508514 P2_CellTemp79 "电池包2的单体温度79";
CM_ SG_ 2559508514 P2_CellTemp80 "电池包2的单体温度80";
CM_ SG_ 2559574050 P2_CellTemp81 "电池包2的单体温度81";
CM_ SG_ 2559574050 P2_CellTemp82 "电池包2的单体温度82";
CM_ SG_ 2559574050 P2_CellTemp83 "电池包2的单体温度83";
CM_ SG_ 2559574050 P2_CellTemp84 "电池包2的单体温度84";
CM_ SG_ 2559574050 P2_CellTemp85 "电池包2的单体温度85";
CM_ SG_ 2559639586 P2_CellTemp86 "电池包2的单体温度86";
CM_ SG_ 2559639586 P2_CellTemp87 "电池包2的单体温度87";
CM_ SG_ 2559639586 P2_CellTemp88 "电池包2的单体温度88";
CM_ SG_ 2559639586 P2_CellTemp89 "电池包2的单体温度89";
CM_ SG_ 2559639586 P2_CellTemp90 "电池包2的单体温度90";
CM_ SG_ 2559705122 P2_CellTemp91 "电池包2的单体温度91";
CM_ SG_ 2559705122 P2_CellTemp92 "电池包2的单体温度92";
CM_ SG_ 2559705122 P2_CellTemp93 "电池包2的单体温度93";
CM_ SG_ 2559705122 P2_CellTemp94 "电池包2的单体温度94";
CM_ SG_ 2559705122 P2_CellTemp95 "电池包2的单体温度95";
CM_ SG_ 2559770658 P2_CellTemp96 "电池包2的单体温度96";
CM_ SG_ 2559770658 P2_CellTemp97 "电池包2的单体温度97";
CM_ SG_ 2559770658 P2_CellTemp98 "电池包2的单体温度98";
CM_ SG_ 2559770658 P2_CellTemp99 "电池包2的单体温度99";
CM_ SG_ 2559770658 P2_CellTemp100 "电池包2的单体温度100";
CM_ SG_ 2559836194 P2_CellTemp101 "电池包2的单体温度101";
CM_ SG_ 2559836194 P2_CellTemp102 "电池包2的单体温度102";
CM_ SG_ 2559836194 P2_CellTemp103 "电池包2的单体温度103";
CM_ SG_ 2559836194 P2_CellTemp104 "电池包2的单体温度104";
CM_ SG_ 2559836194 P2_CellTemp105 "电池包2的单体温度105";
CM_ SG_ 2559901730 P2_CellTemp106 "电池包2的单体温度106";
CM_ SG_ 2559901730 P2_CellTemp107 "电池包2的单体温度107";
CM_ SG_ 2559901730 P2_CellTemp108 "电池包2的单体温度108";
CM_ SG_ 2559901730 P2_CellTemp109 "电池包2的单体温度109";
CM_ SG_ 2559901730 P2_CellTemp110 "电池包2的单体温度110";
CM_ SG_ 2559967266 P2_CellTemp111 "电池包2的单体温度111";
CM_ SG_ 2559967266 P2_CellTemp112 "电池包2的单体温度112";
CM_ SG_ 2559967266 P2_CellTemp113 "电池包2的单体温度113";
CM_ SG_ 2559967266 P2_CellTemp114 "电池包2的单体温度114";
CM_ SG_ 2559967266 P2_CellTemp115 "电池包2的单体温度115";
CM_ SG_ 2560032802 P2_CellTemp116 "电池包2的单体温度116";
CM_ SG_ 2560032802 P2_CellTemp117 "电池包2的单体温度117";
CM_ SG_ 2560032802 P2_CellTemp118 "电池包2的单体温度118";
CM_ SG_ 2560032802 P2_CellTemp119 "电池包2的单体温度119";
CM_ SG_ 2560032802 P2_CellTemp120 "电池包2的单体温度120";
CM_ SG_ 2560098338 P2_CellTemp121 "电池包2的单体温度121";
CM_ SG_ 2560098338 P2_CellTemp122 "电池包2的单体温度122";
CM_ SG_ 2560098338 P2_CellTemp123 "电池包2的单体温度123";
CM_ SG_ 2560098338 P2_CellTemp124 "电池包2的单体温度124";
CM_ SG_ 2560098338 P2_CellTemp125 "电池包2的单体温度125";
CM_ SG_ 2560163874 P2_CellTemp126 "电池包2的单体温度126";
CM_ SG_ 2560163874 P2_CellTemp127 "电池包2的单体温度127";
CM_ SG_ 2560163874 P2_CellTemp128 "电池包2的单体温度128";
CM_ SG_ 2560163874 P2_CellTemp129 "电池包2的单体温度129";
CM_ SG_ 2560163874 P2_CellTemp130 "电池包2的单体温度130";
CM_ SG_ 2560229410 P2_CellTemp131 "电池包2的单体温度131";
CM_ SG_ 2560229410 P2_CellTemp132 "电池包2的单体温度132";
CM_ SG_ 2560229410 P2_CellTemp133 "电池包2的单体温度133";
CM_ SG_ 2560229410 P2_CellTemp134 "电池包2的单体温度134";
CM_ SG_ 2560229410 P2_CellTemp135 "电池包2的单体温度135";
CM_ SG_ 2560294946 P2_CellTemp136 "电池包2的单体温度136";
CM_ SG_ 2560294946 P2_CellTemp137 "电池包2的单体温度137";
CM_ SG_ 2560294946 P2_CellTemp138 "电池包2的单体温度138";
CM_ SG_ 2560294946 P2_CellTemp139 "电池包2的单体温度139";
CM_ SG_ 2560294946 P2_CellTemp140 "电池包2的单体温度140";
CM_ SG_ 2560360482 P2_CellTemp141 "电池包2的单体温度141";
CM_ SG_ 2560360482 P2_CellTemp142 "电池包2的单体温度142";
CM_ SG_ 2560360482 P2_CellTemp143 "电池包2的单体温度143";
CM_ SG_ 2560360482 P2_CellTemp144 "电池包2的单体温度144";
CM_ SG_ 2560360482 P2_CellTemp145 "电池包2的单体温度145";
CM_ SG_ 2560426018 P2_CellTemp146 "电池包2的单体温度146";
CM_ SG_ 2560426018 P2_CellTemp147 "电池包2的单体温度147";
CM_ SG_ 2560426018 P2_CellTemp148 "电池包2的单体温度148";
CM_ SG_ 2560426018 P2_CellTemp149 "电池包2的单体温度149";
CM_ SG_ 2560426018 P2_CellTemp150 "电池包2的单体温度150";
CM_ SG_ 2560491554 P2_CellTemp151 "电池包2的单体温度151";
CM_ SG_ 2560491554 P2_CellTemp152 "电池包2的单体温度152";
CM_ SG_ 2560491554 P2_CellTemp153 "电池包2的单体温度153";
CM_ SG_ 2560491554 P2_CellTemp154 "电池包2的单体温度154";
CM_ SG_ 2560491554 P2_CellTemp155 "电池包2的单体温度155";
CM_ SG_ 2560557090 P2_CellTemp156 "电池包2的单体温度156";
CM_ SG_ 2560557090 P2_CellTemp157 "电池包2的单体温度157";
CM_ SG_ 2560557090 P2_CellTemp158 "电池包2的单体温度158";
CM_ SG_ 2560557090 P2_CellTemp159 "电池包2的单体温度159";
CM_ SG_ 2560557090 P2_CellTemp160 "电池包2的单体温度160";
CM_ SG_ 2560622626 P2_CellTemp161 "电池包2的单体温度161";
CM_ SG_ 2560622626 P2_CellTemp162 "电池包2的单体温度162";
CM_ SG_ 2560622626 P2_CellTemp163 "电池包2的单体温度163";
CM_ SG_ 2560622626 P2_CellTemp164 "电池包2的单体温度164";
CM_ SG_ 2560622626 P2_CellTemp165 "电池包2的单体温度165";
CM_ SG_ 2560688162 P2_CellTemp166 "电池包2的单体温度166";
CM_ SG_ 2560688162 P2_CellTemp167 "电池包2的单体温度167";
CM_ SG_ 2560688162 P2_CellTemp168 "电池包2的单体温度168";
CM_ SG_ 2560688162 P2_CellTemp169 "电池包2的单体温度169";
CM_ SG_ 2560688162 P2_CellTemp170 "电池包2的单体温度170";
CM_ SG_ 2560753698 P2_CellTemp171 "电池包2的单体温度171";
CM_ SG_ 2560753698 P2_CellTemp172 "电池包2的单体温度172";
CM_ SG_ 2560753698 P2_CellTemp173 "电池包2的单体温度173";
CM_ SG_ 2560753698 P2_CellTemp174 "电池包2的单体温度174";
CM_ SG_ 2560753698 P2_CellTemp175 "电池包2的单体温度175";
CM_ SG_ 2560819234 P2_CellTemp176 "电池包2的单体温度176";
CM_ SG_ 2560819234 P2_CellTemp177 "电池包2的单体温度177";
CM_ SG_ 2560819234 P2_CellTemp178 "电池包2的单体温度178";
CM_ SG_ 2560819234 P2_CellTemp179 "电池包2的单体温度179";
CM_ SG_ 2560819234 P2_CellTemp180 "电池包2的单体温度180";
CM_ SG_ 2560884770 P2_CellTemp181 "电池包2的单体温度181";
CM_ SG_ 2560884770 P2_CellTemp182 "电池包2的单体温度182";
CM_ SG_ 2560884770 P2_CellTemp183 "电池包2的单体温度183";
CM_ SG_ 2560884770 P2_CellTemp184 "电池包2的单体温度184";
CM_ SG_ 2560884770 P2_CellTemp185 "电池包2的单体温度185";
CM_ SG_ 2560950306 P2_CellTemp186 "电池包2的单体温度186";
CM_ SG_ 2560950306 P2_CellTemp187 "电池包2的单体温度187";
CM_ SG_ 2560950306 P2_CellTemp188 "电池包2的单体温度188";
CM_ SG_ 2560950306 P2_CellTemp189 "电池包2的单体温度189";
CM_ SG_ 2560950306 P2_CellTemp190 "电池包2的单体温度190";
CM_ SG_ 2561015842 P2_CellTemp191 "电池包2的单体温度191";
CM_ SG_ 2561015842 P2_CellTemp192 "电池包2的单体温度192";
CM_ SG_ 2561015842 P2_DatLen16DbgInfo1 "长度为16的调试信息1";
CM_ SG_ 2561015842 P2_DatLen16DbgInfo2 "长度为16的调试信息2";
CM_ SG_ 2561015842 P2_DatLen16DbgInfo3 "长度为16的调试信息3";
CM_ SG_ 2561015842 P2_DatLen16DbgInfo4 "长度为16的调试信息4";
CM_ SG_ 2550399027 P3_BMSPwrSuplVlt1 "电池包3的BMS供电电源电压1";
CM_ SG_ 2550399027 P3_BMSPwrSuplVlt2 "电池包3的BMS供电电源电压2";
CM_ SG_ 2550399027 P3_ChrgStationAuxPwrSuplVlt "电池包3的快充桩A+电压";
CM_ SG_ 2550399027 P3_BMSKL15ON "电池包3的BMS唤醒信号";
CM_ SG_ 2550399027 P3_DCStepState "电池包3的充电状态机";
CM_ SG_ 2550399027 P3_ExtLvWakeup_28VOnly "电池包3的外部唤醒";
BA_DEF_  "DBName" STRING ;
BA_DEF_  "BusType" STRING ;
BA_DEF_ BO_  "GenMsgSendType" ENUM  "Cyclic","IfActive","Event";
BA_DEF_ BO_  "GenMsgCycleTime" INT 0 5000;
BA_DEF_ BO_  "VFrameFormat" ENUM  "StandardCAN","ExtendedCAN","reserved","reserved","reserved","reserved","reserved","reserved","reserved","reserved","reserved","reserved","reserved","reserved","StandardCAN_FD","ExtendedCAN_FD";
BA_DEF_ SG_  "GenSigSendType" ENUM  "Cyclic","OnWrite","OnChange","NoSigSendType";
BA_DEF_DEF_  "GenMsgSendType" "Cyclic";
BA_DEF_DEF_  "GenMsgCycleTime" 0;
BA_DEF_DEF_  "GenSigSendType" "Cyclic";
BA_DEF_DEF_  "VFrameFormat" "ExtendedCAN";
BA_ "BusType" "CAN";
BA_ "DBName" "PCAN";
BA_ "GenMsgCycleTime" BO_ 2550398993 500;
BA_ "GenMsgCycleTime" BO_ 2550464529 500;
BA_ "GenMsgCycleTime" BO_ 2550530065 500;
BA_ "GenMsgCycleTime" BO_ 2550595601 500;
BA_ "GenMsgCycleTime" BO_ 2550661137 500;
BA_ "GenMsgCycleTime" BO_ 2550726673 500;
BA_ "GenMsgCycleTime" BO_ 2550792209 500;
BA_ "GenMsgCycleTime" BO_ 2550857745 500;
BA_ "GenMsgCycleTime" BO_ 2550923281 500;
BA_ "GenMsgCycleTime" BO_ 2550988817 1000;
BA_ "GenMsgCycleTime" BO_ 2552299537 1000;
BA_ "GenMsgCycleTime" BO_ 2554396689 1000;
BA_ "GenMsgCycleTime" BO_ 2554462225 1000;
BA_ "GenMsgCycleTime" BO_ 2554527761 1000;
BA_ "GenMsgCycleTime" BO_ 2554593297 1000;
BA_ "GenMsgCycleTime" BO_ 2554658833 1000;
BA_ "GenMsgCycleTime" BO_ 2554724369 1000;
BA_ "GenMsgCycleTime" BO_ 2554789905 1000;
BA_ "GenMsgCycleTime" BO_ 2554855441 1000;
BA_ "GenMsgCycleTime" BO_ 2554920977 1000;
BA_ "GenMsgCycleTime" BO_ 2554986513 1000;
BA_ "GenMsgCycleTime" BO_ 2555052049 1000;
BA_ "GenMsgCycleTime" BO_ 2555117585 1000;
BA_ "GenMsgCycleTime" BO_ 2555183121 1000;
BA_ "GenMsgCycleTime" BO_ 2555248657 1000;
BA_ "GenMsgCycleTime" BO_ 2555314193 1000;
BA_ "GenMsgCycleTime" BO_ 2555379729 1000;
BA_ "GenMsgCycleTime" BO_ 2555445265 1000;
BA_ "GenMsgCycleTime" BO_ 2555510801 1000;
BA_ "GenMsgCycleTime" BO_ 2555576337 1000;
BA_ "GenMsgCycleTime" BO_ 2555641873 1000;
BA_ "GenMsgCycleTime" BO_ 2555707409 1000;
BA_ "GenMsgCycleTime" BO_ 2555772945 1000;
BA_ "GenMsgCycleTime" BO_ 2555838481 1000;
BA_ "GenMsgCycleTime" BO_ 2555904017 1000;
BA_ "GenMsgCycleTime" BO_ 2555969553 1000;
BA_ "GenMsgCycleTime" BO_ 2556035089 1000;
BA_ "GenMsgCycleTime" BO_ 2556100625 1000;
BA_ "GenMsgCycleTime" BO_ 2556166161 1000;
BA_ "GenMsgCycleTime" BO_ 2556231697 1000;
BA_ "GenMsgCycleTime" BO_ 2556297233 1000;
BA_ "GenMsgCycleTime" BO_ 2556362769 1000;
BA_ "GenMsgCycleTime" BO_ 2556428305 1000;
BA_ "GenMsgCycleTime" BO_ 2556493841 1000;
BA_ "GenMsgCycleTime" BO_ 2556559377 1000;
BA_ "GenMsgCycleTime" BO_ 2556624913 1000;
BA_ "GenMsgCycleTime" BO_ 2556690449 1000;
BA_ "GenMsgCycleTime" BO_ 2556755985 1000;
BA_ "GenMsgCycleTime" BO_ 2556821521 1000;
BA_ "GenMsgCycleTime" BO_ 2556887057 1000;
BA_ "GenMsgCycleTime" BO_ 2556952593 1000;
BA_ "GenMsgCycleTime" BO_ 2557018129 1000;
BA_ "GenMsgCycleTime" BO_ 2557083665 1000;
BA_ "GenMsgCycleTime" BO_ 2557149201 1000;
BA_ "GenMsgCycleTime" BO_ 2557214737 1000;
BA_ "GenMsgCycleTime" BO_ 2557280273 1000;
BA_ "GenMsgCycleTime" BO_ 2557345809 1000;
BA_ "GenMsgCycleTime" BO_ 2557411345 1000;
BA_ "GenMsgCycleTime" BO_ 2557476881 1000;
BA_ "GenMsgCycleTime" BO_ 2558525457 1000;
BA_ "GenMsgCycleTime" BO_ 2558590993 1000;
BA_ "GenMsgCycleTime" BO_ 2558656529 1000;
BA_ "GenMsgCycleTime" BO_ 2558722065 1000;
BA_ "GenMsgCycleTime" BO_ 2558787601 1000;
BA_ "GenMsgCycleTime" BO_ 2558853137 1000;
BA_ "GenMsgCycleTime" BO_ 2558918673 1000;
BA_ "GenMsgCycleTime" BO_ 2558984209 1000;
BA_ "GenMsgCycleTime" BO_ 2559049745 1000;
BA_ "GenMsgCycleTime" BO_ 2559115281 1000;
BA_ "GenMsgCycleTime" BO_ 2559180817 1000;
BA_ "GenMsgCycleTime" BO_ 2559246353 1000;
BA_ "GenMsgCycleTime" BO_ 2559311889 1000;
BA_ "GenMsgCycleTime" BO_ 2559377425 1000;
BA_ "GenMsgCycleTime" BO_ 2559442961 1000;
BA_ "GenMsgCycleTime" BO_ 2559508497 1000;
BA_ "GenMsgCycleTime" BO_ 2559574033 1000;
BA_ "GenMsgCycleTime" BO_ 2559639569 1000;
BA_ "GenMsgCycleTime" BO_ 2559705105 1000;
BA_ "GenMsgCycleTime" BO_ 2559770641 1000;
BA_ "GenMsgCycleTime" BO_ 2559836177 1000;
BA_ "GenMsgCycleTime" BO_ 2559901713 1000;
BA_ "GenMsgCycleTime" BO_ 2559967249 1000;
BA_ "GenMsgCycleTime" BO_ 2560032785 1000;
BA_ "GenMsgCycleTime" BO_ 2560098321 1000;
BA_ "GenMsgCycleTime" BO_ 2560163857 1000;
BA_ "GenMsgCycleTime" BO_ 2560229393 1000;
BA_ "GenMsgCycleTime" BO_ 2560294929 1000;
BA_ "GenMsgCycleTime" BO_ 2560360465 1000;
BA_ "GenMsgCycleTime" BO_ 2560426001 1000;
BA_ "GenMsgCycleTime" BO_ 2560491537 1000;
BA_ "GenMsgCycleTime" BO_ 2560557073 1000;
BA_ "GenMsgCycleTime" BO_ 2560622609 1000;
BA_ "GenMsgCycleTime" BO_ 2560688145 1000;
BA_ "GenMsgCycleTime" BO_ 2560753681 1000;
BA_ "GenMsgCycleTime" BO_ 2560819217 1000;
BA_ "GenMsgCycleTime" BO_ 2560884753 1000;
BA_ "GenMsgCycleTime" BO_ 2560950289 1000;
BA_ "GenMsgCycleTime" BO_ 2561015825 1000;
BA_ "GenMsgCycleTime" BO_ 2550399010 500;
BA_ "GenMsgCycleTime" BO_ 2550464546 500;
BA_ "GenMsgCycleTime" BO_ 2550530082 500;
BA_ "GenMsgCycleTime" BO_ 2550595618 500;
BA_ "GenMsgCycleTime" BO_ 2550661154 500;
BA_ "GenMsgCycleTime" BO_ 2550726690 500;
BA_ "GenMsgCycleTime" BO_ 2550792226 500;
BA_ "GenMsgCycleTime" BO_ 2550857762 500;
BA_ "GenMsgCycleTime" BO_ 2550923298 500;
BA_ "GenMsgCycleTime" BO_ 2550988834 1000;
BA_ "GenMsgCycleTime" BO_ 2552299554 1000;
BA_ "GenMsgCycleTime" BO_ 2554396706 1000;
BA_ "GenMsgCycleTime" BO_ 2554462242 1000;
BA_ "GenMsgCycleTime" BO_ 2554527778 1000;
BA_ "GenMsgCycleTime" BO_ 2554593314 1000;
BA_ "GenMsgCycleTime" BO_ 2554658850 1000;
BA_ "GenMsgCycleTime" BO_ 2554724386 1000;
BA_ "GenMsgCycleTime" BO_ 2554789922 1000;
BA_ "GenMsgCycleTime" BO_ 2554855458 1000;
BA_ "GenMsgCycleTime" BO_ 2554920994 1000;
BA_ "GenMsgCycleTime" BO_ 2554986530 1000;
BA_ "GenMsgCycleTime" BO_ 2555052066 1000;
BA_ "GenMsgCycleTime" BO_ 2555117602 1000;
BA_ "GenMsgCycleTime" BO_ 2555183138 1000;
BA_ "GenMsgCycleTime" BO_ 2555248674 1000;
BA_ "GenMsgCycleTime" BO_ 2555314210 1000;
BA_ "GenMsgCycleTime" BO_ 2555379746 1000;
BA_ "GenMsgCycleTime" BO_ 2555445282 1000;
BA_ "GenMsgCycleTime" BO_ 2555510818 1000;
BA_ "GenMsgCycleTime" BO_ 2555576354 1000;
BA_ "GenMsgCycleTime" BO_ 2555641890 1000;
BA_ "GenMsgCycleTime" BO_ 2555707426 1000;
BA_ "GenMsgCycleTime" BO_ 2555772962 1000;
BA_ "GenMsgCycleTime" BO_ 2555838498 1000;
BA_ "GenMsgCycleTime" BO_ 2555904034 1000;
BA_ "GenMsgCycleTime" BO_ 2555969570 1000;
BA_ "GenMsgCycleTime" BO_ 2556035106 1000;
BA_ "GenMsgCycleTime" BO_ 2556100642 1000;
BA_ "GenMsgCycleTime" BO_ 2556166178 1000;
BA_ "GenMsgCycleTime" BO_ 2556231714 1000;
BA_ "GenMsgCycleTime" BO_ 2556297250 1000;
BA_ "GenMsgCycleTime" BO_ 2556362786 1000;
BA_ "GenMsgCycleTime" BO_ 2556428322 1000;
BA_ "GenMsgCycleTime" BO_ 2556493858 1000;
BA_ "GenMsgCycleTime" BO_ 2556559394 1000;
BA_ "GenMsgCycleTime" BO_ 2556624930 1000;
BA_ "GenMsgCycleTime" BO_ 2556690466 1000;
BA_ "GenMsgCycleTime" BO_ 2556756002 1000;
BA_ "GenMsgCycleTime" BO_ 2556821538 1000;
BA_ "GenMsgCycleTime" BO_ 2556887074 1000;
BA_ "GenMsgCycleTime" BO_ 2556952610 1000;
BA_ "GenMsgCycleTime" BO_ 2557018146 1000;
BA_ "GenMsgCycleTime" BO_ 2557083682 1000;
BA_ "GenMsgCycleTime" BO_ 2557149218 1000;
BA_ "GenMsgCycleTime" BO_ 2557214754 1000;
BA_ "GenMsgCycleTime" BO_ 2557280290 1000;
BA_ "GenMsgCycleTime" BO_ 2557345826 1000;
BA_ "GenMsgCycleTime" BO_ 2557411362 1000;
BA_ "GenMsgCycleTime" BO_ 2557476898 1000;
BA_ "GenMsgCycleTime" BO_ 2558525474 1000;
BA_ "GenMsgCycleTime" BO_ 2558591010 1000;
BA_ "GenMsgCycleTime" BO_ 2558656546 1000;
BA_ "GenMsgCycleTime" BO_ 2558722082 1000;
BA_ "GenMsgCycleTime" BO_ 2558787618 1000;
BA_ "GenMsgCycleTime" BO_ 2558853154 1000;
BA_ "GenMsgCycleTime" BO_ 2558918690 1000;
BA_ "GenMsgCycleTime" BO_ 2558984226 1000;
BA_ "GenMsgCycleTime" BO_ 2559049762 1000;
BA_ "GenMsgCycleTime" BO_ 2559115298 1000;
BA_ "GenMsgCycleTime" BO_ 2559180834 1000;
BA_ "GenMsgCycleTime" BO_ 2559246370 1000;
BA_ "GenMsgCycleTime" BO_ 2559311906 1000;
BA_ "GenMsgCycleTime" BO_ 2559377442 1000;
BA_ "GenMsgCycleTime" BO_ 2559442978 1000;
BA_ "GenMsgCycleTime" BO_ 2559508514 1000;
BA_ "GenMsgCycleTime" BO_ 2559574050 1000;
BA_ "GenMsgCycleTime" BO_ 2559639586 1000;
BA_ "GenMsgCycleTime" BO_ 2559705122 1000;
BA_ "GenMsgCycleTime" BO_ 2559770658 1000;
BA_ "GenMsgCycleTime" BO_ 2559836194 1000;
BA_ "GenMsgCycleTime" BO_ 2559901730 1000;
BA_ "GenMsgCycleTime" BO_ 2559967266 1000;
BA_ "GenMsgCycleTime" BO_ 2560032802 1000;
BA_ "GenMsgCycleTime" BO_ 2560098338 1000;
BA_ "GenMsgCycleTime" BO_ 2560163874 1000;
BA_ "GenMsgCycleTime" BO_ 2560229410 1000;
BA_ "GenMsgCycleTime" BO_ 2560294946 1000;
BA_ "GenMsgCycleTime" BO_ 2560360482 1000;
BA_ "GenMsgCycleTime" BO_ 2560426018 1000;
BA_ "GenMsgCycleTime" BO_ 2560491554 1000;
BA_ "GenMsgCycleTime" BO_ 2560557090 1000;
BA_ "GenMsgCycleTime" BO_ 2560622626 1000;
BA_ "GenMsgCycleTime" BO_ 2560688162 1000;
BA_ "GenMsgCycleTime" BO_ 2560753698 1000;
BA_ "GenMsgCycleTime" BO_ 2560819234 1000;
BA_ "GenMsgCycleTime" BO_ 2560884770 1000;
BA_ "GenMsgCycleTime" BO_ 2560950306 1000;
BA_ "GenMsgCycleTime" BO_ 2561015842 1000;
BA_ "GenMsgCycleTime" BO_ 2550399027 500;
VAL_ 2550398993 P1_BMSKL15ON 01 "On" 00 "Off" ;
VAL_ 2550530065 P1_PackDschrgPwrStat 02 "鎸佺画鏀剧數鍔熺巼" 01 "30s鏀剧數鍔熺巼" 00 "10s鏀剧數鍔熺巼" ;
VAL_ 2550530065 P1_PackChrgPwrStat 02 "鎸佺画鍏呯數鍔熺巼" 01 "30s鍏呯數鍔熺巼" 00 "10s鍏呯數鍔熺巼" ;
VAL_ 2550595601 P1_ChrgrCplrStat 01 "Connected" 00 "Disconnected" ;
VAL_ 2550595601 P1_HVBattChrgSysStatus 04 "Aborted" 03 "Complete" 02 "Active" 01 "Initialization" 00 "Default" ;
VAL_ 2550857745 P1_CellOverVoltage 03 "Level 3" 02 "Level 2" 01 "Level 1" 00 "No Fault" ;
VAL_ 2550857745 P1_CellUnderVoltage 03 "Level 3" 02 "Level 2" 01 "Level 1" 00 "No Fault" ;
VAL_ 2550857745 P1_CellVoltageDiffHi 01 "Fault" 00 "No Fault" ;
VAL_ 2550857745 P1_PackOverVoltage 03 "Level 3" 02 "Level 2" 01 "Level 1" 00 "No Fault" ;
VAL_ 2550857745 P1_PackUnderVoltage 03 "Level 3" 02 "Level 2" 01 "Level 1" 00 "No Fault" ;
VAL_ 2550857745 P1_CellOverTemp 03 "Level 3" 02 "Level 2" 01 "Level 1" 00 "No Fault" ;
VAL_ 2550857745 P1_CellTempLow 01 "Fault" 00 "No Fault" ;
VAL_ 2550857745 P1_CellTempDiffHi 01 "Fault" 00 "No Fault" ;
VAL_ 2550857745 P1_PackDschrgCrntHi 03 "Level 3" 02 "Level 2" 01 "Level 1" 00 "No Fault" ;
VAL_ 2550857745 P1_PackChrgCrntHi 03 "Level 3" 02 "Level 2" 01 "Level 1" 00 "No Fault" ;
VAL_ 2550857745 P1_PackCrnSnsr1OffsetHi 01 "Fault" 00 "No Fault" ;
VAL_ 2550857745 P1_HVIsolFlt 03 "Level 3" 02 "Level 2" 01 "Level 1" 00 "No Fault" ;
VAL_ 2550857745 P1_HVILFlt 01 "Fault" 00 "No Fault" ;
VAL_ 2550857745 P1_ThrmlRunaway 01 "Fault" 00 "No Fault" ;
VAL_ 2550857745 P1_CellVoltInvalid 01 "Fault" 00 "No Fault" ;
VAL_ 2550857745 P1_CellTempInvalid 01 "Fault" 00 "No Fault" ;
VAL_ 2550857745 P1_DaisyChainComFlt 01 "Fault" 00 "No Fault" ;
VAL_ 2550857745 P1_PackVoltRatFlt 01 "Fault" 00 "No Fault" ;
VAL_ 2550857745 P1_CrntSnsr1Invalid 01 "Fault" 00 "No Fault" ;
VAL_ 2550857745 P1_CrntSnsr1OOR 01 "Fault" 00 "No Fault" ;
VAL_ 2550857745 P1_CrntSnsr2Invalid 01 "Fault" 00 "No Fault" ;
VAL_ 2550857745 P1_CrntSnsr2OOR 01 "Fault" 00 "No Fault" ;
VAL_ 2550857745 P1_PackCrnSnsr2OffsetHi 01 "Fault" 00 "No Fault" ;
VAL_ 2550857745 P1_OutofEnergy 01 "Fault" 00 "No Fault" ;
VAL_ 2550857745 P1_IsolDetCircErr 01 "Fault" 00 "No Fault" ;
VAL_ 2550857745 P1_HVILCircShortToGND 01 "Fault" 00 "No Fault" ;
VAL_ 2550857745 P1_HVILCircShortToPwr 01 "Fault" 00 "No Fault" ;
VAL_ 2550923281 P1_MainPosCntctrStkClsd 01 "Fault" 00 "No Fault" ;
VAL_ 2550923281 P1_MainPosCntctrStkOpn 01 "Fault" 00 "No Fault" ;
VAL_ 2550923281 P1_MainNegCntctr1StkClsd 01 "Fault" 00 "No Fault" ;
VAL_ 2550923281 P1_MainNegCntctr1StkOpn 01 "Fault" 00 "No Fault" ;
VAL_ 2550923281 P1_MainNegCntctr2StkClsd 01 "Fault" 00 "No Fault" ;
VAL_ 2550923281 P1_MainNegCntctr2StkOpn 01 "Fault" 00 "No Fault" ;
VAL_ 2550923281 P1_PrechargTmOut 01 "Fault" 00 "No Fault" ;
VAL_ 2550923281 P1_PrechrgCrntHi 01 "Fault" 00 "No Fault" ;
VAL_ 2550923281 P1_ChrgCplrPosTempHi 01 "Fault" 00 "No Fault" ;
VAL_ 2550923281 P1_ChrgCplrNegTempHi 01 "Fault" 00 "No Fault" ;
VAL_ 2550923281 P1_BMSPwrSuplVlt1Hi 01 "Fault" 00 "No Fault" ;
VAL_ 2550923281 P1_BMSPwrSuplVlt1Lo 01 "Fault" 00 "No Fault" ;
VAL_ 2550923281 P1_BMSPwrSuplVlt2Hi 01 "Fault" 00 "No Fault" ;
VAL_ 2550923281 P1_BMSPwrSuplVlt2Lo 01 "Fault" 00 "No Fault" ;
VAL_ 2550923281 P1_CntctrCirPwrSuplVltLo 01 "Fault" 00 "No Fault" ;
VAL_ 2550923281 P1_CntctrCirPwrSuplVltHi 01 "Fault" 00 "No Fault" ;
VAL_ 2550923281 P1_CAN1BusOff 01 "Fault" 00 "No Fault" ;
VAL_ 2550923281 P1_CAN1BusTmOut 01 "Fault" 00 "No Fault" ;
VAL_ 2550923281 P1_CAN2BusOff 01 "Fault" 00 "No Fault" ;
VAL_ 2550923281 P1_CAN2BusTmOut 01 "Fault" 00 "No Fault" ;
VAL_ 2550923281 P1_CellBalCircTempHi 01 "Fault" 00 "No Fault" ;
VAL_ 2550923281 P1_ClntInTempHi 01 "Fault" 00 "No Fault" ;
VAL_ 2550923281 P1_ClntOutTempHi 01 "Fault" 00 "No Fault" ;
VAL_ 2550923281 P1_CellExtrmUdrVolt 01 "Fault" 00 "No Fault" ;
VAL_ 2550923281 P1_CellExtrmOvrVolt 01 "Fault" 00 "No Fault" ;
VAL_ 2550923281 P1_Branch1DischrgCrntHi  01 "Fault" 00 "No Fault" ;
VAL_ 2550923281 P1_Branch2DischrgCrntHi  01 "Fault" 00 "No Fault" ;
VAL_ 2550923281 P1_Branch1ChrgCrntHi  01 "Fault" 00 "No Fault" ;
VAL_ 2550923281 P1_Branch2ChrgCrntHi  01 "Fault" 00 "No Fault" ;
VAL_ 2550923281 P1_InitFailed 01 "Fault" 00 "No Fault" ;
VAL_ 2554396689 P1_BalSwCell1 01 "Active" 00 "Inactive" ;
VAL_ 2554396689 P1_BalSwCell2 01 "Active" 00 "Inactive" ;
VAL_ 2554396689 P1_BalSwCell3 01 "Active" 00 "Inactive" ;
VAL_ 2554396689 P1_BalSwCell4 01 "Active" 00 "Inactive" ;
VAL_ 2554462225 P1_BalSwCell5 01 "Active" 00 "Inactive" ;
VAL_ 2554462225 P1_BalSwCell6 01 "Active" 00 "Inactive" ;
VAL_ 2554462225 P1_BalSwCell7 01 "Active" 00 "Inactive" ;
VAL_ 2554462225 P1_BalSwCell8 01 "Active" 00 "Inactive" ;
VAL_ 2554527761 P1_BalSwCell9 01 "Active" 00 "Inactive" ;
VAL_ 2554527761 P1_BalSwCell10 01 "Active" 00 "Inactive" ;
VAL_ 2554527761 P1_BalSwCell11 01 "Active" 00 "Inactive" ;
VAL_ 2554527761 P1_BalSwCell12 01 "Active" 00 "Inactive" ;
VAL_ 2554593297 P1_BalSwCell13 01 "Active" 00 "Inactive" ;
VAL_ 2554593297 P1_BalSwCell14 01 "Active" 00 "Inactive" ;
VAL_ 2554593297 P1_BalSwCell15 01 "Active" 00 "Inactive" ;
VAL_ 2554593297 P1_BalSwCell16 01 "Active" 00 "Inactive" ;
VAL_ 2554658833 P1_BalSwCell17 01 "Active" 00 "Inactive" ;
VAL_ 2554658833 P1_BalSwCell18 01 "Active" 00 "Inactive" ;
VAL_ 2554658833 P1_BalSwCell19 01 "Active" 00 "Inactive" ;
VAL_ 2554658833 P1_BalSwCell20 01 "Active" 00 "Inactive" ;
VAL_ 2554724369 P1_BalSwCell21 01 "Active" 00 "Inactive" ;
VAL_ 2554724369 P1_BalSwCell22 01 "Active" 00 "Inactive" ;
VAL_ 2554724369 P1_BalSwCell23 01 "Active" 00 "Inactive" ;
VAL_ 2554724369 P1_BalSwCell24 01 "Active" 00 "Inactive" ;
VAL_ 2554789905 P1_BalSwCell25 01 "Active" 00 "Inactive" ;
VAL_ 2554789905 P1_BalSwCell26 01 "Active" 00 "Inactive" ;
VAL_ 2554789905 P1_BalSwCell27 01 "Active" 00 "Inactive" ;
VAL_ 2554789905 P1_BalSwCell28 01 "Active" 00 "Inactive" ;
VAL_ 2554855441 P1_BalSwCell29 01 "Active" 00 "Inactive" ;
VAL_ 2554855441 P1_BalSwCell30 01 "Active" 00 "Inactive" ;
VAL_ 2554855441 P1_BalSwCell31 01 "Active" 00 "Inactive" ;
VAL_ 2554855441 P1_BalSwCell32 01 "Active" 00 "Inactive" ;
VAL_ 2554920977 P1_BalSwCell33 01 "Active" 00 "Inactive" ;
VAL_ 2554920977 P1_BalSwCell34 01 "Active" 00 "Inactive" ;
VAL_ 2554920977 P1_BalSwCell35 01 "Active" 00 "Inactive" ;
VAL_ 2554920977 P1_BalSwCell36 01 "Active" 00 "Inactive" ;
VAL_ 2554986513 P1_BalSwCell37 01 "Active" 00 "Inactive" ;
VAL_ 2554986513 P1_BalSwCell38 01 "Active" 00 "Inactive" ;
VAL_ 2554986513 P1_BalSwCell39 01 "Active" 00 "Inactive" ;
VAL_ 2554986513 P1_BalSwCell40 01 "Active" 00 "Inactive" ;
VAL_ 2555052049 P1_BalSwCell41 01 "Active" 00 "Inactive" ;
VAL_ 2555052049 P1_BalSwCell42 01 "Active" 00 "Inactive" ;
VAL_ 2555052049 P1_BalSwCell43 01 "Active" 00 "Inactive" ;
VAL_ 2555052049 P1_BalSwCell44 01 "Active" 00 "Inactive" ;
VAL_ 2555117585 P1_BalSwCell45 01 "Active" 00 "Inactive" ;
VAL_ 2555117585 P1_BalSwCell46 01 "Active" 00 "Inactive" ;
VAL_ 2555117585 P1_BalSwCell47 01 "Active" 00 "Inactive" ;
VAL_ 2555117585 P1_BalSwCell48 01 "Active" 00 "Inactive" ;
VAL_ 2555183121 P1_BalSwCell49 01 "Active" 00 "Inactive" ;
VAL_ 2555183121 P1_BalSwCell50 01 "Active" 00 "Inactive" ;
VAL_ 2555183121 P1_BalSwCell51 01 "Active" 00 "Inactive" ;
VAL_ 2555183121 P1_BalSwCell52 01 "Active" 00 "Inactive" ;
VAL_ 2555248657 P1_BalSwCell53 01 "Active" 00 "Inactive" ;
VAL_ 2555248657 P1_BalSwCell54 01 "Active" 00 "Inactive" ;
VAL_ 2555248657 P1_BalSwCell55 01 "Active" 00 "Inactive" ;
VAL_ 2555248657 P1_BalSwCell56 01 "Active" 00 "Inactive" ;
VAL_ 2555314193 P1_BalSwCell57 01 "Active" 00 "Inactive" ;
VAL_ 2555314193 P1_BalSwCell58 01 "Active" 00 "Inactive" ;
VAL_ 2555314193 P1_BalSwCell59 01 "Active" 00 "Inactive" ;
VAL_ 2555314193 P1_BalSwCell60 01 "Active" 00 "Inactive" ;
VAL_ 2555379729 P1_BalSwCell61 01 "Active" 00 "Inactive" ;
VAL_ 2555379729 P1_BalSwCell62 01 "Active" 00 "Inactive" ;
VAL_ 2555379729 P1_BalSwCell63 01 "Active" 00 "Inactive" ;
VAL_ 2555379729 P1_BalSwCell64 01 "Active" 00 "Inactive" ;
VAL_ 2555445265 P1_BalSwCell65 01 "Active" 00 "Inactive" ;
VAL_ 2555445265 P1_BalSwCell66 01 "Active" 00 "Inactive" ;
VAL_ 2555445265 P1_BalSwCell67 01 "Active" 00 "Inactive" ;
VAL_ 2555445265 P1_BalSwCell68 01 "Active" 00 "Inactive" ;
VAL_ 2555510801 P1_BalSwCell69 01 "Active" 00 "Inactive" ;
VAL_ 2555510801 P1_BalSwCell70 01 "Active" 00 "Inactive" ;
VAL_ 2555510801 P1_BalSwCell71 01 "Active" 00 "Inactive" ;
VAL_ 2555510801 P1_BalSwCell72 01 "Active" 00 "Inactive" ;
VAL_ 2555576337 P1_BalSwCell73 01 "Active" 00 "Inactive" ;
VAL_ 2555576337 P1_BalSwCell74 01 "Active" 00 "Inactive" ;
VAL_ 2555576337 P1_BalSwCell75 01 "Active" 00 "Inactive" ;
VAL_ 2555576337 P1_BalSwCell76 01 "Active" 00 "Inactive" ;
VAL_ 2555641873 P1_BalSwCell77 01 "Active" 00 "Inactive" ;
VAL_ 2555641873 P1_BalSwCell78 01 "Active" 00 "Inactive" ;
VAL_ 2555641873 P1_BalSwCell79 01 "Active" 00 "Inactive" ;
VAL_ 2555641873 P1_BalSwCell80 01 "Active" 00 "Inactive" ;
VAL_ 2555707409 P1_BalSwCell81 01 "Active" 00 "Inactive" ;
VAL_ 2555707409 P1_BalSwCell82 01 "Active" 00 "Inactive" ;
VAL_ 2555707409 P1_BalSwCell83 01 "Active" 00 "Inactive" ;
VAL_ 2555707409 P1_BalSwCell84 01 "Active" 00 "Inactive" ;
VAL_ 2555772945 P1_BalSwCell85 01 "Active" 00 "Inactive" ;
VAL_ 2555772945 P1_BalSwCell86 01 "Active" 00 "Inactive" ;
VAL_ 2555772945 P1_BalSwCell87 01 "Active" 00 "Inactive" ;
VAL_ 2555772945 P1_BalSwCell88 01 "Active" 00 "Inactive" ;
VAL_ 2555838481 P1_BalSwCell89 01 "Active" 00 "Inactive" ;
VAL_ 2555838481 P1_BalSwCell90 01 "Active" 00 "Inactive" ;
VAL_ 2555838481 P1_BalSwCell91 01 "Active" 00 "Inactive" ;
VAL_ 2555838481 P1_BalSwCell92 01 "Active" 00 "Inactive" ;
VAL_ 2555904017 P1_BalSwCell93 01 "Active" 00 "Inactive" ;
VAL_ 2555904017 P1_BalSwCell94 01 "Active" 00 "Inactive" ;
VAL_ 2555904017 P1_BalSwCell95 01 "Active" 00 "Inactive" ;
VAL_ 2555904017 P1_BalSwCell96 01 "Active" 00 "Inactive" ;
VAL_ 2555969553 P1_BalSwCell97 01 "Active" 00 "Inactive" ;
VAL_ 2555969553 P1_BalSwCell98 01 "Active" 00 "Inactive" ;
VAL_ 2555969553 P1_BalSwCell99 01 "Active" 00 "Inactive" ;
VAL_ 2555969553 P1_BalSwCell100 01 "Active" 00 "Inactive" ;
VAL_ 2556035089 P1_BalSwCell101 01 "Active" 00 "Inactive" ;
VAL_ 2556035089 P1_BalSwCell102 01 "Active" 00 "Inactive" ;
VAL_ 2556035089 P1_BalSwCell103 01 "Active" 00 "Inactive" ;
VAL_ 2556035089 P1_BalSwCell104 01 "Active" 00 "Inactive" ;
VAL_ 2556100625 P1_BalSwCell105 01 "Active" 00 "Inactive" ;
VAL_ 2556100625 P1_BalSwCell106 01 "Active" 00 "Inactive" ;
VAL_ 2556100625 P1_BalSwCell107 01 "Active" 00 "Inactive" ;
VAL_ 2556100625 P1_BalSwCell108 01 "Active" 00 "Inactive" ;
VAL_ 2556166161 P1_BalSwCell109 01 "Active" 00 "Inactive" ;
VAL_ 2556166161 P1_BalSwCell110 01 "Active" 00 "Inactive" ;
VAL_ 2556166161 P1_BalSwCell111 01 "Active" 00 "Inactive" ;
VAL_ 2556166161 P1_BalSwCell112 01 "Active" 00 "Inactive" ;
VAL_ 2556231697 P1_BalSwCell113 01 "Active" 00 "Inactive" ;
VAL_ 2556231697 P1_BalSwCell114 01 "Active" 00 "Inactive" ;
VAL_ 2556231697 P1_BalSwCell115 01 "Active" 00 "Inactive" ;
VAL_ 2556231697 P1_BalSwCell116 01 "Active" 00 "Inactive" ;
VAL_ 2556297233 P1_BalSwCell117 01 "Active" 00 "Inactive" ;
VAL_ 2556297233 P1_BalSwCell118 01 "Active" 00 "Inactive" ;
VAL_ 2556297233 P1_BalSwCell119 01 "Active" 00 "Inactive" ;
VAL_ 2556297233 P1_BalSwCell120 01 "Active" 00 "Inactive" ;
VAL_ 2556362769 P1_BalSwCell121 01 "Active" 00 "Inactive" ;
VAL_ 2556362769 P1_BalSwCell122 01 "Active" 00 "Inactive" ;
VAL_ 2556362769 P1_BalSwCell123 01 "Active" 00 "Inactive" ;
VAL_ 2556362769 P1_BalSwCell124 01 "Active" 00 "Inactive" ;
VAL_ 2556428305 P1_BalSwCell125 01 "Active" 00 "Inactive" ;
VAL_ 2556428305 P1_BalSwCell126 01 "Active" 00 "Inactive" ;
VAL_ 2556428305 P1_BalSwCell127 01 "Active" 00 "Inactive" ;
VAL_ 2556428305 P1_BalSwCell128 01 "Active" 00 "Inactive" ;
VAL_ 2556493841 P1_BalSwCell129 01 "Active" 00 "Inactive" ;
VAL_ 2556493841 P1_BalSwCell130 01 "Active" 00 "Inactive" ;
VAL_ 2556493841 P1_BalSwCell131 01 "Active" 00 "Inactive" ;
VAL_ 2556493841 P1_BalSwCell132 01 "Active" 00 "Inactive" ;
VAL_ 2556559377 P1_BalSwCell133 01 "Active" 00 "Inactive" ;
VAL_ 2556559377 P1_BalSwCell134 01 "Active" 00 "Inactive" ;
VAL_ 2556559377 P1_BalSwCell135 01 "Active" 00 "Inactive" ;
VAL_ 2556559377 P1_BalSwCell136 01 "Active" 00 "Inactive" ;
VAL_ 2556624913 P1_BalSwCell137 01 "Active" 00 "Inactive" ;
VAL_ 2556624913 P1_BalSwCell138 01 "Active" 00 "Inactive" ;
VAL_ 2556624913 P1_BalSwCell139 01 "Active" 00 "Inactive" ;
VAL_ 2556624913 P1_BalSwCell140 01 "Active" 00 "Inactive" ;
VAL_ 2556690449 P1_BalSwCell141 01 "Active" 00 "Inactive" ;
VAL_ 2556690449 P1_BalSwCell142 01 "Active" 00 "Inactive" ;
VAL_ 2556690449 P1_BalSwCell143 01 "Active" 00 "Inactive" ;
VAL_ 2556690449 P1_BalSwCell144 01 "Active" 00 "Inactive" ;
VAL_ 2556755985 P1_BalSwCell145 01 "Active" 00 "Inactive" ;
VAL_ 2556755985 P1_BalSwCell146 01 "Active" 00 "Inactive" ;
VAL_ 2556755985 P1_BalSwCell147 01 "Active" 00 "Inactive" ;
VAL_ 2556755985 P1_BalSwCell148 01 "Active" 00 "Inactive" ;
VAL_ 2556821521 P1_BalSwCell149 01 "Active" 00 "Inactive" ;
VAL_ 2556821521 P1_BalSwCell150 01 "Active" 00 "Inactive" ;
VAL_ 2556821521 P1_BalSwCell151 01 "Active" 00 "Inactive" ;
VAL_ 2556821521 P1_BalSwCell152 01 "Active" 00 "Inactive" ;
VAL_ 2556887057 P1_BalSwCell153 01 "Active" 00 "Inactive" ;
VAL_ 2556887057 P1_BalSwCell154 01 "Active" 00 "Inactive" ;
VAL_ 2556887057 P1_BalSwCell155 01 "Active" 00 "Inactive" ;
VAL_ 2556887057 P1_BalSwCell156 01 "Active" 00 "Inactive" ;
VAL_ 2556952593 P1_BalSwCell157 01 "Active" 00 "Inactive" ;
VAL_ 2556952593 P1_BalSwCell158 01 "Active" 00 "Inactive" ;
VAL_ 2556952593 P1_BalSwCell159 01 "Active" 00 "Inactive" ;
VAL_ 2556952593 P1_BalSwCell160 01 "Active" 00 "Inactive" ;
VAL_ 2557018129 P1_BalSwCell161 01 "Active" 00 "Inactive" ;
VAL_ 2557018129 P1_BalSwCell162 01 "Active" 00 "Inactive" ;
VAL_ 2557018129 P1_BalSwCell163 01 "Active" 00 "Inactive" ;
VAL_ 2557018129 P1_BalSwCell164 01 "Active" 00 "Inactive" ;
VAL_ 2557083665 P1_BalSwCell165 01 "Active" 00 "Inactive" ;
VAL_ 2557083665 P1_BalSwCell166 01 "Active" 00 "Inactive" ;
VAL_ 2557083665 P1_BalSwCell167 01 "Active" 00 "Inactive" ;
VAL_ 2557083665 P1_BalSwCell168 01 "Active" 00 "Inactive" ;
VAL_ 2557149201 P1_BalSwCell169 01 "Active" 00 "Inactive" ;
VAL_ 2557149201 P1_BalSwCell170 01 "Active" 00 "Inactive" ;
VAL_ 2557149201 P1_BalSwCell171 01 "Active" 00 "Inactive" ;
VAL_ 2557149201 P1_BalSwCell172 01 "Active" 00 "Inactive" ;
VAL_ 2557214737 P1_BalSwCell173 01 "Active" 00 "Inactive" ;
VAL_ 2557214737 P1_BalSwCell174 01 "Active" 00 "Inactive" ;
VAL_ 2557214737 P1_BalSwCell175 01 "Active" 00 "Inactive" ;
VAL_ 2557214737 P1_BalSwCell176 01 "Active" 00 "Inactive" ;
VAL_ 2557280273 P1_BalSwCell177 01 "Active" 00 "Inactive" ;
VAL_ 2557280273 P1_BalSwCell178 01 "Active" 00 "Inactive" ;
VAL_ 2557280273 P1_BalSwCell179 01 "Active" 00 "Inactive" ;
VAL_ 2557280273 P1_BalSwCell180 01 "Active" 00 "Inactive" ;
VAL_ 2557345809 P1_BalSwCell181 01 "Active" 00 "Inactive" ;
VAL_ 2557345809 P1_BalSwCell182 01 "Active" 00 "Inactive" ;
VAL_ 2557345809 P1_BalSwCell183 01 "Active" 00 "Inactive" ;
VAL_ 2557345809 P1_BalSwCell184 01 "Active" 00 "Inactive" ;
VAL_ 2557411345 P1_BalSwCell185 01 "Active" 00 "Inactive" ;
VAL_ 2557411345 P1_BalSwCell186 01 "Active" 00 "Inactive" ;
VAL_ 2557411345 P1_BalSwCell187 01 "Active" 00 "Inactive" ;
VAL_ 2557411345 P1_BalSwCell188 01 "Active" 00 "Inactive" ;
VAL_ 2557476881 P1_BalSwCell189 01 "Active" 00 "Inactive" ;
VAL_ 2557476881 P1_BalSwCell190 01 "Active" 00 "Inactive" ;
VAL_ 2557476881 P1_BalSwCell191 01 "Active" 00 "Inactive" ;
VAL_ 2557476881 P1_BalSwCell192 01 "Active" 00 "Inactive" ;
VAL_ 2550399010 P2_BMSKL15ON 01 "On" 00 "Off" ;
VAL_ 2550530082 P2_PackDschrgPwrStat 02 "鎸佺画鏀剧數鍔熺巼" 01 "30s鏀剧數鍔熺巼" 00 "10s鏀剧數鍔熺巼" ;
VAL_ 2550530082 P2_PackChrgPwrStat 02 "鎸佺画鍏呯數鍔熺巼" 01 "30s鍏呯數鍔熺巼" 00 "10s鍏呯數鍔熺巼" ;
VAL_ 2550595618 P2_ChrgrCplrStat 01 "Connected" 00 "Disconnected" ;
VAL_ 2550595618 P2_HVBattChrgSysStatus 04 "Aborted" 03 "Complete" 02 "Active" 01 "Initialization" 00 "Default" ;
VAL_ 2550857762 P2_CellOverVoltage 03 "Level 3" 02 "Level 2" 01 "Level 1" 00 "No Fault" ;
VAL_ 2550857762 P2_CellUnderVoltage 03 "Level 3" 02 "Level 2" 01 "Level 1" 00 "No Fault" ;
VAL_ 2550857762 P2_CellVoltageDiffHi 01 "Fault" 00 "No Fault" ;
VAL_ 2550857762 P2_PackOverVoltage 03 "Level 3" 02 "Level 2" 01 "Level 1" 00 "No Fault" ;
VAL_ 2550857762 P2_PackUnderVoltage 03 "Level 3" 02 "Level 2" 01 "Level 1" 00 "No Fault" ;
VAL_ 2550857762 P2_CellOverTemp 03 "Level 3" 02 "Level 2" 01 "Level 1" 00 "No Fault" ;
VAL_ 2550857762 P2_CellTempLow 01 "Fault" 00 "No Fault" ;
VAL_ 2550857762 P2_CellTempDiffHi 01 "Fault" 00 "No Fault" ;
VAL_ 2550857762 P2_PackDschrgCrntHi 03 "Level 3" 02 "Level 2" 01 "Level 1" 00 "No Fault" ;
VAL_ 2550857762 P2_PackChrgCrntHi 03 "Level 3" 02 "Level 2" 01 "Level 1" 00 "No Fault" ;
VAL_ 2550857762 P2_PackCrnSnsr1OffsetHi 01 "Fault" 00 "No Fault" ;
VAL_ 2550857762 P2_HVIsolFlt 03 "Level 3" 02 "Level 2" 01 "Level 1" 00 "No Fault" ;
VAL_ 2550857762 P2_HVILFlt 01 "Fault" 00 "No Fault" ;
VAL_ 2550857762 P2_ThrmlRunaway 01 "Fault" 00 "No Fault" ;
VAL_ 2550857762 P2_CellVoltInvalid 01 "Fault" 00 "No Fault" ;
VAL_ 2550857762 P2_CellTempInvalid 01 "Fault" 00 "No Fault" ;
VAL_ 2550857762 P2_DaisyChainComFlt 01 "Fault" 00 "No Fault" ;
VAL_ 2550857762 P2_PackVoltRatFlt 01 "Fault" 00 "No Fault" ;
VAL_ 2550857762 P2_CrntSnsr1Invalid 01 "Fault" 00 "No Fault" ;
VAL_ 2550857762 P2_CrntSnsr1OOR 01 "Fault" 00 "No Fault" ;
VAL_ 2550857762 P2_CrntSnsr2Invalid 01 "Fault" 00 "No Fault" ;
VAL_ 2550857762 P2_CrntSnsr2OOR 01 "Fault" 00 "No Fault" ;
VAL_ 2550857762 P2_PackCrnSnsr2OffsetHi 01 "Fault" 00 "No Fault" ;
VAL_ 2550857762 P2_OutofEnergy 01 "Fault" 00 "No Fault" ;
VAL_ 2550857762 P2_IsolDetCircErr 01 "Fault" 00 "No Fault" ;
VAL_ 2550857762 P2_HVILCircShortToGND 01 "Fault" 00 "No Fault" ;
VAL_ 2550857762 P2_HVILCircShortToPwr 01 "Fault" 00 "No Fault" ;
VAL_ 2550923298 P2_MainPosCntctrStkClsd 01 "Fault" 00 "No Fault" ;
VAL_ 2550923298 P2_MainPosCntctrStkOpn 01 "Fault" 00 "No Fault" ;
VAL_ 2550923298 P2_MainNegCntctr1StkClsd 01 "Fault" 00 "No Fault" ;
VAL_ 2550923298 P2_MainNegCntctr1StkOpn 01 "Fault" 00 "No Fault" ;
VAL_ 2550923298 P2_MainNegCntctr2StkClsd 01 "Fault" 00 "No Fault" ;
VAL_ 2550923298 P2_MainNegCntctr2StkOpn 01 "Fault" 00 "No Fault" ;
VAL_ 2550923298 P2_PrechargTmOut 01 "Fault" 00 "No Fault" ;
VAL_ 2550923298 P2_PrechrgCrntHi 01 "Fault" 00 "No Fault" ;
VAL_ 2550923298 P2_ChrgCplrPosTempHi 01 "Fault" 00 "No Fault" ;
VAL_ 2550923298 P2_ChrgCplrNegTempHi 01 "Fault" 00 "No Fault" ;
VAL_ 2550923298 P2_BMSPwrSuplVlt1Hi 01 "Fault" 00 "No Fault" ;
VAL_ 2550923298 P2_BMSPwrSuplVlt1Lo 01 "Fault" 00 "No Fault" ;
VAL_ 2550923298 P2_BMSPwrSuplVlt2Hi 01 "Fault" 00 "No Fault" ;
VAL_ 2550923298 P2_BMSPwrSuplVlt2Lo 01 "Fault" 00 "No Fault" ;
VAL_ 2550923298 P2_CntctrCirPwrSuplVltLo 01 "Fault" 00 "No Fault" ;
VAL_ 2550923298 P2_CntctrCirPwrSuplVltHi 01 "Fault" 00 "No Fault" ;
VAL_ 2550923298 P2_CAN1BusOff 01 "Fault" 00 "No Fault" ;
VAL_ 2550923298 P2_CAN1BusTmOut 01 "Fault" 00 "No Fault" ;
VAL_ 2550923298 P2_CAN2BusOff 01 "Fault" 00 "No Fault" ;
VAL_ 2550923298 P2_CAN2BusTmOut 01 "Fault" 00 "No Fault" ;
VAL_ 2550923298 P2_CellBalCircTempHi 01 "Fault" 00 "No Fault" ;
VAL_ 2550923298 P2_ClntInTempHi 01 "Fault" 00 "No Fault" ;
VAL_ 2550923298 P2_ClntOutTempHi 01 "Fault" 00 "No Fault" ;
VAL_ 2550923298 P2_CellExtrmUdrVolt 01 "Fault" 00 "No Fault" ;
VAL_ 2550923298 P2_CellExtrmOvrVolt 01 "Fault" 00 "No Fault" ;
VAL_ 2550923298 P2_Branch1DischrgCrntHi  01 "Fault" 00 "No Fault" ;
VAL_ 2550923298 P2_Branch2DischrgCrntHi  01 "Fault" 00 "No Fault" ;
VAL_ 2550923298 P2_Branch1ChrgCrntHi  01 "Fault" 00 "No Fault" ;
VAL_ 2550923298 P2_Branch2ChrgCrntHi  01 "Fault" 00 "No Fault" ;
VAL_ 2550923298 P2_InitFailed 01 "Fault" 00 "No Fault" ;
VAL_ 2554396706 P2_BalSwCell1 01 "Active" 00 "Inactive" ;
VAL_ 2554396706 P2_BalSwCell2 01 "Active" 00 "Inactive" ;
VAL_ 2554396706 P2_BalSwCell3 01 "Active" 00 "Inactive" ;
VAL_ 2554396706 P2_BalSwCell4 01 "Active" 00 "Inactive" ;
VAL_ 2554462242 P2_BalSwCell5 01 "Active" 00 "Inactive" ;
VAL_ 2554462242 P2_BalSwCell6 01 "Active" 00 "Inactive" ;
VAL_ 2554462242 P2_BalSwCell7 01 "Active" 00 "Inactive" ;
VAL_ 2554462242 P2_BalSwCell8 01 "Active" 00 "Inactive" ;
VAL_ 2554527778 P2_BalSwCell9 01 "Active" 00 "Inactive" ;
VAL_ 2554527778 P2_BalSwCell10 01 "Active" 00 "Inactive" ;
VAL_ 2554527778 P2_BalSwCell11 01 "Active" 00 "Inactive" ;
VAL_ 2554527778 P2_BalSwCell12 01 "Active" 00 "Inactive" ;
VAL_ 2554593314 P2_BalSwCell13 01 "Active" 00 "Inactive" ;
VAL_ 2554593314 P2_BalSwCell14 01 "Active" 00 "Inactive" ;
VAL_ 2554593314 P2_BalSwCell15 01 "Active" 00 "Inactive" ;
VAL_ 2554593314 P2_BalSwCell16 01 "Active" 00 "Inactive" ;
VAL_ 2554658850 P2_BalSwCell17 01 "Active" 00 "Inactive" ;
VAL_ 2554658850 P2_BalSwCell18 01 "Active" 00 "Inactive" ;
VAL_ 2554658850 P2_BalSwCell19 01 "Active" 00 "Inactive" ;
VAL_ 2554658850 P2_BalSwCell20 01 "Active" 00 "Inactive" ;
VAL_ 2554724386 P2_BalSwCell21 01 "Active" 00 "Inactive" ;
VAL_ 2554724386 P2_BalSwCell22 01 "Active" 00 "Inactive" ;
VAL_ 2554724386 P2_BalSwCell23 01 "Active" 00 "Inactive" ;
VAL_ 2554724386 P2_BalSwCell24 01 "Active" 00 "Inactive" ;
VAL_ 2554789922 P2_BalSwCell25 01 "Active" 00 "Inactive" ;
VAL_ 2554789922 P2_BalSwCell26 01 "Active" 00 "Inactive" ;
VAL_ 2554789922 P2_BalSwCell27 01 "Active" 00 "Inactive" ;
VAL_ 2554789922 P2_BalSwCell28 01 "Active" 00 "Inactive" ;
VAL_ 2554855458 P2_BalSwCell29 01 "Active" 00 "Inactive" ;
VAL_ 2554855458 P2_BalSwCell30 01 "Active" 00 "Inactive" ;
VAL_ 2554855458 P2_BalSwCell31 01 "Active" 00 "Inactive" ;
VAL_ 2554855458 P2_BalSwCell32 01 "Active" 00 "Inactive" ;
VAL_ 2554920994 P2_BalSwCell33 01 "Active" 00 "Inactive" ;
VAL_ 2554920994 P2_BalSwCell34 01 "Active" 00 "Inactive" ;
VAL_ 2554920994 P2_BalSwCell35 01 "Active" 00 "Inactive" ;
VAL_ 2554920994 P2_BalSwCell36 01 "Active" 00 "Inactive" ;
VAL_ 2554986530 P2_BalSwCell37 01 "Active" 00 "Inactive" ;
VAL_ 2554986530 P2_BalSwCell38 01 "Active" 00 "Inactive" ;
VAL_ 2554986530 P2_BalSwCell39 01 "Active" 00 "Inactive" ;
VAL_ 2554986530 P2_BalSwCell40 01 "Active" 00 "Inactive" ;
VAL_ 2555052066 P2_BalSwCell41 01 "Active" 00 "Inactive" ;
VAL_ 2555052066 P2_BalSwCell42 01 "Active" 00 "Inactive" ;
VAL_ 2555052066 P2_BalSwCell43 01 "Active" 00 "Inactive" ;
VAL_ 2555052066 P2_BalSwCell44 01 "Active" 00 "Inactive" ;
VAL_ 2555117602 P2_BalSwCell45 01 "Active" 00 "Inactive" ;
VAL_ 2555117602 P2_BalSwCell46 01 "Active" 00 "Inactive" ;
VAL_ 2555117602 P2_BalSwCell47 01 "Active" 00 "Inactive" ;
VAL_ 2555117602 P2_BalSwCell48 01 "Active" 00 "Inactive" ;
VAL_ 2555183138 P2_BalSwCell49 01 "Active" 00 "Inactive" ;
VAL_ 2555183138 P2_BalSwCell50 01 "Active" 00 "Inactive" ;
VAL_ 2555183138 P2_BalSwCell51 01 "Active" 00 "Inactive" ;
VAL_ 2555183138 P2_BalSwCell52 01 "Active" 00 "Inactive" ;
VAL_ 2555248674 P2_BalSwCell53 01 "Active" 00 "Inactive" ;
VAL_ 2555248674 P2_BalSwCell54 01 "Active" 00 "Inactive" ;
VAL_ 2555248674 P2_BalSwCell55 01 "Active" 00 "Inactive" ;
VAL_ 2555248674 P2_BalSwCell56 01 "Active" 00 "Inactive" ;
VAL_ 2555314210 P2_BalSwCell57 01 "Active" 00 "Inactive" ;
VAL_ 2555314210 P2_BalSwCell58 01 "Active" 00 "Inactive" ;
VAL_ 2555314210 P2_BalSwCell59 01 "Active" 00 "Inactive" ;
VAL_ 2555314210 P2_BalSwCell60 01 "Active" 00 "Inactive" ;
VAL_ 2555379746 P2_BalSwCell61 01 "Active" 00 "Inactive" ;
VAL_ 2555379746 P2_BalSwCell62 01 "Active" 00 "Inactive" ;
VAL_ 2555379746 P2_BalSwCell63 01 "Active" 00 "Inactive" ;
VAL_ 2555379746 P2_BalSwCell64 01 "Active" 00 "Inactive" ;
VAL_ 2555445282 P2_BalSwCell65 01 "Active" 00 "Inactive" ;
VAL_ 2555445282 P2_BalSwCell66 01 "Active" 00 "Inactive" ;
VAL_ 2555445282 P2_BalSwCell67 01 "Active" 00 "Inactive" ;
VAL_ 2555445282 P2_BalSwCell68 01 "Active" 00 "Inactive" ;
VAL_ 2555510818 P2_BalSwCell69 01 "Active" 00 "Inactive" ;
VAL_ 2555510818 P2_BalSwCell70 01 "Active" 00 "Inactive" ;
VAL_ 2555510818 P2_BalSwCell71 01 "Active" 00 "Inactive" ;
VAL_ 2555510818 P2_BalSwCell72 01 "Active" 00 "Inactive" ;
VAL_ 2555576354 P2_BalSwCell73 01 "Active" 00 "Inactive" ;
VAL_ 2555576354 P2_BalSwCell74 01 "Active" 00 "Inactive" ;
VAL_ 2555576354 P2_BalSwCell75 01 "Active" 00 "Inactive" ;
VAL_ 2555576354 P2_BalSwCell76 01 "Active" 00 "Inactive" ;
VAL_ 2555641890 P2_BalSwCell77 01 "Active" 00 "Inactive" ;
VAL_ 2555641890 P2_BalSwCell78 01 "Active" 00 "Inactive" ;
VAL_ 2555641890 P2_BalSwCell79 01 "Active" 00 "Inactive" ;
VAL_ 2555641890 P2_BalSwCell80 01 "Active" 00 "Inactive" ;
VAL_ 2555707426 P2_BalSwCell81 01 "Active" 00 "Inactive" ;
VAL_ 2555707426 P2_BalSwCell82 01 "Active" 00 "Inactive" ;
VAL_ 2555707426 P2_BalSwCell83 01 "Active" 00 "Inactive" ;
VAL_ 2555707426 P2_BalSwCell84 01 "Active" 00 "Inactive" ;
VAL_ 2555772962 P2_BalSwCell85 01 "Active" 00 "Inactive" ;
VAL_ 2555772962 P2_BalSwCell86 01 "Active" 00 "Inactive" ;
VAL_ 2555772962 P2_BalSwCell87 01 "Active" 00 "Inactive" ;
VAL_ 2555772962 P2_BalSwCell88 01 "Active" 00 "Inactive" ;
VAL_ 2555838498 P2_BalSwCell89 01 "Active" 00 "Inactive" ;
VAL_ 2555838498 P2_BalSwCell90 01 "Active" 00 "Inactive" ;
VAL_ 2555838498 P2_BalSwCell91 01 "Active" 00 "Inactive" ;
VAL_ 2555838498 P2_BalSwCell92 01 "Active" 00 "Inactive" ;
VAL_ 2555904034 P2_BalSwCell93 01 "Active" 00 "Inactive" ;
VAL_ 2555904034 P2_BalSwCell94 01 "Active" 00 "Inactive" ;
VAL_ 2555904034 P2_BalSwCell95 01 "Active" 00 "Inactive" ;
VAL_ 2555904034 P2_BalSwCell96 01 "Active" 00 "Inactive" ;
VAL_ 2555969570 P2_BalSwCell97 01 "Active" 00 "Inactive" ;
VAL_ 2555969570 P2_BalSwCell98 01 "Active" 00 "Inactive" ;
VAL_ 2555969570 P2_BalSwCell99 01 "Active" 00 "Inactive" ;
VAL_ 2555969570 P2_BalSwCell100 01 "Active" 00 "Inactive" ;
VAL_ 2556035106 P2_BalSwCell101 01 "Active" 00 "Inactive" ;
VAL_ 2556035106 P2_BalSwCell102 01 "Active" 00 "Inactive" ;
VAL_ 2556035106 P2_BalSwCell103 01 "Active" 00 "Inactive" ;
VAL_ 2556035106 P2_BalSwCell104 01 "Active" 00 "Inactive" ;
VAL_ 2556100642 P2_BalSwCell105 01 "Active" 00 "Inactive" ;
VAL_ 2556100642 P2_BalSwCell106 01 "Active" 00 "Inactive" ;
VAL_ 2556100642 P2_BalSwCell107 01 "Active" 00 "Inactive" ;
VAL_ 2556100642 P2_BalSwCell108 01 "Active" 00 "Inactive" ;
VAL_ 2556166178 P2_BalSwCell109 01 "Active" 00 "Inactive" ;
VAL_ 2556166178 P2_BalSwCell110 01 "Active" 00 "Inactive" ;
VAL_ 2556166178 P2_BalSwCell111 01 "Active" 00 "Inactive" ;
VAL_ 2556166178 P2_BalSwCell112 01 "Active" 00 "Inactive" ;
VAL_ 2556231714 P2_BalSwCell113 01 "Active" 00 "Inactive" ;
VAL_ 2556231714 P2_BalSwCell114 01 "Active" 00 "Inactive" ;
VAL_ 2556231714 P2_BalSwCell115 01 "Active" 00 "Inactive" ;
VAL_ 2556231714 P2_BalSwCell116 01 "Active" 00 "Inactive" ;
VAL_ 2556297250 P2_BalSwCell117 01 "Active" 00 "Inactive" ;
VAL_ 2556297250 P2_BalSwCell118 01 "Active" 00 "Inactive" ;
VAL_ 2556297250 P2_BalSwCell119 01 "Active" 00 "Inactive" ;
VAL_ 2556297250 P2_BalSwCell120 01 "Active" 00 "Inactive" ;
VAL_ 2556362786 P2_BalSwCell121 01 "Active" 00 "Inactive" ;
VAL_ 2556362786 P2_BalSwCell122 01 "Active" 00 "Inactive" ;
VAL_ 2556362786 P2_BalSwCell123 01 "Active" 00 "Inactive" ;
VAL_ 2556362786 P2_BalSwCell124 01 "Active" 00 "Inactive" ;
VAL_ 2556428322 P2_BalSwCell125 01 "Active" 00 "Inactive" ;
VAL_ 2556428322 P2_BalSwCell126 01 "Active" 00 "Inactive" ;
VAL_ 2556428322 P2_BalSwCell127 01 "Active" 00 "Inactive" ;
VAL_ 2556428322 P2_BalSwCell128 01 "Active" 00 "Inactive" ;
VAL_ 2556493858 P2_BalSwCell129 01 "Active" 00 "Inactive" ;
VAL_ 2556493858 P2_BalSwCell130 01 "Active" 00 "Inactive" ;
VAL_ 2556493858 P2_BalSwCell131 01 "Active" 00 "Inactive" ;
VAL_ 2556493858 P2_BalSwCell132 01 "Active" 00 "Inactive" ;
VAL_ 2556559394 P2_BalSwCell133 01 "Active" 00 "Inactive" ;
VAL_ 2556559394 P2_BalSwCell134 01 "Active" 00 "Inactive" ;
VAL_ 2556559394 P2_BalSwCell135 01 "Active" 00 "Inactive" ;
VAL_ 2556559394 P2_BalSwCell136 01 "Active" 00 "Inactive" ;
VAL_ 2556624930 P2_BalSwCell137 01 "Active" 00 "Inactive" ;
VAL_ 2556624930 P2_BalSwCell138 01 "Active" 00 "Inactive" ;
VAL_ 2556624930 P2_BalSwCell139 01 "Active" 00 "Inactive" ;
VAL_ 2556624930 P2_BalSwCell140 01 "Active" 00 "Inactive" ;
VAL_ 2556690466 P2_BalSwCell141 01 "Active" 00 "Inactive" ;
VAL_ 2556690466 P2_BalSwCell142 01 "Active" 00 "Inactive" ;
VAL_ 2556690466 P2_BalSwCell143 01 "Active" 00 "Inactive" ;
VAL_ 2556690466 P2_BalSwCell144 01 "Active" 00 "Inactive" ;
VAL_ 2556756002 P2_BalSwCell145 01 "Active" 00 "Inactive" ;
VAL_ 2556756002 P2_BalSwCell146 01 "Active" 00 "Inactive" ;
VAL_ 2556756002 P2_BalSwCell147 01 "Active" 00 "Inactive" ;
VAL_ 2556756002 P2_BalSwCell148 01 "Active" 00 "Inactive" ;
VAL_ 2556821538 P2_BalSwCell149 01 "Active" 00 "Inactive" ;
VAL_ 2556821538 P2_BalSwCell150 01 "Active" 00 "Inactive" ;
VAL_ 2556821538 P2_BalSwCell151 01 "Active" 00 "Inactive" ;
VAL_ 2556821538 P2_BalSwCell152 01 "Active" 00 "Inactive" ;
VAL_ 2556887074 P2_BalSwCell153 01 "Active" 00 "Inactive" ;
VAL_ 2556887074 P2_BalSwCell154 01 "Active" 00 "Inactive" ;
VAL_ 2556887074 P2_BalSwCell155 01 "Active" 00 "Inactive" ;
VAL_ 2556887074 P2_BalSwCell156 01 "Active" 00 "Inactive" ;
VAL_ 2556952610 P2_BalSwCell157 01 "Active" 00 "Inactive" ;
VAL_ 2556952610 P2_BalSwCell158 01 "Active" 00 "Inactive" ;
VAL_ 2556952610 P2_BalSwCell159 01 "Active" 00 "Inactive" ;
VAL_ 2556952610 P2_BalSwCell160 01 "Active" 00 "Inactive" ;
VAL_ 2557018146 P2_BalSwCell161 01 "Active" 00 "Inactive" ;
VAL_ 2557018146 P2_BalSwCell162 01 "Active" 00 "Inactive" ;
VAL_ 2557018146 P2_BalSwCell163 01 "Active" 00 "Inactive" ;
VAL_ 2557018146 P2_BalSwCell164 01 "Active" 00 "Inactive" ;
VAL_ 2557083682 P2_BalSwCell165 01 "Active" 00 "Inactive" ;
VAL_ 2557083682 P2_BalSwCell166 01 "Active" 00 "Inactive" ;
VAL_ 2557083682 P2_BalSwCell167 01 "Active" 00 "Inactive" ;
VAL_ 2557083682 P2_BalSwCell168 01 "Active" 00 "Inactive" ;
VAL_ 2557149218 P2_BalSwCell169 01 "Active" 00 "Inactive" ;
VAL_ 2557149218 P2_BalSwCell170 01 "Active" 00 "Inactive" ;
VAL_ 2557149218 P2_BalSwCell171 01 "Active" 00 "Inactive" ;
VAL_ 2557149218 P2_BalSwCell172 01 "Active" 00 "Inactive" ;
VAL_ 2557214754 P2_BalSwCell173 01 "Active" 00 "Inactive" ;
VAL_ 2557214754 P2_BalSwCell174 01 "Active" 00 "Inactive" ;
VAL_ 2557214754 P2_BalSwCell175 01 "Active" 00 "Inactive" ;
VAL_ 2557214754 P2_BalSwCell176 01 "Active" 00 "Inactive" ;
VAL_ 2557280290 P2_BalSwCell177 01 "Active" 00 "Inactive" ;
VAL_ 2557280290 P2_BalSwCell178 01 "Active" 00 "Inactive" ;
VAL_ 2557280290 P2_BalSwCell179 01 "Active" 00 "Inactive" ;
VAL_ 2557280290 P2_BalSwCell180 01 "Active" 00 "Inactive" ;
VAL_ 2557345826 P2_BalSwCell181 01 "Active" 00 "Inactive" ;
VAL_ 2557345826 P2_BalSwCell182 01 "Active" 00 "Inactive" ;
VAL_ 2557345826 P2_BalSwCell183 01 "Active" 00 "Inactive" ;
VAL_ 2557345826 P2_BalSwCell184 01 "Active" 00 "Inactive" ;
VAL_ 2557411362 P2_BalSwCell185 01 "Active" 00 "Inactive" ;
VAL_ 2557411362 P2_BalSwCell186 01 "Active" 00 "Inactive" ;
VAL_ 2557411362 P2_BalSwCell187 01 "Active" 00 "Inactive" ;
VAL_ 2557411362 P2_BalSwCell188 01 "Active" 00 "Inactive" ;
VAL_ 2557476898 P2_BalSwCell189 01 "Active" 00 "Inactive" ;
VAL_ 2557476898 P2_BalSwCell190 01 "Active" 00 "Inactive" ;
VAL_ 2557476898 P2_BalSwCell191 01 "Active" 00 "Inactive" ;
VAL_ 2557476898 P2_BalSwCell192 01 "Active" 00 "Inactive" ;
VAL_ 2550399027 P3_BMSKL15ON 01 "On" 00 "Off" ;
